VERSION "10.9.1"

NS_ :

BS_:

BU_: ACM ADAS_Body APM ASU_Gateway BCM BCM_BPM CCU_F CCU_R DUMMY_BCM_BPM DUMMY_ECU ETG LDM_L LDM_R OCS_P PSM_D SHVU_F SHVU_R TRM XGW_Body

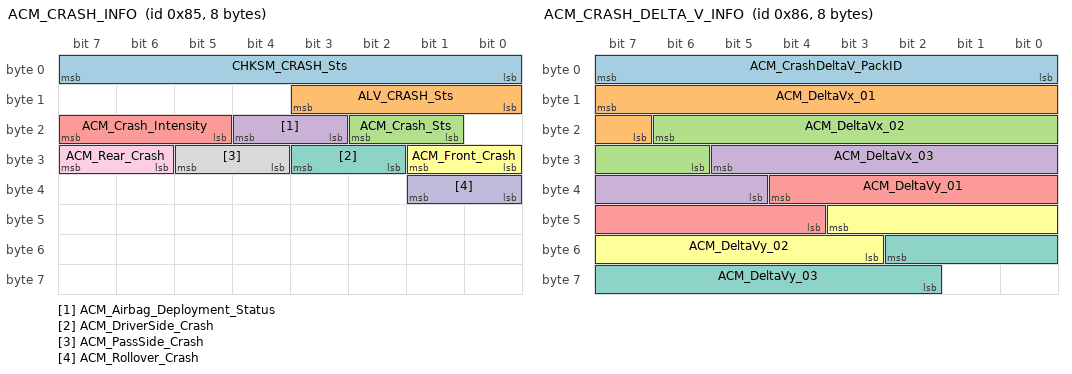
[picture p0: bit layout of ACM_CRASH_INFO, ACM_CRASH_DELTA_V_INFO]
BO_ 133 ACM_CRASH_INFO: 8 ACM
 SG_ CHKSM_CRASH_Sts : 7|8@0+ (1,0) [0|255] ""  BCM,ETG,XGW_Body
 SG_ ALV_CRASH_Sts : 11|4@0+ (1,0) [0|14] ""  BCM,ETG,XGW_Body
 SG_ ACM_Crash_Sts : 18|2@0+ (1,0) [0|3] ""  BCM,CCU_F,ETG,XGW_Body
 SG_ ACM_Airbag_Deployment_Status : 20|2@0+ (1,0) [0|3] "-"  ETG,XGW_Body
 SG_ ACM_Crash_Intensity : 23|3@0+ (1,0) [0|7] ""  CCU_F,ETG,XGW_Body
 SG_ ACM_Front_Crash : 25|2@0+ (1,0) [0|3] "-"  BCM,ETG,XGW_Body
 SG_ ACM_DriverSide_Crash : 27|2@0+ (1,0) [0|3] ""  BCM,ETG,XGW_Body
 SG_ ACM_PassSide_Crash : 29|2@0+ (1,0) [0|3] "-"  BCM,ETG,XGW_Body
 SG_ ACM_Rear_Crash : 31|2@0+ (1,0) [0|3] "-"  BCM,ETG,XGW_Body
 SG_ ACM_Rollover_Crash : 33|2@0+ (1,0) [0|3] "-"  BCM,ETG,XGW_Body

BO_ 134 ACM_CRASH_DELTA_V_INFO: 8 ACM
 SG_ ACM_CrashDeltaV_PackID : 7|8@0+ (1,0) [1|9] ""  XGW_Body
 SG_ ACM_DeltaVx_01 : 15|9@0+ (1,-250) [-250|250] "Km/h"  XGW_Body
 SG_ ACM_DeltaVx_02 : 22|9@0+ (1,-250) [-250|250] "Km/h"  XGW_Body
 SG_ ACM_DeltaVx_03 : 29|9@0+ (1,-250) [-250|250] "Km/h"  XGW_Body
 SG_ ACM_DeltaVy_01 : 36|9@0+ (1,-250) [-250|250] "Km/h"  XGW_Body
 SG_ ACM_DeltaVy_02 : 43|9@0+ (1,-250) [-250|250] "Km/h"  XGW_Body
 SG_ ACM_DeltaVy_03 : 50|9@0+ (1,-250) [-250|250] "Km/h"  XGW_Body

BO_ 149 IDB_FUNCTION: 8 XGW_Body
 SG_ CHKSM_IDB_FUNCTION : 7|8@0+ (1,0) [0|255] ""  ACM,BCM,DUMMY_ECU
 SG_ ALV_IDB_FUNCTION : 11|4@0+ (1,0) [0|14] ""  ACM,BCM,DUMMY_ECU
 SG_ STAT_ABS : 13|2@0+ (1,0) [0|3] ""  DUMMY_ECU
 SG_ ABS_Active : 15|2@0+ (1,0) [0|3] ""  DUMMY_ECU
 SG_ AYC_Active : 17|2@0+ (1,0) [0|3] "Bit"  DUMMY_ECU
 SG_ ASR_Active : 19|2@0+ (1,0) [0|3] "-"  DUMMY_ECU
 SG_ STAT_DSC : 21|2@0+ (1,0) [0|3] "-"  ACM
 SG_ DSC_Active : 23|2@0+ (1,0) [0|3] ""  DUMMY_ECU
 SG_ HBA_ActiveSignal : 25|2@0+ (1,0) [0|3] ""  DUMMY_ECU
 SG_ ARM_ActiveSignal : 27|2@0+ (1,0) [0|3] "-"  DUMMY_ECU
 SG_ STAT_AutoHazardBlinking : 29|2@0+ (1,0) [0|3] "Bit"  BCM
 SG_ MSR_Active : 31|2@0+ (1,0) [0|3] "-"  DUMMY_ECU
 SG_ HSA_ActiveSignal : 33|2@0+ (1,0) [0|3] ""  DUMMY_ECU
 SG_ EPBi_ECD_ActiveSignal : 35|2@0+ (1,0) [0|3] ""  DUMMY_ECU
 SG_ TSM_Active : 37|2@0+ (1,0) [0|3] "-"  DUMMY_ECU
 SG_ HAS_Available : 41|2@0+ (1,0) [0|3] ""  DUMMY_ECU
 SG_ STAT_EBD : 43|2@0+ (1,0) [0|3] ""  DUMMY_ECU
 SG_ EBD_Active : 45|2@0+ (1,0) [0|3] ""  DUMMY_ECU
 SG_ ST_BRG_MSA : 55|4@0+ (1,0) [0|15] ""  DUMMY_ECU

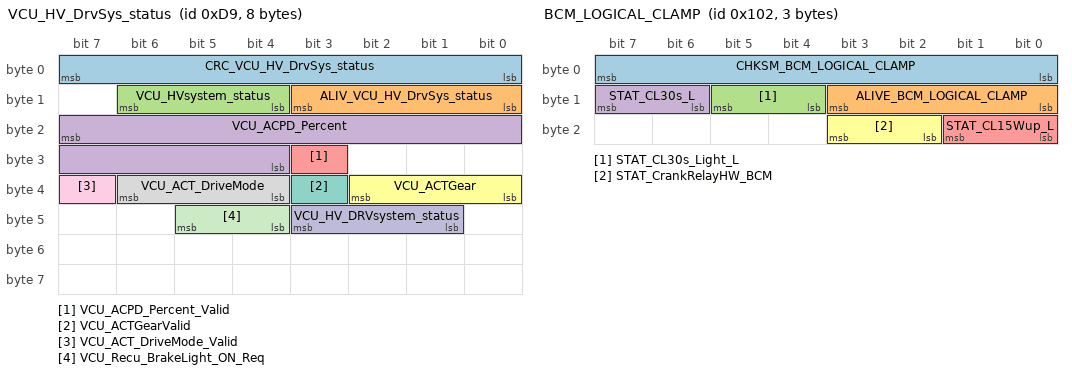
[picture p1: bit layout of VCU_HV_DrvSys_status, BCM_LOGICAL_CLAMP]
BO_ 217 VCU_HV_DrvSys_status: 8 XGW_Body
 SG_ CRC_VCU_HV_DrvSys_status : 7|8@0+ (1,0) [0|255] ""  ACM,BCM,LDM_L,LDM_R
 SG_ ALIV_VCU_HV_DrvSys_status : 11|4@0+ (1,0) [0|14] ""  ACM,BCM,LDM_L,LDM_R
 SG_ VCU_HVsystem_status : 14|3@0+ (1,0) [0|7] "-"  ACM,BCM
 SG_ VCU_ACPD_Percent : 23|12@0+ (0.0625,0) [0|100] "%"  ACM
 SG_ VCU_ACPD_Percent_Valid : 27|1@0+ (1,0) [0|1] ""  ACM
 SG_ VCU_ACTGear : 34|3@0+ (1,0) [0|7] ""  BCM,LDM_L,LDM_R
 SG_ VCU_ACTGearValid : 35|1@0+ (1,0) [0|1] ""  BCM,LDM_L,LDM_R
 SG_ VCU_ACT_DriveMode : 38|3@0+ (1,0) [0|7] ""  BCM
 SG_ VCU_ACT_DriveMode_Valid : 39|1@0+ (1,0) [0|1] "-"  BCM
 SG_ VCU_HV_DRVsystem_status : 43|3@0+ (1,0) [0|7] ""  BCM
 SG_ VCU_Recu_BrakeLight_ON_Req : 45|2@0+ (1,0) [0|3] "-"  BCM

BO_ 256 MHU_Vehicle_Info: 8 XGW_Body
 SG_ CHKSM_MHU_VEH_INFO : 7|8@0+ (1,0) [0|255] ""  BCM
 SG_ ALV_MHU_VEH_INFO : 11|4@0+ (1,0) [0|14] ""  BCM
 SG_ MHU_UserProfileId : 23|4@0+ (1,0) [0|15] "-"  BCM
 SG_ MHU_Connectivity_Status : 47|3@0+ (1,0) [0|7] ""  BCM

BO_ 258 BCM_LOGICAL_CLAMP: 3 BCM
 SG_ CHKSM_BCM_LOGICAL_CLAMP : 7|8@0+ (1,0) [0|255] ""  ASU_Gateway,XGW_Body
 SG_ ALIVE_BCM_LOGICAL_CLAMP : 11|4@0+ (1,0) [0|14] ""  ASU_Gateway,XGW_Body
 SG_ STAT_CL30s_Light_L : 13|2@0+ (1,0) [0|3] ""  XGW_Body
 SG_ STAT_CL30s_L : 15|2@0+ (1,0) [0|3] "Bit"  ASU_Gateway,XGW_Body
 SG_ STAT_CL15Wup_L : 17|2@0+ (1,0) [0|3] "Bit"  ASU_Gateway,XGW_Body
 SG_ STAT_CrankRelayHW_BCM : 19|2@0+ (1,0) [0|3] "Bit"  XGW_Body

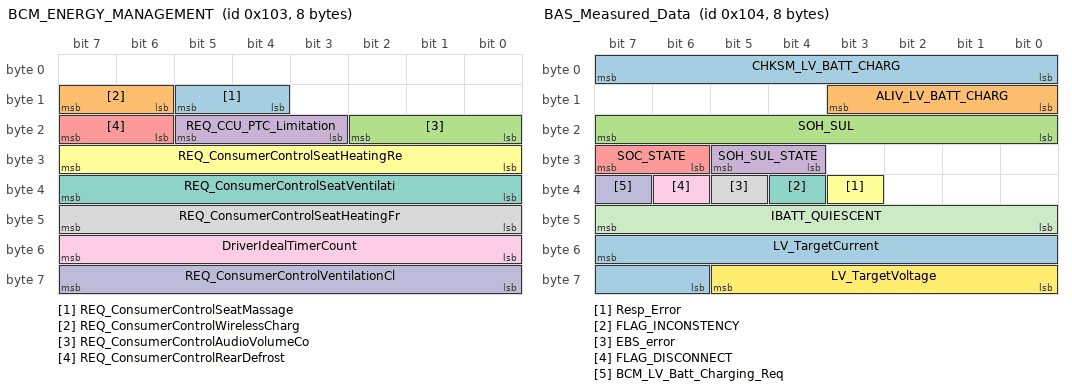
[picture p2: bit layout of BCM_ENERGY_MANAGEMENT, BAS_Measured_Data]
BO_ 259 BCM_ENERGY_MANAGEMENT: 8 BCM
 SG_ REQ_ConsumerControlSeatMassage : 13|2@0+ (1,0) [0|3] "" XGW_Body
 SG_ REQ_ConsumerControlWirelessCharg : 15|2@0+ (1,0) [0|3] "-"  XGW_Body
 SG_ REQ_ConsumerControlAudioVolumeCo : 18|3@0+ (1,0) [0|7] "-"  XGW_Body
 SG_ REQ_CCU_PTC_Limitation : 21|3@0+ (1,0) [0|7] ""  CCU_F,CCU_R
 SG_ REQ_ConsumerControlRearDefrost : 23|2@0+ (1,0) [0|3] "-"  CCU_F,CCU_R,XGW_Body
 SG_ REQ_ConsumerControlSeatHeatingRe : 31|8@0+ (1,0) [0|100] "%"  SHVU_F,SHVU_R,XGW_Body
 SG_ REQ_ConsumerControlSeatVentilati : 39|8@0+ (1,0) [0|100] "%"  SHVU_F,SHVU_R,XGW_Body
 SG_ REQ_ConsumerControlSeatHeatingFr : 47|8@0+ (1,0) [0|100] "%"  SHVU_F,SHVU_R,XGW_Body
 SG_ DriverIdealTimerCount : 55|8@0+ (5,0) [0|1275] "s"  XGW_Body
 SG_ REQ_ConsumerControlVentilationCl : 63|8@0+ (1,0) [0|100] "%"  CCU_F,CCU_R,SHVU_F,SHVU_R,XGW_Body

BO_ 260 BAS_Measured_Data: 8 BCM
 SG_ CHKSM_LV_BATT_CHARG : 7|8@0+ (1,0) [0|255] ""  XGW_Body
 SG_ ALIV_LV_BATT_CHARG : 11|4@0+ (1,0) [0|14] ""  XGW_Body
 SG_ SOH_SUL : 23|8@0+ (1,0) [0|100] "%"  XGW_Body
 SG_ SOH_SUL_STATE : 29|2@0+ (1,0) [0|3] ""  XGW_Body
 SG_ SOC_STATE : 31|2@0+ (1,0) [0|3] "%"  XGW_Body
 SG_ Resp_Error : 35|1@0+ (1,0) [0|1] ""  XGW_Body
 SG_ FLAG_INCONSTENCY : 36|1@0+ (1,0) [0|1] "%"  XGW_Body
 SG_ EBS_error : 37|1@0+ (1,0) [0|1] ""  XGW_Body
 SG_ FLAG_DISCONNECT : 38|1@0+ (1,0) [0|1] ""  XGW_Body
 SG_ BCM_LV_Batt_Charging_Req : 39|1@0+ (1,0) [0|1] ""  XGW_Body
 SG_ IBATT_QUIESCENT : 47|8@0+ (0.00390625,0) [0|0.984375] ""  DUMMY_ECU
 SG_ LV_TargetVoltage : 61|6@0+ (0.112903,9) [9|16] "V" XGW_Body
 SG_ LV_TargetCurrent : 55|10@0+ (0.25,-128) [-128|127] "A" XGW_Body

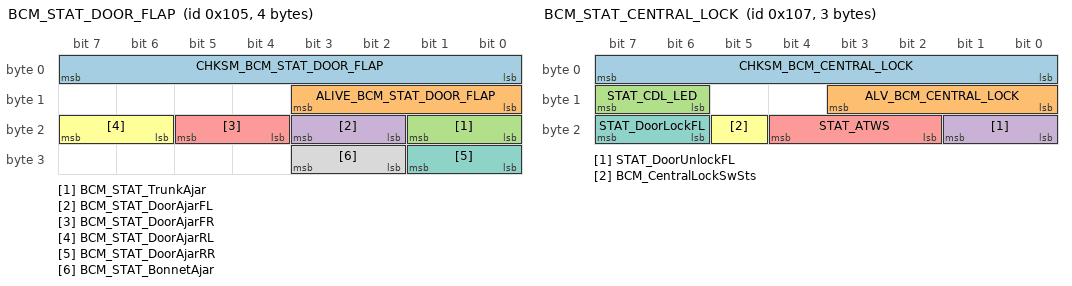
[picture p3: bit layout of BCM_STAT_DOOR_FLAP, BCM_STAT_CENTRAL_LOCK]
BO_ 261 BCM_STAT_DOOR_FLAP: 4 BCM
 SG_ CHKSM_BCM_STAT_DOOR_FLAP : 7|8@0+ (1,0) [0|255] ""  ADAS_Body,APM,ASU_Gateway,CCU_F,CCU_R,XGW_Body
 SG_ ALIVE_BCM_STAT_DOOR_FLAP : 11|4@0+ (1,0) [0|14] ""  ADAS_Body,APM,ASU_Gateway,CCU_F,CCU_R,XGW_Body
 SG_ BCM_STAT_TrunkAjar : 17|2@0+ (1,0) [0|3] "Bit"  ADAS_Body,APM,ASU_Gateway,CCU_R,XGW_Body
 SG_ BCM_STAT_DoorAjarFL : 19|2@0+ (1,0) [0|3] "Bit"  ADAS_Body,APM,ASU_Gateway,CCU_F,CCU_R,XGW_Body
 SG_ BCM_STAT_DoorAjarFR : 21|2@0+ (1,0) [0|3] "Bit"  ADAS_Body,APM,ASU_Gateway,CCU_F,CCU_R,XGW_Body
 SG_ BCM_STAT_DoorAjarRL : 23|2@0+ (1,0) [0|3] "Bit"  ADAS_Body,APM,ASU_Gateway,CCU_F,CCU_R,XGW_Body
 SG_ BCM_STAT_DoorAjarRR : 25|2@0+ (1,0) [0|3] "Bit"  ADAS_Body,APM,ASU_Gateway,CCU_F,CCU_R,XGW_Body
 SG_ BCM_STAT_BonnetAjar : 27|2@0+ (1,0) [0|3] "Bit"  ADAS_Body,APM,XGW_Body

BO_ 262 BCM_LIGHT: 8 BCM
 SG_ CHKSM_BCM_LIGHT : 7|8@0+ (1,0) [0|255] ""  ADAS_Body,APM,CCU_F,LDM_L,LDM_R,XGW_Body
 SG_ ALIVE_BCM_LIGHT : 11|4@0+ (1,0) [0|14] ""  ADAS_Body,APM,CCU_F,LDM_L,LDM_R,XGW_Body
 SG_ BCM_DayRunningLampSts : 13|2@0+ (1,0) [0|3] ""  ADAS_Body,LDM_L,LDM_R,XGW_Body
 SG_ BCM_ReverseLightSts : 15|2@0+ (1,0) [0|3] ""  ADAS_Body,TRM,XGW_Body
 SG_ BCM_StopLightSts : 17|2@0+ (1,0) [0|3] ""  ADAS_Body,TRM,XGW_Body
 SG_ BCM_LicensePlateLightSts : 19|2@0+ (1,0) [0|3] ""  ADAS_Body,XGW_Body
 SG_ BCM_Fr_Dimming_dome_lampSts : 21|2@0+ (1,0) [0|3] ""  ADAS_Body,XGW_Body
 SG_ BCM_Rr_Dimming_dome_lampSts : 23|2@0+ (1,0) [0|3] ""  ADAS_Body,XGW_Body
 SG_ BCM_STAT_InteriorLight : 25|2@0+ (1,0) [0|3] "Bit"  ADAS_Body,XGW_Body
 SG_ BCM_STAT_LightActivation : 28|3@0+ (1,0) [0|7] "-"  ADAS_Body,LDM_L,LDM_R,TRM,XGW_Body
 SG_ BCM_HighBeamSts : 31|2@0+ (1,0) [0|3] ""  ADAS_Body,LDM_L,LDM_R,TRM,XGW_Body
 SG_ BCM_STAT_SwitchLightBrightness : 39|7@0+ (1,0) [0|100] "%"  ADAS_Body,XGW_Body
 SG_ BCM_LowBeamSts : 41|2@0+ (1,0) [0|3] "-"  ADAS_Body,LDM_L,LDM_R,TRM,XGW_Body
 SG_ BCM_RearFogLmpSts : 43|2@0+ (1,0) [0|3] "-"  ADAS_Body,TRM,XGW_Body
 SG_ BCM_FrntFogLmpSts : 45|2@0+ (1,0) [0|3] ""  ADAS_Body,XGW_Body
 SG_ BCM_PosLmpSts : 47|2@0+ (1,0) [0|3] "-"  ADAS_Body,LDM_L,LDM_R,TRM,XGW_Body
 SG_ BCM_BackGrdCl58Sts : 51|2@0+ (1,0) [0|3] ""  DUMMY_ECU
 SG_ BCM_HornSts : 53|2@0+ (1,0) [0|3] ""  XGW_Body
 SG_ BCM_TurnIndicatorSts : 55|2@0+ (1,0) [0|3] ""  ADAS_Body,LDM_L,LDM_R,TRM,XGW_Body

BO_ 263 BCM_STAT_CENTRAL_LOCK: 3 BCM
 SG_ CHKSM_BCM_CENTRAL_LOCK : 7|8@0+ (1,0) [0|255] ""  ADAS_Body,ASU_Gateway,XGW_Body
 SG_ ALV_BCM_CENTRAL_LOCK : 11|4@0+ (1,0) [0|14] ""  ADAS_Body,ASU_Gateway,XGW_Body
 SG_ STAT_CDL_LED : 15|2@0+ (1,0) [0|3] "-"  XGW_Body
 SG_ STAT_DoorUnlockFL : 17|2@0+ (1,0) [0|3] "Bit"  XGW_Body
 SG_ STAT_ATWS : 20|3@0+ (1,0) [0|7] "Bit"  ADAS_Body,XGW_Body
 SG_ BCM_CentralLockSwSts : 21|1@0+ (1,0) [0|0] ""  DUMMY_ECU
 SG_ STAT_DoorLockFL : 23|2@0+ (1,0) [0|3] "Bit"  ADAS_Body,ASU_Gateway,XGW_Body

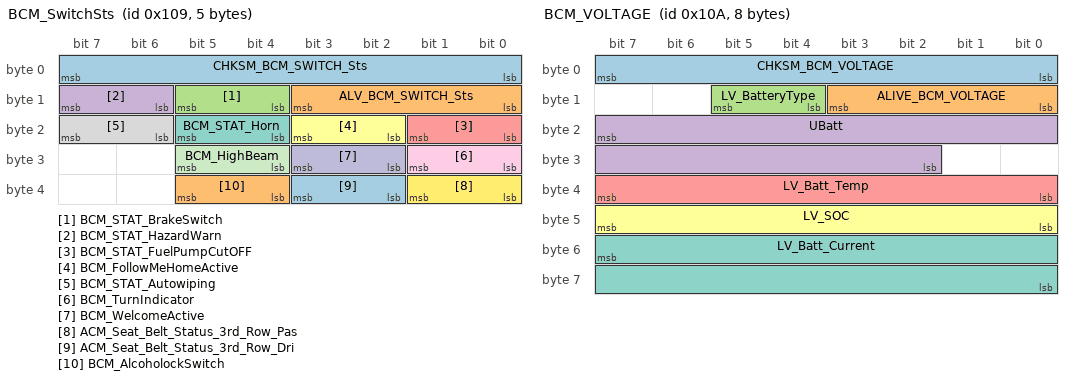
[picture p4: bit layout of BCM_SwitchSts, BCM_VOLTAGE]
BO_ 265 BCM_SwitchSts: 5 BCM
 SG_ CHKSM_BCM_SWITCH_Sts : 7|8@0+ (1,0) [0|255] ""  ACM,ADAS_Body,LDM_L,LDM_R,TRM,XGW_Body
 SG_ ALV_BCM_SWITCH_Sts : 11|4@0+ (1,0) [0|14] ""  ACM,ADAS_Body,LDM_L,LDM_R,TRM,XGW_Body
 SG_ BCM_STAT_BrakeSwitch : 13|2@0+ (1,0) [0|3] ""  ACM,ADAS_Body,TRM,XGW_Body
 SG_ BCM_STAT_HazardWarn : 15|2@0+ (1,0) [0|3] "-"  ADAS_Body,LDM_L,LDM_R,TRM,XGW_Body
 SG_ BCM_STAT_FuelPumpCutOFF : 17|2@0+ (1,0) [0|3] ""  XGW_Body
 SG_ BCM_FollowMeHomeActive : 19|2@0+ (1,0) [0|3] ""  TRM,XGW_Body
 SG_ BCM_STAT_Horn : 21|2@0+ (1,0) [0|3] "-"  XGW_Body
 SG_ BCM_STAT_Autowiping : 23|2@0+ (1,0) [0|3] ""  XGW_Body
 SG_ BCM_TurnIndicator : 25|2@0+ (1,0) [0|3] ""  ADAS_Body,LDM_L,LDM_R,TRM,XGW_Body
 SG_ BCM_WelcomeActive : 27|2@0+ (1,0) [0|3] "-"  TRM,XGW_Body
 SG_ BCM_HighBeam : 29|2@0+ (1,0) [0|3] ""  LDM_L,LDM_R,TRM,XGW_Body
 SG_ ACM_Seat_Belt_Status_3rd_Row_Pas : 33|2@0+ (1,0) [0|3] ""  XGW_Body
 SG_ ACM_Seat_Belt_Status_3rd_Row_Dri : 35|2@0+ (1,0) [0|3] "-"  XGW_Body
 SG_ BCM_AlcoholockSwitch : 37|2@0+ (1,0) [0|3] ""  DUMMY_ECU

BO_ 266 BCM_VOLTAGE: 8 BCM
 SG_ CHKSM_BCM_VOLTAGE : 7|8@0+ (1,0) [0|255] ""  ACM,ADAS_Body,APM,ASU_Gateway,BCM_BPM,CCU_F,CCU_R,ETG,LDM_L,LDM_R,OCS_P,PSM_D,SHVU_F,SHVU_R,TRM,XGW_Body
 SG_ ALIVE_BCM_VOLTAGE : 11|4@0+ (1,0) [0|14] ""  ACM,ADAS_Body,APM,ASU_Gateway,BCM_BPM,CCU_F,CCU_R,ETG,LDM_L,LDM_R,OCS_P,PSM_D,SHVU_F,SHVU_R,TRM,XGW_Body
 SG_ LV_BatteryType : 13|2@0+ (1,0) [0|3] "Number" XGW_Body
 SG_ UBatt : 23|14@0+ (0.0009777,3) [3|18] "V"  ACM,ADAS_Body,APM,ASU_Gateway,BCM_BPM,CCU_F,CCU_R,ETG,LDM_L,LDM_R,OCS_P,PSM_D,SHVU_F,SHVU_R,TRM,XGW_Body
 SG_ LV_Batt_Temp : 39|8@0+ (1,-40) [-40|105] "Degree C"  ACM,ADAS_Body,APM,ASU_Gateway,BCM_BPM,CCU_F,CCU_R,ETG,LDM_L,LDM_R,OCS_P,PSM_D,SHVU_F,SHVU_R,TRM,XGW_Body
 SG_ LV_SOC : 47|8@0+ (1,0) [0|100] "%"  ACM,ADAS_Body,APM,ASU_Gateway,BCM_BPM,CCU_F,CCU_R,ETG,LDM_L,LDM_R,OCS_P,PSM_D,SHVU_F,SHVU_R,TRM,XGW_Body
 SG_ LV_Batt_Current : 55|16@0+ (0.03125,-1536) [-1536|511.90625] "A"  ACM,ADAS_Body,APM,ASU_Gateway,BCM_BPM,CCU_F,CCU_R,ETG,LDM_L,LDM_R,OCS_P,PSM_D,SHVU_F,SHVU_R,TRM,XGW_Body

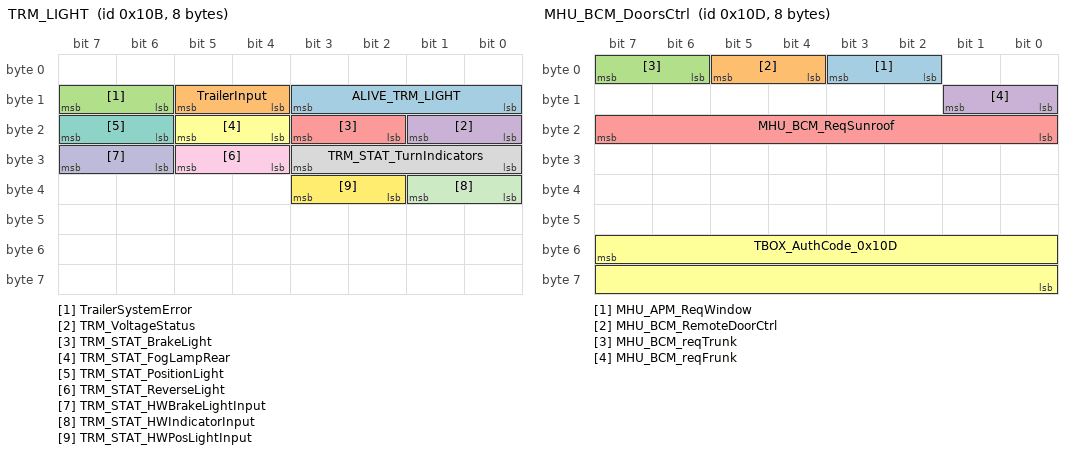
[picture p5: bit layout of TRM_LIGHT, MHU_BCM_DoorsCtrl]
BO_ 267 TRM_LIGHT: 8 TRM
 SG_ ALIVE_TRM_LIGHT : 11|4@0+ (1,0) [0|14] ""  BCM,XGW_Body
 SG_ TrailerInput : 13|2@0+ (1,0) [0|3] ""  BCM,XGW_Body
 SG_ TrailerSystemError : 15|2@0+ (1,0) [0|3] ""  BCM,XGW_Body
 SG_ TRM_VoltageStatus : 17|2@0+ (1,0) [0|3] ""  BCM,XGW_Body
 SG_ TRM_STAT_BrakeLight : 19|2@0+ (1,0) [0|3] ""  BCM,XGW_Body
 SG_ TRM_STAT_FogLampRear : 21|2@0+ (1,0) [0|3] ""  BCM,XGW_Body
 SG_ TRM_STAT_PositionLight : 23|2@0+ (1,0) [0|3] ""  BCM,XGW_Body
 SG_ TRM_STAT_TurnIndicators : 27|4@0+ (1,0) [0|15] ""  BCM,XGW_Body
 SG_ TRM_STAT_ReverseLight : 29|2@0+ (1,0) [0|3] ""  BCM,XGW_Body
 SG_ TRM_STAT_HWBrakeLightInput : 31|2@0+ (1,0) [0|3] ""  BCM,XGW_Body
 SG_ TRM_STAT_HWIndicatorInput : 33|2@0+ (1,0) [0|3] ""  BCM,XGW_Body
 SG_ TRM_STAT_HWPosLightInput : 35|2@0+ (1,0) [0|3] ""  BCM,XGW_Body

BO_ 268 BCM_RemoteCtrlSts: 8 BCM
 SG_ Checksum_0x10C : 7|8@0+ (1,0) [0|255] ""  XGW_Body
 SG_ Rolling_Counter_0x10C : 11|4@0+ (1,0) [0|14] ""  XGW_Body
 SG_ BCM_TboxAuthStatus : 23|2@0+ (1,0) [0|3] "-"  XGW_Body
 SG_ BCM_RandomNum32bit : 31|32@0+ (1,0) [0|4294967295] "-"  XGW_Body

BO_ 269 MHU_BCM_DoorsCtrl: 8 XGW_Body
 SG_ MHU_APM_ReqWindow : 3|2@0+ (1,0) [0|3] "-"  BCM
 SG_ MHU_BCM_RemoteDoorCtrl : 5|2@0+ (1,0) [0|3] "-"  BCM
 SG_ MHU_BCM_reqTrunk : 7|2@0+ (1,0) [0|3] "-"  BCM
 SG_ MHU_BCM_reqFrunk : 9|2@0+ (1,0) [0|3] "-"  BCM
 SG_ MHU_BCM_ReqSunroof : 23|8@0+ (1,0) [0|255] "%"  BCM
 SG_ TBOX_AuthCode_0x10D : 55|16@0+ (1,0) [0|65535] "-"  BCM

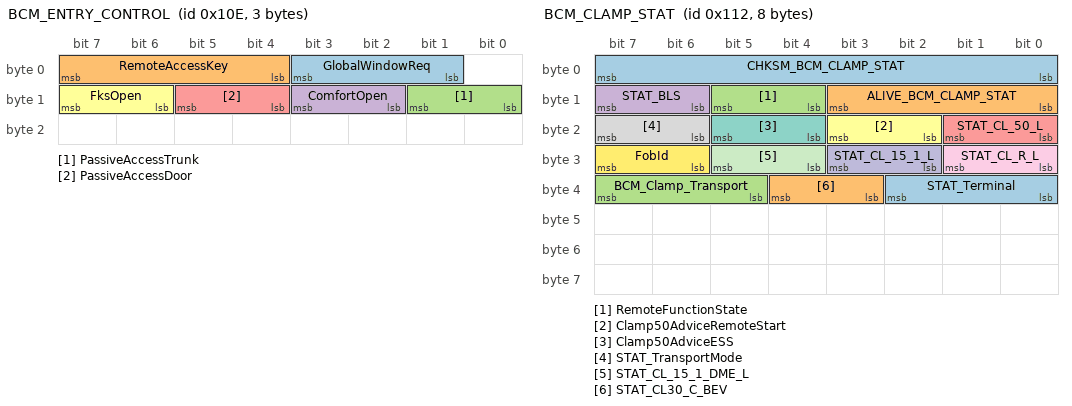
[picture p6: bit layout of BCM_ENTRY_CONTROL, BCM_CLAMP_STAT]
BO_ 270 BCM_ENTRY_CONTROL: 3 BCM
 SG_ GlobalWindowReq : 3|3@0+ (1,0) [0|7] ""  APM
 SG_ RemoteAccessKey : 7|4@0+ (1,0) [0|15] "-"  APM,ETG,XGW_Body
 SG_ PassiveAccessTrunk : 9|2@0+ (1,0) [0|3] "-"  ETG,XGW_Body
 SG_ ComfortOpen : 11|2@0+ (1,0) [0|3] "-"  ETG,XGW_Body
 SG_ PassiveAccessDoor : 13|2@0+ (1,0) [0|3] "-"  APM,ETG,XGW_Body
 SG_ FksOpen : 15|2@0+ (1,0) [0|3] ""  ETG,XGW_Body

BO_ 271 MHU_BCM_HornLightControl: 8 XGW_Body
 SG_ MHU_SetHornOnOff : 3|2@0+ (1,0) [0|3] "-"  BCM
 SG_ MHU_SetLowBeam : 5|2@0+ (1,0) [0|3] ""  BCM
 SG_ MHU_SetHighBeam : 7|2@0+ (1,0) [0|3] ""  BCM
 SG_ TBOX_AuthCode_0x10F : 55|16@0+ (1,0) [0|65535] "-"  BCM

BO_ 273 BCM_Stat_SwitchLightBrightness: 8 BCM
 SG_ BCM_Stat_SwitchLightBrightness : 7|8@0+ (0.4,0) [0|102] ""  XGW_Body
 SG_ BCM_Rear_Wiper_Park_Pos_Status : 32|1@0+ (1,0) [0|1] ""  DUMMY_ECU
 SG_ BCM_Front_Wiper_Park_Pos_Status : 33|1@0+ (1,0) [0|1] ""  DUMMY_ECU
 SG_ BCM_Rear_Wash_Status : 34|1@0+ (1,0) [0|1] ""  DUMMY_ECU
 SG_ BCM_Front_Wash_Status : 35|1@0+ (1,0) [0|1] ""  DUMMY_ECU

BO_ 274 BCM_CLAMP_STAT: 8 BCM
 SG_ CHKSM_BCM_CLAMP_STAT : 7|8@0+ (1,0) [0|255] ""  ACM,ADAS_Body,APM,ASU_Gateway,BCM_BPM,CCU_F,CCU_R,ETG,LDM_L,LDM_R,OCS_P,PSM_D,SHVU_F,SHVU_R,TRM,XGW_Body
 SG_ ALIVE_BCM_CLAMP_STAT : 11|4@0+ (1,0) [0|14] ""  ACM,ADAS_Body,APM,ASU_Gateway,BCM_BPM,CCU_F,CCU_R,ETG,LDM_L,LDM_R,OCS_P,PSM_D,SHVU_F,SHVU_R,TRM,XGW_Body
 SG_ RemoteFunctionState : 13|2@0+ (1,0) [0|3] ""  ACM,ADAS_Body,APM,ASU_Gateway,BCM_BPM,CCU_F,CCU_R,ETG,LDM_L,LDM_R,OCS_P,PSM_D,SHVU_F,SHVU_R,TRM,XGW_Body
 SG_ STAT_BLS : 15|2@0+ (1,0) [0|3] "-"  ACM,ADAS_Body,APM,ASU_Gateway,BCM_BPM,CCU_F,CCU_R,ETG,LDM_L,LDM_R,OCS_P,PSM_D,SHVU_F,SHVU_R,TRM,XGW_Body
 SG_ STAT_CL_50_L : 17|2@0+ (1,0) [0|3] ""  ACM,ADAS_Body,APM,ASU_Gateway,BCM_BPM,CCU_F,CCU_R,ETG,LDM_L,LDM_R,OCS_P,PSM_D,SHVU_F,SHVU_R,TRM,XGW_Body
 SG_ Clamp50AdviceRemoteStart : 19|2@0+ (1,0) [0|3] "-"  ACM,ADAS_Body,APM,ASU_Gateway,BCM_BPM,CCU_F,CCU_R,ETG,LDM_L,LDM_R,OCS_P,PSM_D,SHVU_F,SHVU_R,TRM,XGW_Body
 SG_ Clamp50AdviceESS : 21|2@0+ (1,0) [0|3] "-"  ACM,ADAS_Body,APM,ASU_Gateway,BCM_BPM,CCU_F,CCU_R,ETG,LDM_L,LDM_R,OCS_P,PSM_D,SHVU_F,SHVU_R,TRM,XGW_Body
 SG_ STAT_TransportMode : 23|2@0+ (1,0) [0|3] "" XGW_Body
 SG_ STAT_CL_R_L : 25|2@0+ (1,0) [0|3] ""  ACM,ADAS_Body,APM,ASU_Gateway,BCM_BPM,CCU_F,CCU_R,ETG,LDM_L,LDM_R,OCS_P,PSM_D,SHVU_F,SHVU_R,TRM,XGW_Body
 SG_ STAT_CL_15_1_L : 27|2@0+ (1,0) [0|3] "-"  ACM,ADAS_Body,APM,ASU_Gateway,BCM_BPM,CCU_F,CCU_R,ETG,LDM_L,LDM_R,OCS_P,PSM_D,SHVU_F,SHVU_R,TRM,XGW_Body
 SG_ STAT_CL_15_1_DME_L : 29|2@0+ (1,0) [0|3] ""  ACM,ADAS_Body,APM,ASU_Gateway,BCM_BPM,CCU_F,CCU_R,ETG,LDM_L,LDM_R,OCS_P,PSM_D,SHVU_F,SHVU_R,TRM,XGW_Body
 SG_ FobId : 31|2@0+ (1,0) [0|3] "Bit"  ACM,ADAS_Body,APM,ASU_Gateway,BCM_BPM,CCU_F,CCU_R,ETG,LDM_L,LDM_R,OCS_P,PSM_D,SHVU_F,SHVU_R,TRM,XGW_Body
 SG_ STAT_Terminal : 34|3@0+ (1,0) [0|7] "Bit"  ACM,ADAS_Body,APM,ASU_Gateway,BCM_BPM,CCU_F,CCU_R,ETG,LDM_L,LDM_R,OCS_P,PSM_D,SHVU_F,SHVU_R,TRM,XGW_Body
 SG_ STAT_CL30_C_BEV : 36|2@0+ (1,0) [0|3] "Bit"  ACM,ADAS_Body,APM,ASU_Gateway,BCM_BPM,CCU_F,CCU_R,ETG,LDM_L,LDM_R,OCS_P,PSM_D,SHVU_F,SHVU_R,TRM,XGW_Body
 SG_ BCM_Clamp_Transport : 39|3@0+ (1,0) [0|7] ""  ACM,ADAS_Body,APM,ASU_Gateway,BCM_BPM,CCU_F,CCU_R,ETG,LDM_L,LDM_R,OCS_P,PSM_D,SHVU_F,SHVU_R,TRM,XGW_Body

BO_ 276 BCM_LVBAT_Data: 8 BCM
 SG_ CHKSM_LVBAT_DATA : 7|8@0+ (1,0) [0|255] "" XGW_Body
 SG_ ALIV_LVBAT_DATA : 11|4@0+ (1,0) [0|14] "" XGW_Body
 SG_ LV_ErrorSts : 14|3@0+ (1,0) [0|7] "" XGW_Body
 SG_ LV_MinCellVolt : 23|8@0+ (0.015625,1) [1|5] "V" XGW_Body
 SG_ LV_MaxCellVolt : 31|8@0+ (0.015625,1) [1|5] "V" XGW_Body
 SG_ LV_MinCellTemp : 39|8@0+ (1,-40) [-40|215] "Degree C" XGW_Body
 SG_ LV_MaxCellTemp : 47|8@0+ (1,-40) [-40|215] "Degree C" XGW_Body
 SG_ LV_Discharger_Err : 48|1@0+ (1,0) [0|1] "" XGW_Body
 SG_ LV_Discharger_Sts : 49|1@0+ (1,0) [0|1] "" XGW_Body
 SG_ LV_Charger_Err : 50|1@0+ (1,0) [0|1] "" XGW_Body
 SG_ LV_Charger_Sts : 51|1@0+ (1,0) [0|1] "" XGW_Body
 SG_ LV_OverVoltage : 52|1@0+ (1,0) [0|1] "" XGW_Body
 SG_ LV_UnderVoltage : 53|1@0+ (1,0) [0|1] "" XGW_Body
 SG_ LV_OverCurrent : 54|1@0+ (1,0) [0|1] "" XGW_Body
 SG_ LV_UnderTemp : 55|1@0+ (1,0) [0|1] "" XGW_Body
 SG_ LV_OverTemp : 56|1@0+ (1,0) [0|1] "" XGW_Body
 SG_ LV_OverCharge : 57|1@0+ (1,0) [0|1] "" XGW_Body
 SG_ LV_OverDischarge : 58|1@0+ (1,0) [0|1] "" XGW_Body
 SG_ LV_CellBalance_Sts : 59|1@0+ (1,0) [0|1] "" XGW_Body
 SG_ LV_CellBalance_Error : 60|1@0+ (1,0) [0|1] "" XGW_Body
 SG_ LV_ThermalRunaway : 61|1@0+ (1,0) [0|1] "" XGW_Body
 SG_ LV_WarmupRequest : 63|2@0+ (1,0) [0|3] "" XGW_Body

BO_ 277 BCM_Childlock: 8 BCM
 SG_ BCM_ChildLock_Feedback : 7|2@0+ (1,0) [0|3] ""  XGW_Body

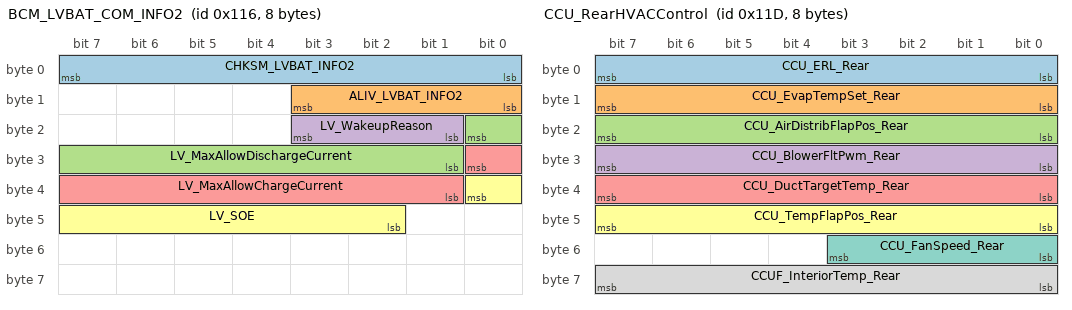
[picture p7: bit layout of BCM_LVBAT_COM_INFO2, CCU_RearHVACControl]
BO_ 278 BCM_LVBAT_COM_INFO2: 8 BCM
 SG_ CHKSM_LVBAT_INFO2 : 7|8@0+ (1,0) [0|255] "" XGW_Body
 SG_ ALIV_LVBAT_INFO2 : 11|4@0+ (1,0) [0|14] "" XGW_Body
 SG_ LV_MaxAllowDischargeCurrent : 16|8@0+ (1,0) [0|253] "A" XGW_Body
 SG_ LV_WakeupReason : 19|3@0+ (1,0) [0|7] "" XGW_Body
 SG_ LV_MaxAllowChargeCurrent : 24|8@0+ (1,0) [0|253] "A" XGW_Body
 SG_ LV_SOE : 32|7@0+ (1,0) [0|100] "%" XGW_Body

BO_ 280 BCM_MHU_Ctrl_Fbk: 8 BCM
 SG_ CHKSM_BCM_MHU_Ctrl_Fbk : 7|8@0+ (1,0) [0|255] "" XGW_Body
 SG_ ALV_BCM_MHU_Ctrl_Fbk : 11|4@0+ (1,0) [0|14] "" XGW_Body
 SG_ BCM_DrvInhibitStsFbk : 13|2@0+ (1,0) [0|3] "" XGW_Body

BO_ 282 MHU_ServiceMode_Setting: 8 XGW_Body
 SG_ MHU_SET_WiperServicePositionMod : 5|2@0+ (1,0) [0|3] ""  BCM
 SG_ MHU_Read_KeyFobOnCenterConsole : 7|2@0+ (1,0) [0|3] ""  BCM

BO_ 283 MHU_BCM_RemoteClampCtrl: 8 XGW_Body
 SG_ TBOX_STAT_TerminalReq : 7|3@0+ (1,0) [0|7] "-"  BCM
 SG_ TBOX_AuthCode_0x11B : 55|16@0+ (1,0) [0|65535] ""  BCM

BO_ 284 MHU_BCM_FOTAClampCtrl: 8 XGW_Body
 SG_ TBOX_FOTA_STAT_TerminalReq : 7|3@0+ (1,0) [0|7] "-"  BCM

BO_ 285 CCU_RearHVACControl: 8 CCU_F
 SG_ CCU_ERL_Rear : 7|8@0+ (1,0) [0|255] ""  CCU_R
 SG_ CCU_EvapTempSet_Rear : 15|8@0+ (0.1,-5) [-5|20.5] "Degree C"  CCU_R
 SG_ CCU_AirDistribFlapPos_Rear : 23|8@0+ (0.5,0) [0|100] "%"  CCU_R
 SG_ CCU_BlowerFltPwm_Rear : 31|8@0+ (0.5,0) [0|100] "%"  CCU_R
 SG_ CCU_DuctTargetTemp_Rear : 39|8@0+ (0.5,-40) [-40|85] "Degree C"  CCU_R
 SG_ CCU_TempFlapPos_Rear : 47|8@0+ (0.5,0) [0|100] "%"  CCU_R
 SG_ CCU_FanSpeed_Rear : 51|4@0+ (1,0) [0|15] "%"  CCU_R
 SG_ CCUF_InteriorTemp_Rear : 63|8@0+ (0.5,-40) [-40|85] "Degree C"  DUMMY_ECU

BO_ 286 CCUR_SensorInfo: 8 CCU_R
 SG_ CCUR_DuctActRearFace : 7|8@0+ (0.5,-40) [-40|85] "Degree C"  CCU_F
 SG_ CCUR_DuctActRearFoot : 15|8@0+ (0.5,-40) [-40|85] "Degree C"  CCU_F
 SG_ CCUR_EvaporatorTemp : 23|8@0+ (0.5,-40) [-40|85] "Degree C"  CCU_F
 SG_ CCUR_InteriorTemp : 31|8@0+ (0.5,-40) [-40|85] "Degree C"  CCU_F
 SG_ CCUR_AirDistribFeedback_Rear : 39|8@0+ (0.5,0) [0|5] "V"  CCU_F
 SG_ CCUR_TempFeedback_Rear : 47|8@0+ (0.5,0) [0|5] "V"  CCU_F
 SG_ CCUR_BlowerFeedback_Rear : 55|8@0+ (0.5,0) [0|5] "V"  CCU_F

BO_ 287 MHU_BCM_Ctrl: 8 XGW_Body
 SG_ MHU_DrvInhibitSts : 13|2@0+ (1,0) [0|3] "" BCM
 SG_ TBOX_AuthCode_0x11F : 55|16@0+ (1,0) [0|65535] "" BCM

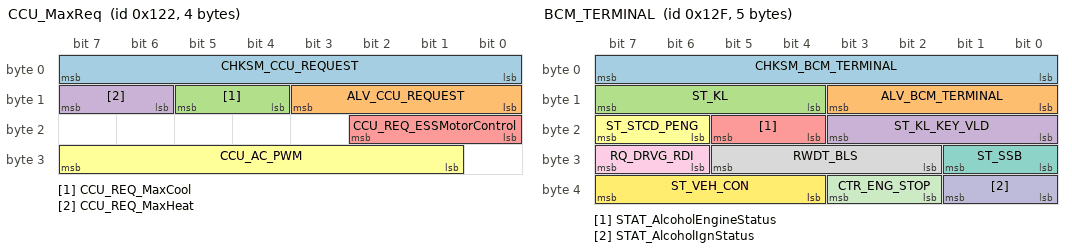
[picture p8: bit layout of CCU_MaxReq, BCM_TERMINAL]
BO_ 290 CCU_MaxReq: 4 CCU_F
 SG_ CHKSM_CCU_REQUEST : 7|8@0+ (1,0) [0|255] ""  XGW_Body
 SG_ ALV_CCU_REQUEST : 11|4@0+ (1,0) [0|14] ""  XGW_Body
 SG_ CCU_REQ_MaxCool : 13|2@0+ (1,0) [0|3] ""  XGW_Body
 SG_ CCU_REQ_MaxHeat : 15|2@0+ (1,0) [0|3] ""  XGW_Body
 SG_ CCU_REQ_ESSMotorControl : 18|3@0+ (1,0) [0|7] "Bit"  XGW_Body
 SG_ CCU_AC_PWM : 31|7@0+ (1,0) [0|100] "%"  XGW_Body

BO_ 303 BCM_TERMINAL: 5 BCM
 SG_ CHKSM_BCM_TERMINAL : 7|8@0+ (1,0) [0|255] ""  XGW_Body
 SG_ ALV_BCM_TERMINAL : 11|4@0+ (1,0) [0|14] ""  XGW_Body
 SG_ ST_KL : 15|4@0+ (1,0) [0|15] "-"  XGW_Body
 SG_ ST_KL_KEY_VLD : 19|4@0+ (1,0) [0|15] ""  XGW_Body
 SG_ STAT_AlcoholEngineStatus : 21|2@0+ (1,0) [0|3] ""  XGW_Body
 SG_ ST_STCD_PENG : 23|2@0+ (1,0) [0|3] ""  XGW_Body
 SG_ ST_SSB : 25|2@0+ (1,0) [0|3] "-"  XGW_Body
 SG_ RWDT_BLS : 29|4@0+ (1,0) [0|15] "-"  XGW_Body
 SG_ RQ_DRVG_RDI : 31|2@0+ (1,0) [0|3] ""  XGW_Body
 SG_ STAT_AlcoholIgnStatus : 33|2@0+ (1,0) [0|3] ""  XGW_Body
 SG_ CTR_ENG_STOP : 35|2@0+ (1,0) [0|3] "Bit"  XGW_Body
 SG_ ST_VEH_CON : 39|4@0+ (1,0) [0|15] "-"  XGW_Body

BO_ 359 VCU_TWV1_Frm: 8 XGW_Body
 SG_ TWV1_N_Position : 7|16@0+ (0.1,0) [0|100] "%"  CCU_F
 SG_ TWV1_St_Feedback : 23|16@0+ (1,0) [0|15] ""  CCU_F
 SG_ TWV1_Frm_Error : 39|1@0+ (1,0) [0|1] ""  CCU_F

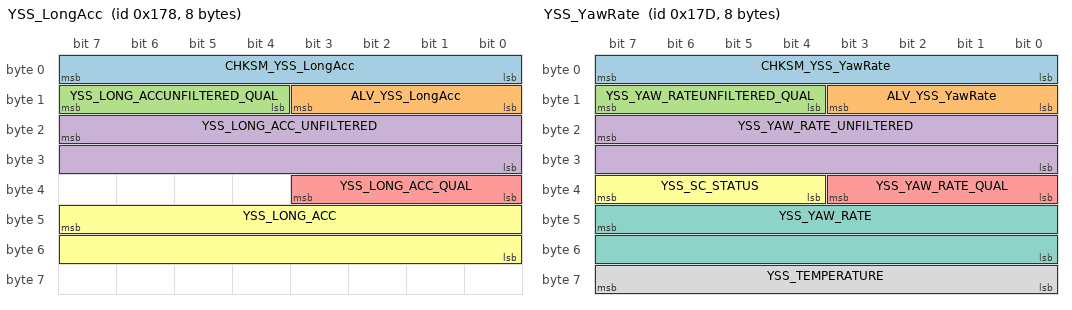
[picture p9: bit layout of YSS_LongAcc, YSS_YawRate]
BO_ 376 YSS_LongAcc: 8 XGW_Body
 SG_ CHKSM_YSS_LongAcc : 7|8@0+ (1,0) [0|255] ""  ASU_Gateway
 SG_ ALV_YSS_LongAcc : 11|4@0+ (1,0) [0|14] ""  ASU_Gateway
 SG_ YSS_LONG_ACCUNFILTERED_QUAL : 15|4@0+ (1,0) [0|15] ""  ASU_Gateway
 SG_ YSS_LONG_ACC_UNFILTERED : 23|16@0+ (0.002,-65.532) [-65.532|65.532] "m/s2"  ASU_Gateway
 SG_ YSS_LONG_ACC_QUAL : 35|4@0+ (1,0) [0|15] ""  ASU_Gateway
 SG_ YSS_LONG_ACC : 47|16@0+ (0.002,-65.532) [-65.532|65.532] "m/s2"  ASU_Gateway

BO_ 381 YSS_YawRate: 8 XGW_Body
 SG_ CHKSM_YSS_YawRate : 7|8@0+ (1,0) [0|255] ""  ASU_Gateway
 SG_ ALV_YSS_YawRate : 11|4@0+ (1,0) [0|14] ""  ASU_Gateway
 SG_ YSS_YAW_RATEUNFILTERED_QUAL : 15|4@0+ (1,0) [0|15] ""  ASU_Gateway
 SG_ YSS_YAW_RATE_UNFILTERED : 23|16@0+ (0.005,-163.83) [-163.83|163.83] "°/s"  ASU_Gateway
 SG_ YSS_YAW_RATE_QUAL : 35|4@0+ (1,0) [0|15] ""  ASU_Gateway
 SG_ YSS_SC_STATUS : 39|4@0+ (1,0) [0|15] ""  ASU_Gateway
 SG_ YSS_YAW_RATE : 47|16@0+ (0.005,-163.83) [-163.83|163.83] "°/s"  ASU_Gateway
 SG_ YSS_TEMPERATURE : 63|8@0+ (1,-40) [-40|115] "°C"  ASU_Gateway

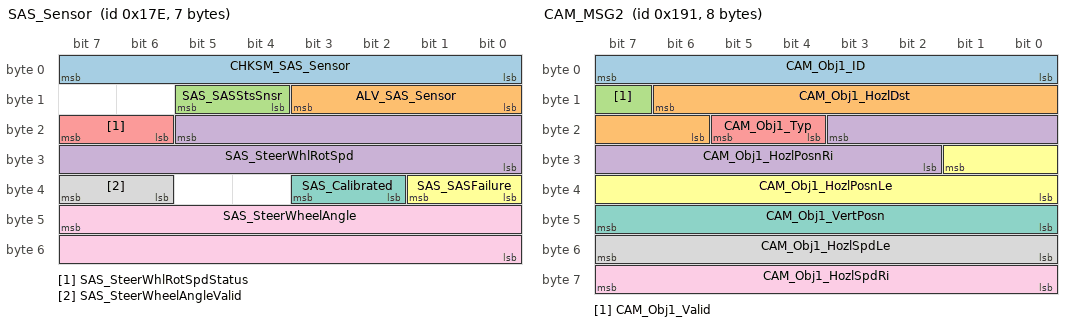
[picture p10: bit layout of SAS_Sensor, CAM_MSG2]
BO_ 382 SAS_Sensor: 7 XGW_Body
 SG_ CHKSM_SAS_Sensor : 7|8@0+ (1,0) [0|255] ""  ACM,BCM,LDM_L,LDM_R
 SG_ ALV_SAS_Sensor : 11|4@0+ (1,0) [0|14] ""  ACM,BCM,LDM_L,LDM_R
 SG_ SAS_SASStsSnsr : 13|2@0+ (1,0) [0|1] "-"  ACM,LDM_L,LDM_R
 SG_ SAS_SteerWhlRotSpd : 21|14@0+ (0.125,-1024) [-1024|1023.875] "degree/s"  LDM_L,LDM_R
 SG_ SAS_SteerWhlRotSpdStatus : 23|2@0+ (1,0) [0|1] ""  LDM_L,LDM_R
 SG_ SAS_SASFailure : 33|2@0+ (1,0) [0|1] ""  ACM,LDM_L,LDM_R
 SG_ SAS_Calibrated : 35|2@0+ (1,0) [0|1] ""  ACM,LDM_L,LDM_R
 SG_ SAS_SteerWheelAngleValid : 39|2@0+ (1,0) [0|1] ""  ACM,LDM_L,LDM_R
 SG_ SAS_SteerWheelAngle : 47|16@0+ (0.0238,-780) [-780|779.7] "deg"  ACM,BCM,LDM_L,LDM_R

BO_ 385 CAM_MSG1: 8 ADAS_Body
 SG_ CAM_CamSts : 1|2@0+ (1,0) [0|3] ""  LDM_L,LDM_R
 SG_ CAM_AmbLi : 8|1@0+ (1,0) [0|1] ""  LDM_L,LDM_R
 SG_ CAM_RoadIllmn : 12|1@0+ (1,0) [0|1] ""  LDM_L,LDM_R
 SG_ CAM_Obj_TrfcStyle : 21|2@0+ (1,0) [0|3] ""  LDM_L,LDM_R

BO_ 401 CAM_MSG2: 8 ADAS_Body
 SG_ CAM_Obj1_ID : 7|8@0+ (1,0) [0|255] ""  LDM_L,LDM_R
 SG_ CAM_Obj1_HozlDst : 14|9@0+ (1,0) [0|511] "m"  LDM_L,LDM_R
 SG_ CAM_Obj1_Valid : 15|1@0+ (1,0) [0|1] ""  LDM_L,LDM_R
 SG_ CAM_Obj1_HozlPosnRi : 19|10@0+ (0.08,-40) [-40|40] "degree"  LDM_L,LDM_R
 SG_ CAM_Obj1_Typ : 21|2@0+ (1,0) [0|3] ""  LDM_L,LDM_R
 SG_ CAM_Obj1_HozlPosnLe : 25|10@0+ (0.08,-40) [-40|40] "degree"  LDM_L,LDM_R
 SG_ CAM_Obj1_VertPosn : 47|8@0+ (0.1,-12) [-12|12] "degree"  LDM_L,LDM_R
 SG_ CAM_Obj1_HozlSpdLe : 55|8@0+ (0.5,-64) [-64|63.5] "degree/s"  LDM_L,LDM_R
 SG_ CAM_Obj1_HozlSpdRi : 63|8@0+ (0.5,-64) [-64|63.5] "degree/s"  LDM_L,LDM_R

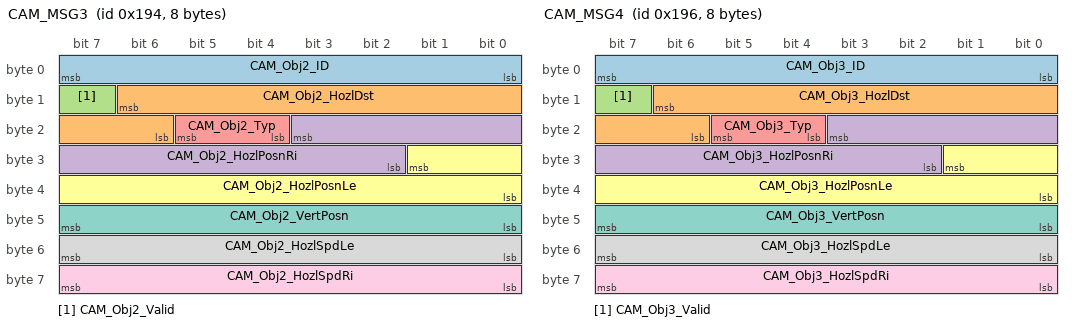
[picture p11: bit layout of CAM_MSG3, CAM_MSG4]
BO_ 404 CAM_MSG3: 8 ADAS_Body
 SG_ CAM_Obj2_ID : 7|8@0+ (1,0) [0|255] ""  LDM_L,LDM_R
 SG_ CAM_Obj2_HozlDst : 14|9@0+ (1,0) [0|511] "m"  LDM_L,LDM_R
 SG_ CAM_Obj2_Valid : 15|1@0+ (1,0) [0|1] ""  LDM_L,LDM_R
 SG_ CAM_Obj2_HozlPosnRi : 19|10@0+ (0.08,-40) [-40|40] "degree"  LDM_L,LDM_R
 SG_ CAM_Obj2_Typ : 21|2@0+ (1,0) [0|3] ""  LDM_L,LDM_R
 SG_ CAM_Obj2_HozlPosnLe : 25|10@0+ (0.08,-40) [-40|40] "degree"  LDM_L,LDM_R
 SG_ CAM_Obj2_VertPosn : 47|8@0+ (0.1,-12) [-12|12] "degree"  LDM_L,LDM_R
 SG_ CAM_Obj2_HozlSpdLe : 55|8@0+ (0.5,-64) [-64|63.5] "degree/s"  LDM_L,LDM_R
 SG_ CAM_Obj2_HozlSpdRi : 63|8@0+ (0.5,-64) [-64|63.5] "degree/s"  LDM_L,LDM_R

BO_ 406 CAM_MSG4: 8 ADAS_Body
 SG_ CAM_Obj3_ID : 7|8@0+ (1,0) [0|255] ""  LDM_L,LDM_R
 SG_ CAM_Obj3_HozlDst : 14|9@0+ (1,0) [0|511] "m"  LDM_L,LDM_R
 SG_ CAM_Obj3_Valid : 15|1@0+ (1,0) [0|1] ""  LDM_L,LDM_R
 SG_ CAM_Obj3_HozlPosnRi : 19|10@0+ (0.08,-40) [-40|40] "degree"  LDM_L,LDM_R
 SG_ CAM_Obj3_Typ : 21|2@0+ (1,0) [0|3] ""  LDM_L,LDM_R
 SG_ CAM_Obj3_HozlPosnLe : 25|10@0+ (0.08,-40) [-40|40] "degree"  LDM_L,LDM_R
 SG_ CAM_Obj3_VertPosn : 47|8@0+ (0.1,-12) [-12|12] "degree"  LDM_L,LDM_R
 SG_ CAM_Obj3_HozlSpdLe : 55|8@0+ (0.5,-64) [-64|63.5] "degree/s"  LDM_L,LDM_R
 SG_ CAM_Obj3_HozlSpdRi : 63|8@0+ (0.5,-64) [-64|63.5] "degree/s"  LDM_L,LDM_R

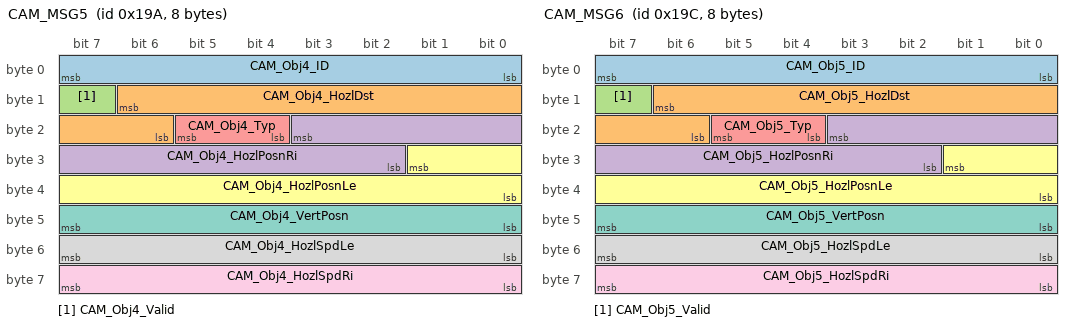
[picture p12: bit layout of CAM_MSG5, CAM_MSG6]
BO_ 410 CAM_MSG5: 8 ADAS_Body
 SG_ CAM_Obj4_ID : 7|8@0+ (1,0) [0|255] ""  LDM_L,LDM_R
 SG_ CAM_Obj4_HozlDst : 14|9@0+ (1,0) [0|511] "m"  LDM_L,LDM_R
 SG_ CAM_Obj4_Valid : 15|1@0+ (1,0) [0|1] ""  LDM_L,LDM_R
 SG_ CAM_Obj4_HozlPosnRi : 19|10@0+ (0.08,-40) [-40|40] "degree"  LDM_L,LDM_R
 SG_ CAM_Obj4_Typ : 21|2@0+ (1,0) [0|3] ""  LDM_L,LDM_R
 SG_ CAM_Obj4_HozlPosnLe : 25|10@0+ (0.08,-40) [-40|40] "degree"  LDM_L,LDM_R
 SG_ CAM_Obj4_VertPosn : 47|8@0+ (0.1,-12) [-12|12] "degree"  LDM_L,LDM_R
 SG_ CAM_Obj4_HozlSpdLe : 55|8@0+ (0.5,-64) [-64|63.5] "degree/s"  LDM_L,LDM_R
 SG_ CAM_Obj4_HozlSpdRi : 63|8@0+ (0.5,-64) [-64|63.5] "degree/s"  LDM_L,LDM_R

BO_ 412 CAM_MSG6: 8 ADAS_Body
 SG_ CAM_Obj5_ID : 7|8@0+ (1,0) [0|255] ""  LDM_L,LDM_R
 SG_ CAM_Obj5_HozlDst : 14|9@0+ (1,0) [0|511] "m"  LDM_L,LDM_R
 SG_ CAM_Obj5_Valid : 15|1@0+ (1,0) [0|1] ""  LDM_L,LDM_R
 SG_ CAM_Obj5_HozlPosnRi : 19|10@0+ (0.08,-40) [-40|40] "degree"  LDM_L,LDM_R
 SG_ CAM_Obj5_Typ : 21|2@0+ (1,0) [0|3] ""  LDM_L,LDM_R
 SG_ CAM_Obj5_HozlPosnLe : 25|10@0+ (0.08,-40) [-40|40] "degree"  LDM_L,LDM_R
 SG_ CAM_Obj5_VertPosn : 47|8@0+ (0.1,-12) [-12|12] "degree"  LDM_L,LDM_R
 SG_ CAM_Obj5_HozlSpdLe : 55|8@0+ (0.5,-64) [-64|63.5] "degree/s"  LDM_L,LDM_R
 SG_ CAM_Obj5_HozlSpdRi : 63|8@0+ (0.5,-64) [-64|63.5] "degree/s"  LDM_L,LDM_R

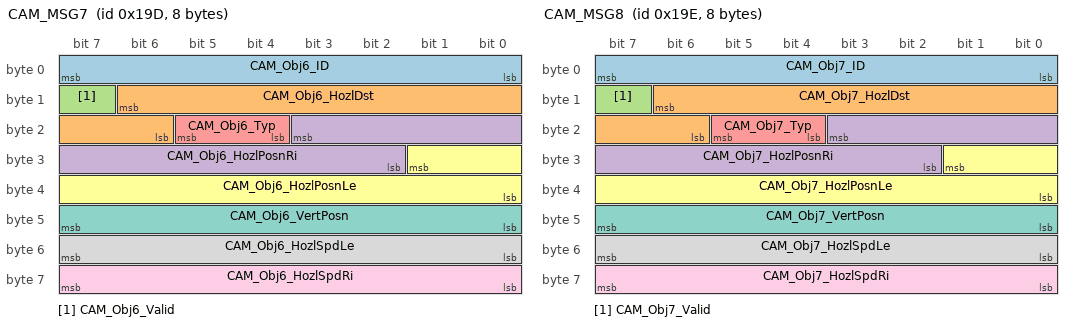
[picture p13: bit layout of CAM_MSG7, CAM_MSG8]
BO_ 413 CAM_MSG7: 8 ADAS_Body
 SG_ CAM_Obj6_ID : 7|8@0+ (1,0) [0|255] ""  LDM_L,LDM_R
 SG_ CAM_Obj6_HozlDst : 14|9@0+ (1,0) [0|511] "m"  LDM_L,LDM_R
 SG_ CAM_Obj6_Valid : 15|1@0+ (1,0) [0|1] ""  LDM_L,LDM_R
 SG_ CAM_Obj6_HozlPosnRi : 19|10@0+ (0.08,-40) [-40|40] "degree"  LDM_L,LDM_R
 SG_ CAM_Obj6_Typ : 21|2@0+ (1,0) [0|3] ""  LDM_L,LDM_R
 SG_ CAM_Obj6_HozlPosnLe : 25|10@0+ (0.08,-40) [-40|40] "degree"  LDM_L,LDM_R
 SG_ CAM_Obj6_VertPosn : 47|8@0+ (0.1,-12) [-12|12] "degree"  LDM_L,LDM_R
 SG_ CAM_Obj6_HozlSpdLe : 55|8@0+ (0.5,-64) [-64|63.5] "degree/s"  LDM_L,LDM_R
 SG_ CAM_Obj6_HozlSpdRi : 63|8@0+ (0.5,-64) [-64|63.5] "degree/s"  LDM_L,LDM_R

BO_ 414 CAM_MSG8: 8 ADAS_Body
 SG_ CAM_Obj7_ID : 7|8@0+ (1,0) [0|255] ""  LDM_L,LDM_R
 SG_ CAM_Obj7_HozlDst : 14|9@0+ (1,0) [0|511] "m"  LDM_L,LDM_R
 SG_ CAM_Obj7_Valid : 15|1@0+ (1,0) [0|1] ""  LDM_L,LDM_R
 SG_ CAM_Obj7_HozlPosnRi : 19|10@0+ (0.08,-40) [-40|40] "degree"  LDM_L,LDM_R
 SG_ CAM_Obj7_Typ : 21|2@0+ (1,0) [0|3] ""  LDM_L,LDM_R
 SG_ CAM_Obj7_HozlPosnLe : 25|10@0+ (0.08,-40) [-40|40] "degree"  LDM_L,LDM_R
 SG_ CAM_Obj7_VertPosn : 47|8@0+ (0.1,-12) [-12|12] "degree"  LDM_L,LDM_R
 SG_ CAM_Obj7_HozlSpdLe : 55|8@0+ (0.5,-64) [-64|63.5] "degree/s"  LDM_L,LDM_R
 SG_ CAM_Obj7_HozlSpdRi : 63|8@0+ (0.5,-64) [-64|63.5] "degree/s"  LDM_L,LDM_R

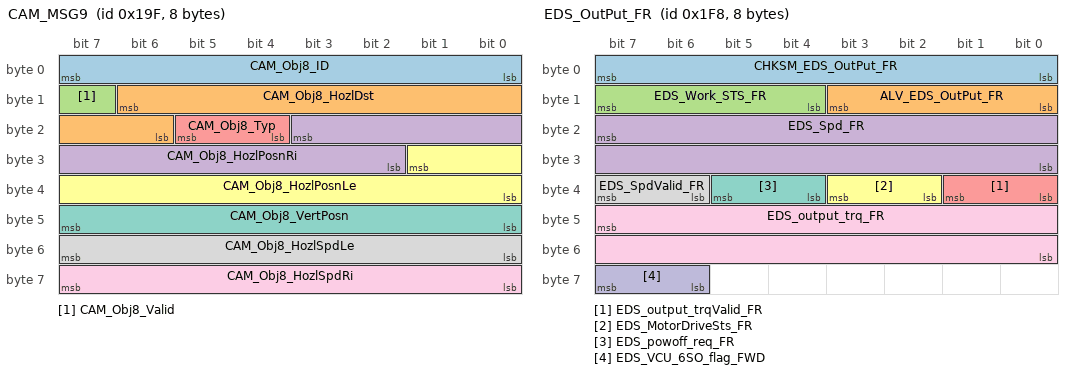
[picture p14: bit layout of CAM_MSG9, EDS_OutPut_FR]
BO_ 415 CAM_MSG9: 8 ADAS_Body
 SG_ CAM_Obj8_ID : 7|8@0+ (1,0) [0|255] ""  LDM_L,LDM_R
 SG_ CAM_Obj8_HozlDst : 14|9@0+ (1,0) [0|511] "m"  LDM_L,LDM_R
 SG_ CAM_Obj8_Valid : 15|1@0+ (1,0) [0|1] ""  LDM_L,LDM_R
 SG_ CAM_Obj8_HozlPosnRi : 19|10@0+ (0.08,-40) [-40|40] "degree"  LDM_L,LDM_R
 SG_ CAM_Obj8_Typ : 21|2@0+ (1,0) [0|3] ""  LDM_L,LDM_R
 SG_ CAM_Obj8_HozlPosnLe : 25|10@0+ (0.08,-40) [-40|40] "degree"  LDM_L,LDM_R
 SG_ CAM_Obj8_VertPosn : 47|8@0+ (0.1,-12) [-12|12] "degree"  LDM_L,LDM_R
 SG_ CAM_Obj8_HozlSpdLe : 55|8@0+ (0.5,-64) [-64|63.5] "degree/s"  LDM_L,LDM_R
 SG_ CAM_Obj8_HozlSpdRi : 63|8@0+ (0.5,-64) [-64|63.5] "degree/s"  LDM_L,LDM_R

BO_ 417 IDB_V_VEH: 5 XGW_Body
 SG_ CHSKM_V_VEH : 7|8@0+ (1,0) [0|255] ""  ACM
 SG_ ALIV_V_VEH : 11|4@0+ (1,0) [0|14] ""  ACM
 SG_ V_VEH_COG : 23|16@0+ (0.015625,0) [0|350] "km/h"  ACM
 SG_ DVCO_VEH : 35|3@0+ (1,0) [0|7] ""  ACM
 SG_ QU_V_VEH_COG : 39|4@0+ (1,0) [0|15] ""  ACM

BO_ 504 EDS_OutPut_FR: 8 XGW_Body
 SG_ CHKSM_EDS_OutPut_FR : 7|8@0+ (1,0) [0|255] ""  ACM,ADAS_Body,APM,ASU_Gateway,BCM_BPM,CCU_F,CCU_R,ETG,LDM_L,LDM_R,OCS_P,PSM_D,SHVU_F,SHVU_R,TRM
 SG_ ALV_EDS_OutPut_FR : 11|4@0+ (1,0) [0|14] ""  ACM,ADAS_Body,APM,ASU_Gateway,BCM_BPM,CCU_F,CCU_R,ETG,LDM_L,LDM_R,OCS_P,PSM_D,SHVU_F,SHVU_R,TRM
 SG_ EDS_Work_STS_FR : 15|4@0+ (1,0) [0|15] "-"  ACM,ADAS_Body,APM,ASU_Gateway,BCM_BPM,CCU_F,CCU_R,ETG,LDM_L,LDM_R,OCS_P,PSM_D,SHVU_F,SHVU_R,TRM
 SG_ EDS_Spd_FR : 23|16@0+ (1,-20000) [-20000|20000] "rpm"  ACM,ADAS_Body,APM,ASU_Gateway,BCM_BPM,CCU_F,CCU_R,ETG,LDM_L,LDM_R,OCS_P,PSM_D,SHVU_F,SHVU_R,TRM
 SG_ EDS_output_trqValid_FR : 33|2@0+ (1,0) [0|1] ""  ACM,ADAS_Body,APM,ASU_Gateway,BCM_BPM,CCU_F,CCU_R,ETG,LDM_L,LDM_R,OCS_P,PSM_D,SHVU_F,SHVU_R,TRM
 SG_ EDS_MotorDriveSts_FR : 35|2@0+ (1,0) [0|3] ""  ACM,ADAS_Body,APM,ASU_Gateway,BCM_BPM,CCU_F,CCU_R,ETG,LDM_L,LDM_R,OCS_P,PSM_D,SHVU_F,SHVU_R,TRM
 SG_ EDS_powoff_req_FR : 37|2@0+ (1,0) [0|1] ""  ACM,ADAS_Body,APM,ASU_Gateway,BCM_BPM,CCU_F,CCU_R,ETG,LDM_L,LDM_R,OCS_P,PSM_D,SHVU_F,SHVU_R,TRM
 SG_ EDS_SpdValid_FR : 39|2@0+ (1,0) [0|1] ""  ACM,ADAS_Body,APM,ASU_Gateway,BCM_BPM,CCU_F,CCU_R,ETG,LDM_L,LDM_R,OCS_P,PSM_D,SHVU_F,SHVU_R,TRM
 SG_ EDS_output_trq_FR : 47|16@0+ (1,-2000) [-2000|2000] "Nm"  ACM,ADAS_Body,APM,ASU_Gateway,BCM_BPM,CCU_F,CCU_R,ETG,LDM_L,LDM_R,OCS_P,PSM_D,SHVU_F,SHVU_R,TRM
 SG_ EDS_VCU_6SO_flag_FWD : 63|2@0+ (1,0) [0|1] ""  ACM,ADAS_Body,APM,ASU_Gateway,BCM_BPM,CCU_F,CCU_R,ETG,LDM_L,LDM_R,OCS_P,PSM_D,SHVU_F,SHVU_R,TRM

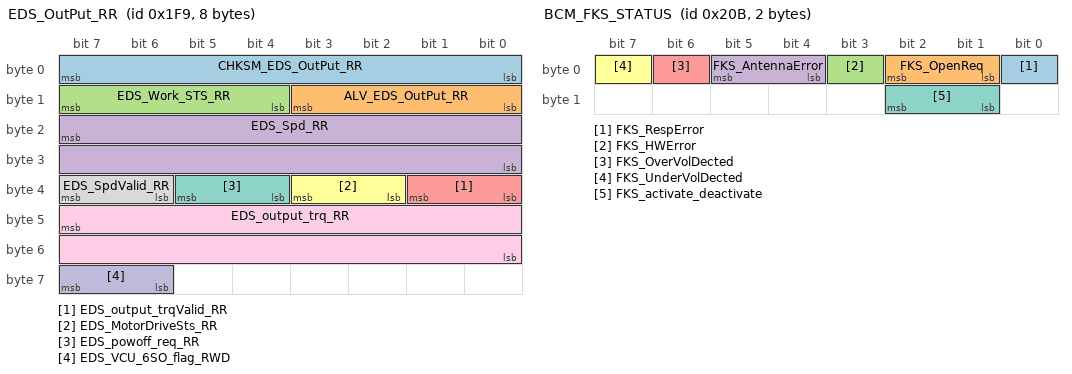
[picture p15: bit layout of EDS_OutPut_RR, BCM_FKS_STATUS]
BO_ 505 EDS_OutPut_RR: 8 XGW_Body
 SG_ CHKSM_EDS_OutPut_RR : 7|8@0+ (1,0) [0|255] ""  ACM,ADAS_Body,APM,ASU_Gateway,BCM_BPM,CCU_F,CCU_R,ETG,LDM_L,LDM_R,OCS_P,PSM_D,SHVU_F,SHVU_R,TRM
 SG_ ALV_EDS_OutPut_RR : 11|4@0+ (1,0) [0|14] ""  ACM,ADAS_Body,APM,ASU_Gateway,BCM_BPM,CCU_F,CCU_R,ETG,LDM_L,LDM_R,OCS_P,PSM_D,SHVU_F,SHVU_R,TRM
 SG_ EDS_Work_STS_RR : 15|4@0+ (1,0) [0|15] "-"  ACM,ADAS_Body,APM,ASU_Gateway,BCM_BPM,CCU_F,CCU_R,ETG,LDM_L,LDM_R,OCS_P,PSM_D,SHVU_F,SHVU_R,TRM
 SG_ EDS_Spd_RR : 23|16@0+ (1,-20000) [-20000|20000] "rpm"  ACM,ADAS_Body,APM,ASU_Gateway,BCM_BPM,CCU_F,CCU_R,ETG,LDM_L,LDM_R,OCS_P,PSM_D,SHVU_F,SHVU_R,TRM
 SG_ EDS_output_trqValid_RR : 33|2@0+ (1,0) [0|1] ""  ACM,ADAS_Body,APM,ASU_Gateway,BCM_BPM,CCU_F,CCU_R,ETG,LDM_L,LDM_R,OCS_P,PSM_D,SHVU_F,SHVU_R,TRM
 SG_ EDS_MotorDriveSts_RR : 35|2@0+ (1,0) [0|3] ""  ACM,ADAS_Body,APM,ASU_Gateway,BCM_BPM,CCU_F,CCU_R,ETG,LDM_L,LDM_R,OCS_P,PSM_D,SHVU_F,SHVU_R,TRM
 SG_ EDS_powoff_req_RR : 37|2@0+ (1,0) [0|1] ""  ACM,ADAS_Body,APM,ASU_Gateway,BCM_BPM,CCU_F,CCU_R,ETG,LDM_L,LDM_R,OCS_P,PSM_D,SHVU_F,SHVU_R,TRM
 SG_ EDS_SpdValid_RR : 39|2@0+ (1,0) [0|1] ""  ACM,ADAS_Body,APM,ASU_Gateway,BCM_BPM,CCU_F,CCU_R,ETG,LDM_L,LDM_R,OCS_P,PSM_D,SHVU_F,SHVU_R,TRM
 SG_ EDS_output_trq_RR : 47|16@0+ (1,-2000) [-2000|2000] "Nm"  ACM,ADAS_Body,APM,ASU_Gateway,BCM_BPM,CCU_F,CCU_R,ETG,LDM_L,LDM_R,OCS_P,PSM_D,SHVU_F,SHVU_R,TRM
 SG_ EDS_VCU_6SO_flag_RWD : 63|2@0+ (1,0) [0|1] "-"  ACM,ADAS_Body,APM,ASU_Gateway,BCM_BPM,CCU_F,CCU_R,ETG,LDM_L,LDM_R,OCS_P,PSM_D,SHVU_F,SHVU_R,TRM

BO_ 519 BCM_SunroofSts: 8 BCM
 SG_ SR_Undervoltage_Fault_Sts : 0|1@0+ (1,0) [0|1] ""  XGW_Body
 SG_ SR_Overvoltage_Fault_Sts : 1|1@0+ (1,0) [0|1] ""  XGW_Body
 SG_ SR_SLEEP_RQ : 2|1@0+ (1,0) [0|1] "-"  XGW_Body
 SG_ SR_Position : 5|3@0+ (1,0) [0|7] ""  XGW_Body
 SG_ SR_Motor_Running_Sts : 7|2@0+ (1,0) [0|3] ""  XGW_Body
 SG_ SR_MotorReverse_Fault_Sts : 8|1@0+ (1,0) [0|1] ""  XGW_Body
 SG_ SR_Hall_Fault_Sts : 9|1@0+ (1,0) [0|1] ""  XGW_Body
 SG_ SR_Normalisation_Sts : 10|1@0+ (1,0) [0|1] ""  XGW_Body
 SG_ SR_Relay_Fault : 11|1@0+ (1,0) [0|1] ""  XGW_Body
 SG_ SR_Commu_Fault_Sts : 12|1@0+ (1,0) [0|1] ""  XGW_Body
 SG_ SR_Initialisation_Status : 13|1@0+ (1,0) [0|1] ""  XGW_Body
 SG_ SR_Ctrl_Result : 15|2@0+ (1,0) [0|3] ""  XGW_Body
 SG_ SR_ThermalProtection_Fault_Sts : 16|1@0+ (1,0) [0|1] "-"  XGW_Body
 SG_ SR_Posit_Percentage : 23|7@0+ (1,0) [0|100] "%"  XGW_Body
 SG_ SR_Operation_Stat : 27|4@0+ (1,0) [0|8] "-"  XGW_Body
 SG_ SR_Error_RSP : 28|1@0+ (1,0) [0|1] ""  XGW_Body
 SG_ BCM_AutoSunroof_Sts : 30|2@0+ (1,0) [0|3] ""  XGW_Body

BO_ 520 BCM_SunshadeSts: 8 BCM
 SG_ SS_MotorReverse_Fault_Status : 0|1@0+ (1,0) [0|1] ""  XGW_Body
 SG_ SS_Motor_Running_Status : 2|2@0+ (1,0) [0|3] ""  XGW_Body
 SG_ SS_Position : 5|3@0+ (1,0) [0|7] ""  XGW_Body
 SG_ SS_SLEEP_RQ : 6|1@0+ (1,0) [0|1] "-"  XGW_Body
 SG_ SS_Undervoltage_Fault_Status : 7|1@0+ (1,0) [0|1] ""  XGW_Body
 SG_ SS_Ctrl_Result : 9|2@0+ (1,0) [0|3] ""  XGW_Body
 SG_ SS_Overvoltage_Fault_Status : 10|1@0+ (1,0) [0|1] ""  XGW_Body
 SG_ SS_Relay_Fault : 11|1@0+ (1,0) [0|1] ""  XGW_Body
 SG_ SS_Normalisation_Status : 12|1@0+ (1,0) [0|1] ""  XGW_Body
 SG_ SS_Hall_Fault_Status : 13|1@0+ (1,0) [0|1] ""  XGW_Body
 SG_ SS_Commu_Fault_Status : 14|1@0+ (1,0) [0|1] ""  XGW_Body
 SG_ SS_Initialisation_Status : 15|1@0+ (1,0) [0|1] ""  XGW_Body
 SG_ SS_Posit_Percentage : 22|7@0+ (1,0) [0|100] "%"  XGW_Body
 SG_ SS_ThermalProtection_Flt_Sts : 23|1@0+ (1,0) [0|1] ""  XGW_Body
 SG_ SS_Operation_State : 31|3@0+ (1,0) [0|7] ""  XGW_Body
 SG_ SECCAN_SunshadeSts : 55|8@0+ (1,0) [0|255] ""  XGW_Body
 SG_ SS_Error_RSP : 63|1@0+ (1,0) [0|1] ""  XGW_Body

BO_ 522 ETG_STATUS: 8 ETG
 SG_ ETG_Lift_Gate_Status : 2|3@0+ (1,0) [0|7] "-"  BCM,XGW_Body
 SG_ ETG_Power_Latch_Status : 5|3@0+ (1,0) [0|7] "-"  BCM,XGW_Body
 SG_ ETG_Latch_Segment : 7|2@0+ (1,0) [0|3] ""  BCM,XGW_Body
 SG_ ETG_Opening_Percentage : 15|8@0+ (1,0) [0|100] "%"  BCM,XGW_Body
 SG_ ETG_DSW_Status : 16|1@0+ (1,0) [0|1] ""  BCM,XGW_Body
 SG_ ETG_GSW_Status : 17|1@0+ (1,0) [0|1] ""  BCM,XGW_Body
 SG_ ETG_LTS_Status : 18|1@0+ (1,0) [0|1] "-"  BCM,XGW_Body
 SG_ ETG_RTS_Status : 19|1@0+ (1,0) [0|1] "-"  BCM,XGW_Body
 SG_ ETG_HAL_Status : 20|1@0+ (1,0) [0|1] "-"  BCM,XGW_Body
 SG_ ETG_FUL_Status : 21|1@0+ (1,0) [0|1] "-"  BCM,XGW_Body
 SG_ ETG_AJR_Status : 22|1@0+ (1,0) [0|1] ""  BCM,XGW_Body
 SG_ ETG_NTL_Status : 23|1@0+ (1,0) [0|1] "-"  BCM,XGW_Body
 SG_ ETG_ERR_Voltage : 25|2@0+ (1,0) [0|3] "-"  BCM,XGW_Body
 SG_ ETG_ERR_Left_Motor : 27|2@0+ (1,0) [0|3] ""  BCM,XGW_Body
 SG_ ETG_ERR_Right_Motor : 29|2@0+ (1,0) [0|3] "-"  BCM,XGW_Body
 SG_ ETG_ERR_Latch : 31|2@0+ (1,0) [0|3] "-"  BCM,XGW_Body
 SG_ ETG_ERR_Hall : 33|2@0+ (1,0) [0|3] ""  BCM,XGW_Body
 SG_ ETG_Lift_Motor_Stall : 34|1@0+ (1,0) [0|1] ""  BCM,XGW_Body
 SG_ ETG_Lift_Motor_AntiPinch : 35|1@0+ (1,0) [0|1] "-"  BCM,XGW_Body
 SG_ ETG_Lift_Motor_Thermal : 36|1@0+ (1,0) [0|1] ""  BCM,XGW_Body
 SG_ ETG_Power_Latch_Thermal : 37|1@0+ (1,0) [0|1] "-"  BCM,XGW_Body
 SG_ ETG_Abuse_Protection : 38|1@0+ (1,0) [0|1] ""  BCM,XGW_Body

BO_ 523 BCM_FKS_STATUS: 2 BCM
 SG_ FKS_RespError : 0|1@0+ (1,0) [0|1] "-"  XGW_Body
 SG_ FKS_OpenReq : 2|2@0+ (1,0) [0|3] ""  XGW_Body
 SG_ FKS_HWError : 3|1@0+ (1,0) [0|1] "-"  XGW_Body
 SG_ FKS_AntennaError : 5|2@0+ (1,0) [0|3] "-"  XGW_Body
 SG_ FKS_OverVolDected : 6|1@0+ (1,0) [0|1] "-"  XGW_Body
 SG_ FKS_UnderVolDected : 7|1@0+ (1,0) [0|1] "-"  XGW_Body
 SG_ FKS_activate_deactivate : 10|2@0+ (1,0) [0|3] "-"  XGW_Body

BO_ 524 IC_ODO: 8 XGW_Body
 SG_ CHKSM_IC_ODO : 7|8@0+ (1,0) [0|255] ""  ACM,ADAS_Body,ASU_Gateway,BCM,CCU_R,LDM_L,LDM_R,OCS_P,PSM_D,SHVU_F,SHVU_R
 SG_ ALIV_IC_ODO : 11|4@0+ (1,0) [0|14] ""  ACM,ADAS_Body,ASU_Gateway,BCM,CCU_R,LDM_L,LDM_R,OCS_P,PSM_D,SHVU_F,SHVU_R
 SG_ MHU_Odometer_IC : 23|20@0+ (1,0) [0|999999] "km"  ACM,ADAS_Body,ASU_Gateway,BCM,CCU_R,LDM_L,LDM_R,OCS_P,PSM_D,SHVU_F,SHVU_R

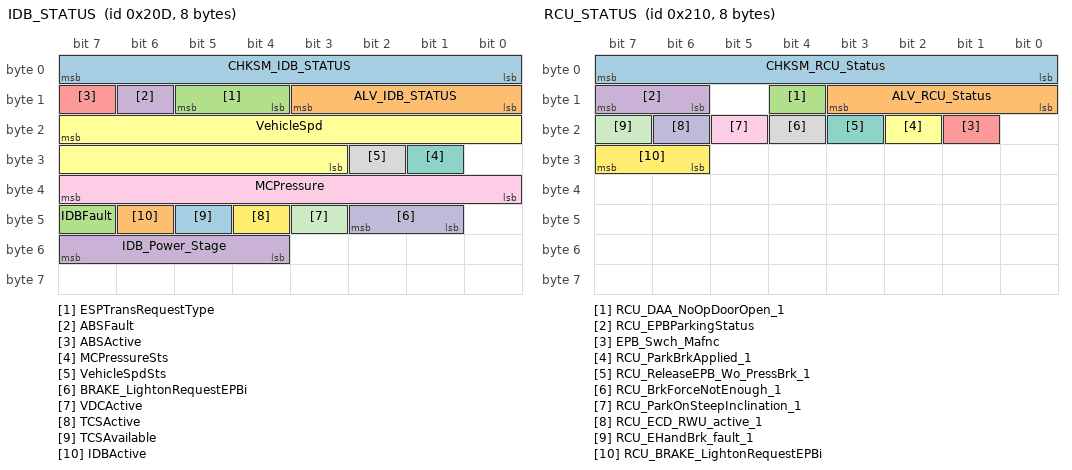
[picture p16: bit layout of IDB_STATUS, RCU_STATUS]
BO_ 525 IDB_STATUS: 8 XGW_Body
 SG_ CHKSM_IDB_STATUS : 7|8@0+ (1,0) [0|255] ""  ACM,APM,ASU_Gateway,BCM,CCU_F,CCU_R,ETG,LDM_L,LDM_R,OCS_P,PSM_D,SHVU_F,SHVU_R,TRM
 SG_ ALV_IDB_STATUS : 11|4@0+ (1,0) [0|14] ""  ACM,APM,ASU_Gateway,BCM,CCU_F,CCU_R,ETG,LDM_L,LDM_R,OCS_P,PSM_D,SHVU_F,SHVU_R,TRM
 SG_ ESPTransRequestType : 13|2@0+ (1,0) [0|3] ""  APM,CCU_F,CCU_R,ETG,TRM
 SG_ ABSFault : 14|1@0+ (1,0) [0|1] ""  ACM,APM,CCU_F,CCU_R,ETG,TRM
 SG_ ABSActive : 15|1@0+ (1,0) [0|1] ""  ACM,APM,CCU_F,CCU_R,ETG,TRM
 SG_ VehicleSpd : 23|13@0+ (0.05625,0) [0|300] "km/h"  ACM,ADAS_Body,APM,ASU_Gateway,BCM,BCM_BPM,CCU_F,CCU_R,ETG,LDM_L,LDM_R,OCS_P,PSM_D,SHVU_F,SHVU_R,TRM
 SG_ MCPressureSts : 25|1@0+ (1,0) [0|1] ""  APM,ASU_Gateway,CCU_F,CCU_R,ETG,TRM
 SG_ VehicleSpdSts : 26|1@0+ (1,0) [0|1] ""  ACM,APM,ASU_Gateway,BCM,CCU_F,CCU_R,ETG,LDM_L,LDM_R,OCS_P,PSM_D,SHVU_F,SHVU_R,TRM
 SG_ MCPressure : 39|8@0+ (2,-42.5) [-42.5|465.5] "bar"  APM,ASU_Gateway,CCU_F,CCU_R,ETG,TRM
 SG_ BRAKE_LightonRequestEPBi : 42|2@0+ (1,0) [0|3] ""  APM,BCM,CCU_F,CCU_R,ETG,TRM
 SG_ VDCActive : 43|1@0+ (1,0) [0|1] ""  APM,CCU_F,CCU_R,ETG,TRM
 SG_ TCSActive : 44|1@0+ (1,0) [0|1] ""  APM,CCU_F,CCU_R,ETG,TRM
 SG_ TCSAvailable : 45|1@0+ (1,0) [0|1] ""  APM,CCU_F,CCU_R,ETG,TRM
 SG_ IDBActive : 46|1@0+ (1,0) [0|1] ""  ACM,APM,CCU_F,CCU_R,ETG,TRM
 SG_ IDBFault : 47|1@0+ (1,0) [0|1] ""  ACM,APM,CCU_F,CCU_R,ETG,TRM
 SG_ IDB_Power_Stage : 55|4@0+ (1,0) [0|15] ""  APM,CCU_F,CCU_R,ETG,TRM

BO_ 527 ADAS_BCM_Status: 8 ADAS_Body
 SG_ ADAS_BCM_Status : 2|3@0+ (1,0) [0|7] ""  BCM
 SG_ ADAS_BCM_HeadlightReq : 3|1@0+ (1,0) [0|1] ""  BCM
 SG_ ADAS_BCM_IndicatorlightReq : 7|3@0+ (1,0) [0|7] ""  BCM
 SG_ ADAS_BCM_FoldMirrorReq : 15|2@0+ (1,0) [0|3] ""  BCM
 SG_ SECCAN_ADAS_BCM_Sts : 63|8@0+ (1,0) [0|255] ""  BCM

BO_ 528 RCU_STATUS: 8 XGW_Body
 SG_ CHKSM_RCU_Status : 7|8@0+ (1,0) [0|255] "" BCM
 SG_ ALV_RCU_Status : 11|4@0+ (1,0) [0|14] "" BCM
 SG_ RCU_DAA_NoOpDoorOpen_1 : 12|1@0+ (1,0) [0|1] "" BCM
 SG_ RCU_EPBParkingStatus : 15|2@0+ (1,0) [0|3] "" BCM
 SG_ EPB_Swch_Mafnc : 17|1@0+ (1,0) [0|1] "" BCM
 SG_ RCU_ParkBrkApplied_1 : 18|1@0+ (1,0) [0|1] "" BCM
 SG_ RCU_ReleaseEPB_Wo_PressBrk_1 : 19|1@0+ (1,0) [0|1] "" BCM
 SG_ RCU_BrkForceNotEnough_1 : 20|1@0+ (1,0) [0|1] "" BCM
 SG_ RCU_ParkOnSteepInclination_1 : 21|1@0+ (1,0) [0|1] "" BCM
 SG_ RCU_ECD_RWU_active_1 : 22|1@0+ (1,0) [0|1] "" BCM
 SG_ RCU_EHandBrk_fault_1 : 23|1@0+ (1,0) [0|1] "" BCM
 SG_ RCU_BRAKE_LightonRequestEPBi : 31|2@0+ (1,0) [0|3] "" BCM

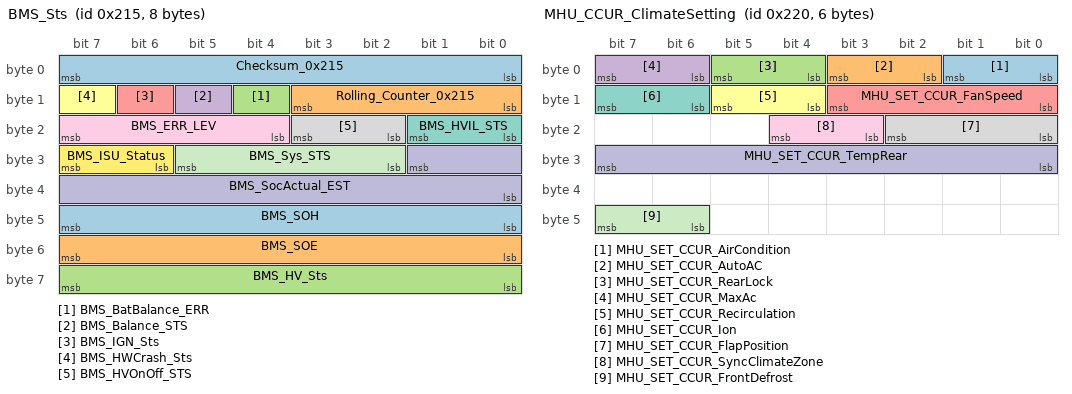
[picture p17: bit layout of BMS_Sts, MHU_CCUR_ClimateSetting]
BO_ 533 BMS_Sts: 8 XGW_Body
 SG_ Checksum_0x215 : 7|8@0+ (1,0) [0|255] ""  BCM,DUMMY_ECU
 SG_ Rolling_Counter_0x215 : 11|4@0+ (1,0) [0|14] ""  BCM,DUMMY_ECU
 SG_ BMS_BatBalance_ERR : 12|1@0+ (1,0) [0|1] ""  DUMMY_ECU
 SG_ BMS_Balance_STS : 13|1@0+ (1,0) [0|1] ""  DUMMY_ECU
 SG_ BMS_IGN_Sts : 14|1@0+ (1,0) [0|1] ""  DUMMY_ECU
 SG_ BMS_HWCrash_Sts : 15|1@0+ (1,0) [0|1] ""  DUMMY_ECU
 SG_ BMS_HVIL_STS : 17|2@0+ (1,0) [0|3] ""  DUMMY_ECU
 SG_ BMS_HVOnOff_STS : 19|2@0+ (1,0) [0|3] ""  BCM,DUMMY_ECU
 SG_ BMS_ERR_LEV : 23|4@0+ (1,0) [0|7] "-"  DUMMY_ECU
 SG_ BMS_SocActual_EST : 25|10@0+ (0.1,0) [0|100] "%"  BCM
 SG_ BMS_Sys_STS : 29|4@0+ (1,0) [0|15] ""  DUMMY_ECU
 SG_ BMS_ISU_Status : 31|2@0+ (1,0) [0|3] ""  DUMMY_ECU
 SG_ BMS_SOH : 47|8@0+ (0.5,0) [0|100] "%"  DUMMY_ECU
 SG_ BMS_SOE : 55|8@0+ (0.5,0) [0|100] "%"  DUMMY_ECU
 SG_ BMS_HV_Sts : 63|8@0+ (1,0) [0|255] ""  DUMMY_ECU

BO_ 537 VCU_PTControl: 8 XGW_Body
 SG_ CHSKM_VCU_PTControl : 7|8@0+ (1,0) [0|255] ""  BCM
 SG_ ALV_VCU_PTControl : 11|4@0+ (1,0) [0|14] ""  BCM
 SG_ VCU_ChargeAllow : 54|1@0+ (1,0) [0|1] ""  BCM

BO_ 544 MHU_CCUR_ClimateSetting: 6 XGW_Body
 SG_ MHU_SET_CCUR_AirCondition : 1|2@0+ (1,0) [0|3] "-"  CCU_F
 SG_ MHU_SET_CCUR_AutoAC : 3|2@0+ (1,0) [0|3] "-"  CCU_F
 SG_ MHU_SET_CCUR_RearLock : 5|2@0+ (1,0) [0|3] "-"  CCU_F
 SG_ MHU_SET_CCUR_MaxAc : 7|2@0+ (1,0) [0|3] ""  CCU_F
 SG_ MHU_SET_CCUR_FanSpeed : 11|4@0+ (1,0) [0|7] "-"  CCU_F
 SG_ MHU_SET_CCUR_Recirculation : 13|2@0+ (1,0) [0|3] "-"  CCU_F
 SG_ MHU_SET_CCUR_Ion : 15|2@0+ (1,0) [0|3] ""  CCU_F
 SG_ MHU_SET_CCUR_FlapPosition : 18|3@0+ (1,0) [0|7] "-"  CCU_F
 SG_ MHU_SET_CCUR_SyncClimateZone : 20|2@0+ (1,0) [0|3] "-"  CCU_F
 SG_ MHU_SET_CCUR_TempRear : 31|8@0+ (0.5,0) [16|32] "Degree C"  CCU_F
 SG_ MHU_SET_CCUR_FrontDefrost : 47|2@0+ (1,0) [0|3] ""  CCU_F

BO_ 545 CCUR_ClimateSetting: 8 CCU_R
 SG_ CCUR_Req_AirCondition : 1|2@0+ (1,0) [0|3] ""  CCU_F,XGW_Body
 SG_ CCUR_AirDistribFlapActPos : 15|8@0+ (0.5,0) [0|100] ""  CCU_F
 SG_ CCUR_TempFlapActPos : 23|8@0+ (0.5,0) [0|100] ""  CCU_F
 SG_ SECCAN_CCUR : 63|8@0+ (1,0) [0|255] ""  CCU_F,XGW_Body

BO_ 546 CCUF_ClimateSetting: 8 CCU_F
 SG_ FRONT_SET_Rear_AirCondition : 1|2@0+ (1,0) [0|3] ""  CCU_R,XGW_Body
 SG_ SECCAN_CCUF : 63|8@0+ (1,0) [0|255] ""  CCU_R,XGW_Body

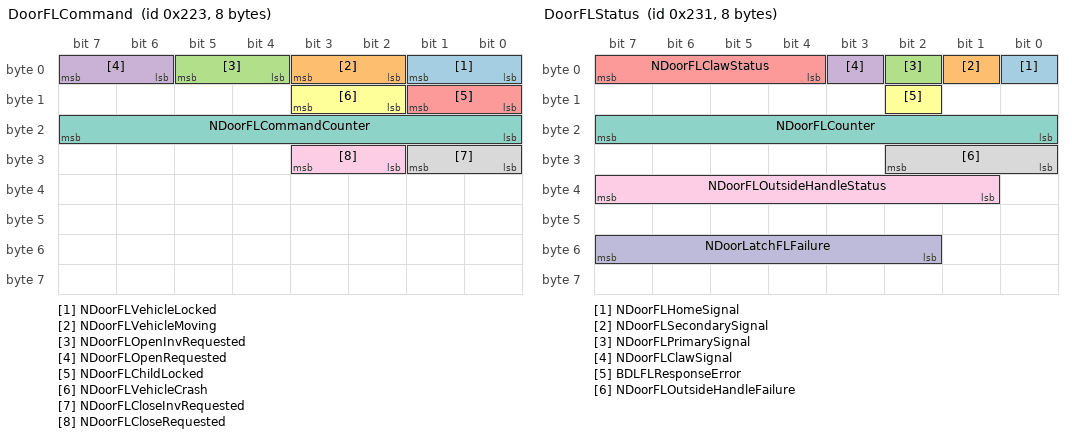
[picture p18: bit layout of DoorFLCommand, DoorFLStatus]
BO_ 547 DoorFLCommand: 8 BCM
 SG_ NDoorFLVehicleLocked : 1|2@0+ (1,0) [0|3] ""  DUMMY_ECU
 SG_ NDoorFLVehicleMoving : 3|2@0+ (1,0) [0|3] ""  DUMMY_ECU
 SG_ NDoorFLOpenInvRequested : 5|2@0+ (1,0) [0|3] ""  XGW_Body
 SG_ NDoorFLOpenRequested : 7|2@0+ (1,0) [0|3] ""  XGW_Body
 SG_ NDoorFLChildLocked : 9|2@0+ (1,0) [0|3] ""  DUMMY_ECU
 SG_ NDoorFLVehicleCrash : 11|2@0+ (1,0) [0|3] ""  DUMMY_ECU
 SG_ NDoorFLCommandCounter : 23|8@0+ (1,0) [0|255] ""  XGW_Body
 SG_ NDoorFLCloseInvRequested : 25|2@0+ (1,0) [0|3] ""  XGW_Body
 SG_ NDoorFLCloseRequested : 27|2@0+ (1,0) [0|3] ""  XGW_Body

BO_ 548 VCU_BMS_Thermal_FB: 8 XGW_Body
 SG_ CHSKM_VCU_BMS_Thermal_FB : 7|8@0+ (1,0) [0|255] ""  BCM
 SG_ ALIV_VCU_BMS_Thermal_FB : 11|4@0+ (1,0) [0|14] ""  BCM
 SG_ VCU_BMS_PTCOnOff_Sts : 12|1@0+ (1,0) [0|1] ""  BCM
 SG_ VCU_BMS_ValveOnOff_Sts : 13|1@0+ (1,0) [0|1] ""  BCM
 SG_ VCU_BMS_PumpFB : 18|3@0+ (1,0) [0|3] ""  BCM

BO_ 561 DoorFLStatus: 8 XGW_Body
 SG_ NDoorFLHomeSignal : 0|1@0+ (1,0) [0|1] ""  BCM
 SG_ NDoorFLSecondarySignal : 1|1@0+ (1,0) [0|1] ""  BCM
 SG_ NDoorFLPrimarySignal : 2|1@0+ (1,0) [0|1] ""  BCM
 SG_ NDoorFLClawSignal : 3|1@0+ (1,0) [0|1] ""  BCM
 SG_ NDoorFLClawStatus : 7|4@0+ (1,0) [0|15] ""  BCM
 SG_ BDLFLResponseError : 10|1@0+ (1,0) [0|1] ""  BCM
 SG_ NDoorFLCounter : 23|8@0+ (1,0) [0|255] ""  BCM
 SG_ NDoorFLOutsideHandleFailure : 26|3@0+ (1,0) [0|7] ""  BCM
 SG_ NDoorFLOutsideHandleStatus : 39|7@0+ (1,0) [0|127] ""  BCM
 SG_ NDoorLatchFLFailure : 55|6@0+ (1,0) [0|63] ""  BCM

BO_ 565 TRM_STATUS: 3 TRM
 SG_ CHKSM_TRM_STATUS : 7|8@0+ (1,0) [0|255] ""  ADAS_Body,XGW_Body
 SG_ ALIVE_TRM_STATUS : 11|4@0+ (1,0) [0|14] ""  ADAS_Body,XGW_Body
 SG_ TowingDetected : 21|2@0+ (1,0) [0|3] ""  ADAS_Body,XGW_Body
 SG_ TrailerDetected : 23|2@0+ (1,0) [0|3] ""  ADAS_Body,ASU_Gateway,XGW_Body

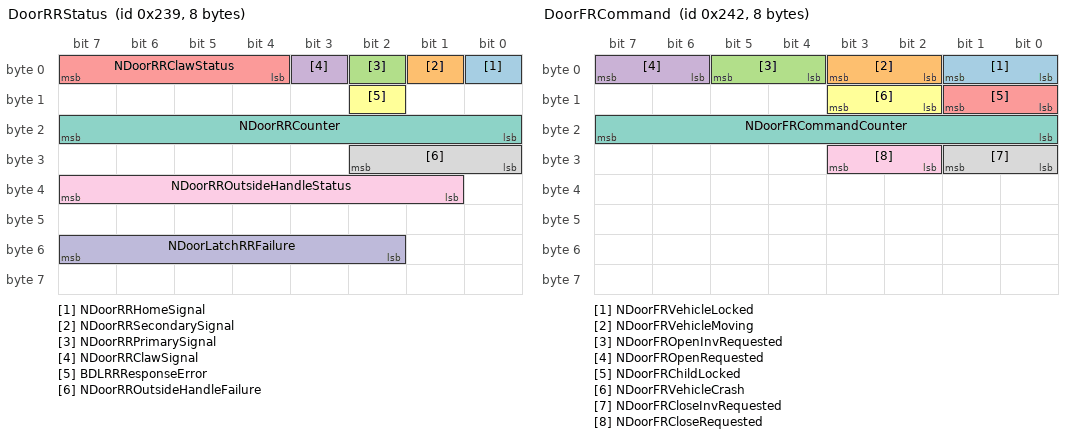
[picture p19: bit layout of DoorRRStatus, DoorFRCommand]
BO_ 569 DoorRRStatus: 8 XGW_Body
 SG_ NDoorRRHomeSignal : 0|1@0+ (1,0) [0|1] ""  BCM
 SG_ NDoorRRSecondarySignal : 1|1@0+ (1,0) [0|1] ""  BCM
 SG_ NDoorRRPrimarySignal : 2|1@0+ (1,0) [0|1] ""  BCM
 SG_ NDoorRRClawSignal : 3|1@0+ (1,0) [0|1] ""  BCM
 SG_ NDoorRRClawStatus : 7|4@0+ (1,0) [0|15] ""  BCM
 SG_ BDLRRResponseError : 10|1@0+ (1,0) [0|1] ""  BCM
 SG_ NDoorRRCounter : 23|8@0+ (1,0) [0|255] ""  BCM
 SG_ NDoorRROutsideHandleFailure : 26|3@0+ (1,0) [0|7] ""  BCM
 SG_ NDoorRROutsideHandleStatus : 39|7@0+ (1,0) [0|127] ""  BCM
 SG_ NDoorLatchRRFailure : 55|6@0+ (1,0) [0|63] ""  BCM

BO_ 578 DoorFRCommand: 8 BCM
 SG_ NDoorFRVehicleLocked : 1|2@0+ (1,0) [0|3] ""  DUMMY_ECU
 SG_ NDoorFRVehicleMoving : 3|2@0+ (1,0) [0|3] ""  DUMMY_ECU
 SG_ NDoorFROpenInvRequested : 5|2@0+ (1,0) [0|3] ""  XGW_Body
 SG_ NDoorFROpenRequested : 7|2@0+ (1,0) [0|3] ""  XGW_Body
 SG_ NDoorFRChildLocked : 9|2@0+ (1,0) [0|3] ""  DUMMY_ECU
 SG_ NDoorFRVehicleCrash : 11|2@0+ (1,0) [0|3] ""  DUMMY_ECU
 SG_ NDoorFRCommandCounter : 23|8@0+ (1,0) [0|255] ""  XGW_Body
 SG_ NDoorFRCloseInvRequested : 25|2@0+ (1,0) [0|3] ""  XGW_Body
 SG_ NDoorFRCloseRequested : 27|2@0+ (1,0) [0|3] ""  XGW_Body

BA_DEF_ BO_  "GenMsgSendType" ENUM  "Cyclic","NotUsed","NotUsed","NotUsed","NotUsed","NotUsed","NotUsed","IfActive","NoMsgSendType","NotUsed";
BA_DEF_ BO_  "GenMsgILSupport" ENUM  "No","Yes";
BA_DEF_ BO_  "DiagResponse" ENUM  "No","Yes";
BA_DEF_ BO_  "DiagRequest" ENUM  "No","Yes";
BA_DEF_ BO_  "NmAsrMessage" ENUM  "No","Yes";
BA_DEF_ BO_  "DiagState" ENUM  "No","Yes";
BA_DEF_ BO_  "DiagUudtResponse" ENUM  "False","True";
BA_DEF_ BO_  "GenMsgStartDelayTime" INT 0 65535;
BA_DEF_ BO_  "GenMsgDelayTime" INT 0 0;
BA_DEF_ BO_  "GenMsgNrOfRepetition" INT 0 0;
BA_DEF_ BO_  "GenMsgCycleTimeFast" INT 0 0;
BA_DEF_ BO_  "GenMsgCycleTime" INT 0 0;
BA_DEF_ BU_  "NmStationAddress" HEX 0 0;
BA_DEF_ BU_  "Address" HEX 0 255;
BA_DEF_ BU_  "TpSTMin" INT 0 255;
BA_DEF_ BU_  "ILUsed" ENUM  "No","Yes";
BA_DEF_ BU_  "NmAsrNode" ENUM  "No","Yes";
BA_DEF_ BU_  "NmAsrNodeIdentifier" HEX 0 255;
BA_DEF_ BU_  "NmAsrCanMsgCycleOffset" INT 0 65535;
BA_DEF_ BU_  "NmAsrCanMsgReducedTime" INT 320 640;
BA_DEF_ SG_  "GenSigSendType" ENUM  "Cyclic","OnWrite","OnWriteWithRepetition","OnChange","OnChangeWithRepetition","IfActive","IfActiveWithRepetition","NoSigSendType","NotUsed","NotUsed","NotUsed","NotUsed","NotUsed";
BA_DEF_ SG_  "InvalidValue" STRING ;
BA_DEF_ SG_  "GenSigStartValue" INT 0 0;
BA_DEF_ SG_  "GenSigTimeoutTime_ALL" INT 0 65535;
BA_DEF_  "DBName" STRING ;
BA_DEF_  "NmAsrBaseAddress" HEX 0 2047;
BA_DEF_  "NmAsrMessageCount" INT 1 256;
BA_DEF_  "NmAsrTimeoutTime" INT 0 65535;
BA_DEF_  "NmAsrWaitBusSleepTime" INT 0 65535;
BA_DEF_  "NmAsrRepeatMessageTime" INT 0 65535;
BA_DEF_  "NmAsrCanMsgCycleTime" INT 0 65535;
BA_DEF_  "Baudrate" INT 0 1000000;
BA_DEF_  "BusType" STRING ;
BA_DEF_  "NmType" STRING ;
BA_DEF_  "Manufacturer" STRING ;
BA_DEF_ BU_  "ECU" STRING ;
BA_DEF_DEF_  "GenMsgSendType" "NoMsgSendType";
BA_DEF_DEF_  "GenMsgILSupport" "Yes";
BA_DEF_DEF_  "DiagResponse" "No";
BA_DEF_DEF_  "DiagRequest" "No";
BA_DEF_DEF_  "NmAsrMessage" "No";
BA_DEF_DEF_  "DiagState" "No";
BA_DEF_DEF_  "DiagUudtResponse" "False";
BA_DEF_DEF_  "GenMsgStartDelayTime" 0;
BA_DEF_DEF_  "GenMsgDelayTime" 0;
BA_DEF_DEF_  "GenMsgNrOfRepetition" 0;
BA_DEF_DEF_  "GenMsgCycleTimeFast" 0;
BA_DEF_DEF_  "GenMsgCycleTime" 0;
BA_DEF_DEF_  "NmStationAddress" 0;
BA_DEF_DEF_  "Address" 0;
BA_DEF_DEF_  "TpSTMin" 20;
BA_DEF_DEF_  "ILUsed" "Yes";
BA_DEF_DEF_  "NmAsrNode" "Yes";
BA_DEF_DEF_  "NmAsrNodeIdentifier" 0;
BA_DEF_DEF_  "NmAsrCanMsgCycleOffset" 0;
BA_DEF_DEF_  "NmAsrCanMsgReducedTime" 320;
BA_DEF_DEF_  "GenSigSendType" "Cyclic";
BA_DEF_DEF_  "InvalidValue" "";
BA_DEF_DEF_  "GenSigStartValue" 0;
BA_DEF_DEF_  "GenSigTimeoutTime_ALL" 0;
BA_DEF_DEF_  "DBName" "";
BA_DEF_DEF_  "NmAsrBaseAddress" 1280;
BA_DEF_DEF_  "NmAsrMessageCount" 128;
BA_DEF_DEF_  "NmAsrTimeoutTime" 2000;
BA_DEF_DEF_  "NmAsrWaitBusSleepTime" 1500;
BA_DEF_DEF_  "NmAsrRepeatMessageTime" 3200;
BA_DEF_DEF_  "NmAsrCanMsgCycleTime" 640;
BA_DEF_DEF_  "Baudrate" 500000;
BA_DEF_DEF_  "BusType" "";
BA_DEF_DEF_  "NmType" "";
BA_DEF_DEF_  "Manufacturer" "VinFast";
BA_DEF_DEF_  "ECU" "";
BA_ "BusType" "CAN";
BA_ "NmType" "NmAsr";
BA_ "DBName" "Body";
BA_ "Address" BU_ ACM 8;
BA_ "ECU" BU_ ACM "ACM";
BA_ "NmAsrCanMsgCycleOffset" BU_ ACM 40;
BA_ "NmAsrCanMsgReducedTime" BU_ ACM 340;
BA_ "NmAsrNodeIdentifier" BU_ ACM 8;
BA_ "NmStationAddress" BU_ ACM 8;
BA_ "Address" BU_ ADAS_Body 64;
BA_ "ECU" BU_ ADAS_Body "ADAS_BodyCAN";
BA_ "NmAsrCanMsgCycleOffset" BU_ ADAS_Body 320;
BA_ "NmAsrCanMsgReducedTime" BU_ ADAS_Body 480;
BA_ "NmAsrNode" BU_ ADAS_Body 0;
BA_ "NmAsrNodeIdentifier" BU_ ADAS_Body 64;
BA_ "NmStationAddress" BU_ ADAS_Body 64;
BA_ "Address" BU_ APM 65;
BA_ "ECU" BU_ APM "APM";
BA_ "NmAsrCanMsgCycleOffset" BU_ APM 325;
BA_ "NmAsrNodeIdentifier" BU_ APM 65;
BA_ "NmStationAddress" BU_ APM 65;
BA_ "Address" BU_ ASU_Gateway 28;
BA_ "ECU" BU_ ASU_Gateway "ASU";
BA_ "NmAsrNodeIdentifier" BU_ ASU_Gateway 17;
BA_ "NmStationAddress" BU_ ASU_Gateway 17;
BA_ "Address" BU_ BCM 1;
BA_ "ECU" BU_ BCM "Body_CAN_BCM";
BA_ "NmAsrCanMsgCycleOffset" BU_ BCM 5;
BA_ "NmAsrNodeIdentifier" BU_ BCM 1;
BA_ "NmStationAddress" BU_ BCM 1;
BA_ "Address" BU_ BCM_BPM 123;
BA_ "ECU" BU_ BCM_BPM "BCM_BPM";
BA_ "NmAsrCanMsgCycleOffset" BU_ BCM_BPM 485;
BA_ "NmStationAddress" BU_ BCM_BPM 123;
BA_ "Address" BU_ CCU_F 9;
BA_ "ECU" BU_ CCU_F "CCU_F";
BA_ "NmAsrCanMsgCycleOffset" BU_ CCU_F 45;
BA_ "NmAsrNodeIdentifier" BU_ CCU_F 9;
BA_ "NmStationAddress" BU_ CCU_F 9;
BA_ "Address" BU_ CCU_R 20;
BA_ "ECU" BU_ CCU_R "CCU_R";
BA_ "NmAsrCanMsgCycleOffset" BU_ CCU_R 70;
BA_ "NmAsrCanMsgReducedTime" BU_ CCU_R 355;
BA_ "NmAsrNodeIdentifier" BU_ CCU_R 20;
BA_ "NmStationAddress" BU_ CCU_R 20;
BA_ "ECU" BU_ DUMMY_BCM_BPM "DUMMY_BCM_BPM";
BA_ "ECU" BU_ DUMMY_ECU "DUMMY_ECU";
BA_ "Address" BU_ ETG 14;
BA_ "ECU" BU_ ETG "ETG";
BA_ "NmAsrCanMsgCycleOffset" BU_ ETG 70;
BA_ "NmAsrCanMsgReducedTime" BU_ ETG 355;
BA_ "NmAsrNodeIdentifier" BU_ ETG 14;
BA_ "NmStationAddress" BU_ ETG 14;
BA_ "Address" BU_ LDM_L 73;
BA_ "ECU" BU_ LDM_L "LDM_L";
BA_ "NmAsrCanMsgCycleOffset" BU_ LDM_L 365;
BA_ "NmAsrCanMsgReducedTime" BU_ LDM_L 503;
BA_ "NmAsrNodeIdentifier" BU_ LDM_L 73;
BA_ "NmStationAddress" BU_ LDM_L 73;
BA_ "Address" BU_ LDM_R 74;
BA_ "ECU" BU_ LDM_R "LDM_R";
BA_ "NmAsrCanMsgCycleOffset" BU_ LDM_R 370;
BA_ "NmAsrCanMsgReducedTime" BU_ LDM_R 505;
BA_ "NmAsrNodeIdentifier" BU_ LDM_R 74;
BA_ "NmStationAddress" BU_ LDM_R 74;
BA_ "Address" BU_ OCS_P 68;
BA_ "ECU" BU_ OCS_P "OCS_P";
BA_ "NmAsrCanMsgCycleOffset" BU_ OCS_P 340;
BA_ "NmAsrCanMsgReducedTime" BU_ OCS_P 490;
BA_ "NmAsrNodeIdentifier" BU_ OCS_P 68;
BA_ "NmStationAddress" BU_ OCS_P 68;
BA_ "Address" BU_ PSM_D 30;
BA_ "ECU" BU_ PSM_D "PSM_D";
BA_ "NmAsrCanMsgCycleOffset" BU_ PSM_D 150;
BA_ "NmAsrCanMsgReducedTime" BU_ PSM_D 395;
BA_ "NmAsrNodeIdentifier" BU_ PSM_D 30;
BA_ "NmStationAddress" BU_ PSM_D 30;
BA_ "Address" BU_ SHVU_F 66;
BA_ "ECU" BU_ SHVU_F "SHVU_F";
BA_ "NmAsrCanMsgCycleOffset" BU_ SHVU_F 330;
BA_ "NmAsrCanMsgReducedTime" BU_ SHVU_F 485;
BA_ "NmAsrNodeIdentifier" BU_ SHVU_F 66;
BA_ "NmStationAddress" BU_ SHVU_F 66;
BA_ "Address" BU_ SHVU_R 67;
BA_ "ECU" BU_ SHVU_R "SHVU_R";
BA_ "NmAsrCanMsgCycleOffset" BU_ SHVU_R 335;
BA_ "NmAsrNodeIdentifier" BU_ SHVU_R 67;
BA_ "NmStationAddress" BU_ SHVU_R 67;
BA_ "Address" BU_ TRM 59;
BA_ "ECU" BU_ TRM "TRM";
BA_ "NmAsrCanMsgCycleOffset" BU_ TRM 295;
BA_ "NmAsrNodeIdentifier" BU_ TRM 59;
BA_ "NmStationAddress" BU_ TRM 59;
BA_ "Address" BU_ XGW_Body 2;
BA_ "ECU" BU_ XGW_Body "XGW_BodyCAN";
BA_ "NmAsrCanMsgCycleOffset" BU_ XGW_Body 10;
BA_ "NmAsrCanMsgReducedTime" BU_ XGW_Body 325;
BA_ "NmAsrNodeIdentifier" BU_ XGW_Body 2;
BA_ "NmStationAddress" BU_ XGW_Body 2;
BA_ "GenMsgCycleTime" BO_ 133 20;
BA_ "GenMsgSendType" BO_ 133 0;
BA_ "GenMsgCycleTime" BO_ 149 100;
BA_ "GenMsgSendType" BO_ 149 0;
BA_ "GenMsgCycleTime" BO_ 217 20;
BA_ "GenMsgSendType" BO_ 217 0;
BA_ "GenMsgCycleTime" BO_ 256 1000;
BA_ "GenMsgSendType" BO_ 256 0;
BA_ "GenMsgCycleTime" BO_ 258 100;
BA_ "GenMsgSendType" BO_ 258 0;
BA_ "GenMsgCycleTime" BO_ 259 1000;
BA_ "GenMsgSendType" BO_ 259 0;
BA_ "GenMsgCycleTime" BO_ 260 100;
BA_ "GenMsgSendType" BO_ 260 0;
BA_ "GenMsgCycleTime" BO_ 261 100;
BA_ "GenMsgSendType" BO_ 261 0;
BA_ "GenMsgCycleTime" BO_ 262 100;
BA_ "GenMsgSendType" BO_ 262 0;
BA_ "GenMsgCycleTime" BO_ 263 100;
BA_ "GenMsgSendType" BO_ 263 0;
BA_ "GenMsgCycleTime" BO_ 265 100;
BA_ "GenMsgCycleTimeFast" BO_ 265 30;
BA_ "GenMsgNrOfRepetition" BO_ 265 3;
BA_ "GenMsgSendType" BO_ 265 0;
BA_ "GenMsgCycleTime" BO_ 266 500;
BA_ "GenMsgSendType" BO_ 266 0;
BA_ "GenMsgCycleTime" BO_ 267 100;
BA_ "GenMsgSendType" BO_ 267 0;
BA_ "GenMsgCycleTime" BO_ 268 100;
BA_ "GenMsgSendType" BO_ 268 0;
BA_ "GenMsgCycleTimeFast" BO_ 269 100;
BA_ "GenMsgNrOfRepetition" BO_ 269 3;
BA_ "GenMsgCycleTime" BO_ 270 100;
BA_ "GenMsgCycleTimeFast" BO_ 270 30;
BA_ "GenMsgNrOfRepetition" BO_ 270 3;
BA_ "GenMsgSendType" BO_ 270 0;
BA_ "GenMsgCycleTimeFast" BO_ 271 30;
BA_ "GenMsgNrOfRepetition" BO_ 271 3;
BA_ "GenMsgCycleTime" BO_ 273 100;
BA_ "GenMsgSendType" BO_ 273 0;
BA_ "GenMsgCycleTime" BO_ 274 100;
BA_ "GenMsgCycleTimeFast" BO_ 274 20;
BA_ "GenMsgNrOfRepetition" BO_ 274 3;
BA_ "GenMsgSendType" BO_ 274 0;
BA_ "GenMsgCycleTime" BO_ 276 100;
BA_ "GenMsgSendType" BO_ 276 0;
BA_ "GenMsgCycleTime" BO_ 278 500;
BA_ "GenMsgSendType" BO_ 278 0;
BA_ "GenMsgCycleTime" BO_ 280 500;
BA_ "GenMsgSendType" BO_ 280 0;
BA_ "GenMsgCycleTimeFast" BO_ 282 100;
BA_ "GenMsgNrOfRepetition" BO_ 282 2;
BA_ "GenMsgCycleTimeFast" BO_ 283 100;
BA_ "GenMsgNrOfRepetition" BO_ 283 3;
BA_ "GenMsgCycleTimeFast" BO_ 284 100;
BA_ "GenMsgNrOfRepetition" BO_ 284 3;
BA_ "GenMsgCycleTime" BO_ 285 200;
BA_ "GenMsgSendType" BO_ 285 0;
BA_ "GenMsgStartDelayTime" BO_ 285 20;
BA_ "GenMsgCycleTime" BO_ 286 200;
BA_ "GenMsgSendType" BO_ 286 0;
BA_ "GenMsgCycleTimeFast" BO_ 287 30;
BA_ "GenMsgNrOfRepetition" BO_ 287 3;
BA_ "GenMsgCycleTime" BO_ 290 200;
BA_ "GenMsgSendType" BO_ 290 0;
BA_ "GenMsgStartDelayTime" BO_ 290 15;
BA_ "GenMsgCycleTime" BO_ 303 100;
BA_ "GenMsgSendType" BO_ 303 0;
BA_ "GenMsgCycleTime" BO_ 376 10;
BA_ "GenMsgSendType" BO_ 376 0;
BA_ "GenMsgCycleTime" BO_ 381 10;
BA_ "GenMsgSendType" BO_ 381 0;
BA_ "GenMsgCycleTime" BO_ 382 10;
BA_ "GenMsgSendType" BO_ 382 0;
BA_ "GenMsgCycleTime" BO_ 385 40;
BA_ "GenMsgSendType" BO_ 385 0;
BA_ "GenMsgCycleTime" BO_ 401 40;
BA_ "GenMsgSendType" BO_ 401 0;
BA_ "GenMsgCycleTime" BO_ 404 40;
BA_ "GenMsgSendType" BO_ 404 0;
BA_ "GenMsgCycleTime" BO_ 406 40;
BA_ "GenMsgSendType" BO_ 406 0;
BA_ "GenMsgCycleTime" BO_ 410 40;
BA_ "GenMsgSendType" BO_ 410 0;
BA_ "GenMsgCycleTime" BO_ 412 40;
BA_ "GenMsgSendType" BO_ 412 0;
BA_ "GenMsgCycleTime" BO_ 413 40;
BA_ "GenMsgSendType" BO_ 413 0;
BA_ "GenMsgCycleTime" BO_ 414 40;
BA_ "GenMsgSendType" BO_ 414 0;
BA_ "GenMsgCycleTime" BO_ 415 40;
BA_ "GenMsgSendType" BO_ 415 0;
BA_ "GenMsgCycleTime" BO_ 417 20;
BA_ "GenMsgSendType" BO_ 417 0;
BA_ "GenMsgCycleTime" BO_ 504 20;
BA_ "GenMsgSendType" BO_ 504 0;
BA_ "GenMsgCycleTime" BO_ 505 20;
BA_ "GenMsgSendType" BO_ 505 0;
BA_ "GenMsgCycleTime" BO_ 519 100;
BA_ "GenMsgSendType" BO_ 519 0;
BA_ "GenMsgCycleTime" BO_ 520 100;
BA_ "GenMsgSendType" BO_ 520 0;
BA_ "GenMsgCycleTime" BO_ 522 100;
BA_ "GenMsgSendType" BO_ 522 0;
BA_ "GenMsgCycleTime" BO_ 523 100;
BA_ "GenMsgCycleTimeFast" BO_ 523 30;
BA_ "GenMsgNrOfRepetition" BO_ 523 3;
BA_ "GenMsgSendType" BO_ 523 0;
BA_ "GenMsgCycleTime" BO_ 524 100;
BA_ "GenMsgSendType" BO_ 524 0;
BA_ "GenMsgCycleTime" BO_ 525 20;
BA_ "GenMsgSendType" BO_ 525 0;
BA_ "GenMsgCycleTime" BO_ 527 50;
BA_ "GenMsgSendType" BO_ 527 0;
BA_ "GenMsgCycleTime" BO_ 528 40;
BA_ "GenMsgSendType" BO_ 528 0;
BA_ "GenMsgCycleTime" BO_ 533 50;
BA_ "GenMsgILSupport" BO_ 533 0;
BA_ "GenMsgSendType" BO_ 533 0;
BA_ "GenMsgCycleTime" BO_ 537 20;
BA_ "GenMsgILSupport" BO_ 537 0;
BA_ "GenMsgSendType" BO_ 537 0;
BA_ "GenMsgCycleTimeFast" BO_ 544 50;
BA_ "GenMsgNrOfRepetition" BO_ 544 3;
BA_ "GenMsgCycleTime" BO_ 545 200;
BA_ "GenMsgSendType" BO_ 545 0;
BA_ "GenMsgCycleTime" BO_ 546 100;
BA_ "GenMsgSendType" BO_ 546 0;
BA_ "GenMsgStartDelayTime" BO_ 546 10;
BA_ "GenMsgCycleTime" BO_ 547 20;
BA_ "GenMsgSendType" BO_ 547 0;
BA_ "GenMsgCycleTime" BO_ 548 100;
BA_ "GenMsgILSupport" BO_ 548 0;
BA_ "GenMsgSendType" BO_ 548 0;
BA_ "GenMsgCycleTime" BO_ 561 20;
BA_ "GenMsgSendType" BO_ 561 0;
BA_ "GenMsgCycleTime" BO_ 565 100;
BA_ "GenMsgSendType" BO_ 565 0;
BA_ "GenMsgCycleTime" BO_ 569 20;
BA_ "GenMsgSendType" BO_ 569 0;
BA_ "GenMsgCycleTime" BO_ 578 20;
BA_ "GenMsgSendType" BO_ 578 0;

BA_ "GenSigTimeoutTime_ALL" SG_ 133 CHKSM_CRASH_Sts 200;
BA_ "InvalidValue" SG_ 133 CHKSM_CRASH_Sts "null";
BA_ "GenSigTimeoutTime_ALL" SG_ 133 ALV_CRASH_Sts 200;
BA_ "InvalidValue" SG_ 133 ALV_CRASH_Sts "Fh";
BA_ "GenSigTimeoutTime_ALL" SG_ 133 ACM_Crash_Sts 200;
BA_ "InvalidValue" SG_ 133 ACM_Crash_Sts "3h";
BA_ "GenSigTimeoutTime_ALL" SG_ 133 ACM_Airbag_Deployment_Status 200;
BA_ "InvalidValue" SG_ 133 ACM_Airbag_Deployment_Status "3h";
BA_ "GenSigTimeoutTime_ALL" SG_ 133 ACM_Crash_Intensity 200;
BA_ "InvalidValue" SG_ 133 ACM_Crash_Intensity "7h";
BA_ "GenSigTimeoutTime_ALL" SG_ 133 ACM_Front_Crash 200;
BA_ "InvalidValue" SG_ 133 ACM_Front_Crash "3h";
BA_ "GenSigTimeoutTime_ALL" SG_ 133 ACM_DriverSide_Crash 200;
BA_ "InvalidValue" SG_ 133 ACM_DriverSide_Crash "3h";
BA_ "GenSigTimeoutTime_ALL" SG_ 133 ACM_PassSide_Crash 200;
BA_ "InvalidValue" SG_ 133 ACM_PassSide_Crash "3h";
BA_ "GenSigTimeoutTime_ALL" SG_ 133 ACM_Rear_Crash 200;
BA_ "InvalidValue" SG_ 133 ACM_Rear_Crash "3h";
BA_ "GenSigTimeoutTime_ALL" SG_ 133 ACM_Rollover_Crash 200;
BA_ "InvalidValue" SG_ 133 ACM_Rollover_Crash "3h";
BA_ "InvalidValue" SG_ 134 ACM_CrashDeltaV_PackID "FFh";
BA_ "GenSigStartValue" SG_ 134 ACM_CrashDeltaV_PackID 1;
BA_ "GenSigSendType" SG_ 134 ACM_CrashDeltaV_PackID 1;
BA_ "InvalidValue" SG_ 134 ACM_DeltaVx_01 "1FFh";
BA_ "GenSigStartValue" SG_ 134 ACM_DeltaVx_01 250;
BA_ "GenSigSendType" SG_ 134 ACM_DeltaVx_01 1;
BA_ "InvalidValue" SG_ 134 ACM_DeltaVx_02 "1FFh";
BA_ "GenSigStartValue" SG_ 134 ACM_DeltaVx_02 250;
BA_ "GenSigSendType" SG_ 134 ACM_DeltaVx_02 1;
BA_ "InvalidValue" SG_ 134 ACM_DeltaVx_03 "1FFh";
BA_ "GenSigStartValue" SG_ 134 ACM_DeltaVx_03 250;
BA_ "GenSigSendType" SG_ 134 ACM_DeltaVx_03 1;
BA_ "InvalidValue" SG_ 134 ACM_DeltaVy_01 "1FFh";
BA_ "GenSigStartValue" SG_ 134 ACM_DeltaVy_01 250;
BA_ "GenSigSendType" SG_ 134 ACM_DeltaVy_01 1;
BA_ "InvalidValue" SG_ 134 ACM_DeltaVy_02 "1FFh";
BA_ "GenSigStartValue" SG_ 134 ACM_DeltaVy_02 250;
BA_ "GenSigSendType" SG_ 134 ACM_DeltaVy_02 1;
BA_ "InvalidValue" SG_ 134 ACM_DeltaVy_03 "1FFh";
BA_ "GenSigStartValue" SG_ 134 ACM_DeltaVy_03 250;
BA_ "GenSigSendType" SG_ 134 ACM_DeltaVy_03 1;
BA_ "GenSigTimeoutTime_ALL" SG_ 149 CHKSM_IDB_FUNCTION 500;
BA_ "InvalidValue" SG_ 149 CHKSM_IDB_FUNCTION "null";
BA_ "GenSigTimeoutTime_ALL" SG_ 149 ALV_IDB_FUNCTION 500;
BA_ "InvalidValue" SG_ 149 ALV_IDB_FUNCTION "Fh";
BA_ "GenSigTimeoutTime_ALL" SG_ 149 STAT_ABS 500;
BA_ "InvalidValue" SG_ 149 STAT_ABS "3h";
BA_ "GenSigTimeoutTime_ALL" SG_ 149 ABS_Active 500;
BA_ "InvalidValue" SG_ 149 ABS_Active "3h";
BA_ "GenSigTimeoutTime_ALL" SG_ 149 AYC_Active 500;
BA_ "InvalidValue" SG_ 149 AYC_Active "3h";
BA_ "GenSigTimeoutTime_ALL" SG_ 149 ASR_Active 500;
BA_ "InvalidValue" SG_ 149 ASR_Active "3h";
BA_ "GenSigTimeoutTime_ALL" SG_ 149 STAT_DSC 500;
BA_ "InvalidValue" SG_ 149 STAT_DSC "3h";
BA_ "GenSigTimeoutTime_ALL" SG_ 149 DSC_Active 500;
BA_ "InvalidValue" SG_ 149 DSC_Active "3h";
BA_ "GenSigTimeoutTime_ALL" SG_ 149 HBA_ActiveSignal 500;
BA_ "InvalidValue" SG_ 149 HBA_ActiveSignal "3h";
BA_ "GenSigTimeoutTime_ALL" SG_ 149 ARM_ActiveSignal 500;
BA_ "InvalidValue" SG_ 149 ARM_ActiveSignal "3h";
BA_ "GenSigTimeoutTime_ALL" SG_ 149 STAT_AutoHazardBlinking 500;
BA_ "InvalidValue" SG_ 149 STAT_AutoHazardBlinking "3h";
BA_ "GenSigTimeoutTime_ALL" SG_ 149 MSR_Active 500;
BA_ "InvalidValue" SG_ 149 MSR_Active "3h";
BA_ "GenSigTimeoutTime_ALL" SG_ 149 HSA_ActiveSignal 500;
BA_ "InvalidValue" SG_ 149 HSA_ActiveSignal "3h";
BA_ "GenSigTimeoutTime_ALL" SG_ 149 EPBi_ECD_ActiveSignal 500;
BA_ "InvalidValue" SG_ 149 EPBi_ECD_ActiveSignal "3h";
BA_ "GenSigTimeoutTime_ALL" SG_ 149 TSM_Active 500;
BA_ "InvalidValue" SG_ 149 TSM_Active "3h";
BA_ "GenSigTimeoutTime_ALL" SG_ 149 HAS_Available 500;
BA_ "InvalidValue" SG_ 149 HAS_Available "3h";
BA_ "GenSigTimeoutTime_ALL" SG_ 149 STAT_EBD 500;
BA_ "InvalidValue" SG_ 149 STAT_EBD "3h";
BA_ "GenSigTimeoutTime_ALL" SG_ 149 EBD_Active 500;
BA_ "InvalidValue" SG_ 149 EBD_Active "3h";
BA_ "GenSigTimeoutTime_ALL" SG_ 149 ST_BRG_MSA 500;
BA_ "InvalidValue" SG_ 149 ST_BRG_MSA "Fh";
BA_ "GenSigTimeoutTime_ALL" SG_ 217 CRC_VCU_HV_DrvSys_status 400;
BA_ "InvalidValue" SG_ 217 CRC_VCU_HV_DrvSys_status "null";
BA_ "GenSigTimeoutTime_ALL" SG_ 217 ALIV_VCU_HV_DrvSys_status 200;
BA_ "InvalidValue" SG_ 217 ALIV_VCU_HV_DrvSys_status "Fh";
BA_ "GenSigTimeoutTime_ALL" SG_ 217 VCU_HVsystem_status 200;
BA_ "InvalidValue" SG_ 217 VCU_HVsystem_status "null";
BA_ "GenSigTimeoutTime_ALL" SG_ 217 VCU_ACPD_Percent 400;
BA_ "InvalidValue" SG_ 217 VCU_ACPD_Percent "FFFh";
BA_ "GenSigTimeoutTime_ALL" SG_ 217 VCU_ACPD_Percent_Valid 400;
BA_ "InvalidValue" SG_ 217 VCU_ACPD_Percent_Valid "null";
BA_ "GenSigTimeoutTime_ALL" SG_ 217 VCU_ACTGear 400;
BA_ "InvalidValue" SG_ 217 VCU_ACTGear "null";
BA_ "GenSigTimeoutTime_ALL" SG_ 217 VCU_ACTGearValid 200;
BA_ "InvalidValue" SG_ 217 VCU_ACTGearValid "null";
BA_ "GenSigTimeoutTime_ALL" SG_ 217 VCU_ACT_DriveMode 200;
BA_ "InvalidValue" SG_ 217 VCU_ACT_DriveMode "null";
BA_ "GenSigStartValue" SG_ 217 VCU_ACT_DriveMode_Valid 1;
BA_ "GenSigTimeoutTime_ALL" SG_ 217 VCU_ACT_DriveMode_Valid 400;
BA_ "InvalidValue" SG_ 217 VCU_ACT_DriveMode_Valid "null";
BA_ "GenSigTimeoutTime_ALL" SG_ 217 VCU_HV_DRVsystem_status 400;
BA_ "InvalidValue" SG_ 217 VCU_HV_DRVsystem_status "null";
BA_ "GenSigTimeoutTime_ALL" SG_ 217 VCU_Recu_BrakeLight_ON_Req 200;
BA_ "InvalidValue" SG_ 217 VCU_Recu_BrakeLight_ON_Req "3h";
BA_ "GenSigTimeoutTime_ALL" SG_ 256 CHKSM_MHU_VEH_INFO 5000;
BA_ "InvalidValue" SG_ 256 CHKSM_MHU_VEH_INFO "null";
BA_ "GenSigTimeoutTime_ALL" SG_ 256 ALV_MHU_VEH_INFO 5000;
BA_ "InvalidValue" SG_ 256 ALV_MHU_VEH_INFO "Fh";
BA_ "GenSigTimeoutTime_ALL" SG_ 256 MHU_UserProfileId 5000;
BA_ "InvalidValue" SG_ 256 MHU_UserProfileId "Fh";
BA_ "GenSigTimeoutTime_ALL" SG_ 256 MHU_Connectivity_Status 5000;
BA_ "InvalidValue" SG_ 256 MHU_Connectivity_Status "0";
BA_ "GenSigTimeoutTime_ALL" SG_ 258 CHKSM_BCM_LOGICAL_CLAMP 500;
BA_ "InvalidValue" SG_ 258 CHKSM_BCM_LOGICAL_CLAMP "null";
BA_ "GenSigTimeoutTime_ALL" SG_ 258 ALIVE_BCM_LOGICAL_CLAMP 500;
BA_ "InvalidValue" SG_ 258 ALIVE_BCM_LOGICAL_CLAMP "Fh";
BA_ "GenSigTimeoutTime_ALL" SG_ 258 STAT_CL30s_Light_L 500;
BA_ "InvalidValue" SG_ 258 STAT_CL30s_Light_L "3h";
BA_ "GenSigStartValue" SG_ 258 STAT_CL30s_L 3;
BA_ "GenSigTimeoutTime_ALL" SG_ 258 STAT_CL30s_L 500;
BA_ "InvalidValue" SG_ 258 STAT_CL30s_L "3h";
BA_ "GenSigStartValue" SG_ 258 STAT_CL15Wup_L 3;
BA_ "GenSigTimeoutTime_ALL" SG_ 258 STAT_CL15Wup_L 500;
BA_ "InvalidValue" SG_ 258 STAT_CL15Wup_L "3h";
BA_ "GenSigTimeoutTime_ALL" SG_ 258 STAT_CrankRelayHW_BCM 500;
BA_ "InvalidValue" SG_ 258 STAT_CrankRelayHW_BCM "3h";
BA_ "GenSigSendType" SG_ 259 REQ_ConsumerControlSeatMassage 3;
BA_ "GenSigTimeoutTime_ALL" SG_ 259 REQ_ConsumerControlSeatMassage 5000;
BA_ "InvalidValue" SG_ 259 REQ_ConsumerControlSeatMassage "3h";
BA_ "GenSigSendType" SG_ 259 REQ_ConsumerControlWirelessCharg 3;
BA_ "GenSigTimeoutTime_ALL" SG_ 259 REQ_ConsumerControlWirelessCharg 5000;
BA_ "InvalidValue" SG_ 259 REQ_ConsumerControlWirelessCharg "3h";
BA_ "GenSigSendType" SG_ 259 REQ_ConsumerControlAudioVolumeCo 3;
BA_ "GenSigTimeoutTime_ALL" SG_ 259 REQ_ConsumerControlAudioVolumeCo 5000;
BA_ "InvalidValue" SG_ 259 REQ_ConsumerControlAudioVolumeCo "7h";
BA_ "GenSigSendType" SG_ 259 REQ_CCU_PTC_Limitation 3;
BA_ "GenSigTimeoutTime_ALL" SG_ 259 REQ_CCU_PTC_Limitation 5000;
BA_ "InvalidValue" SG_ 259 REQ_CCU_PTC_Limitation "7h";
BA_ "GenSigSendType" SG_ 259 REQ_ConsumerControlRearDefrost 3;
BA_ "GenSigTimeoutTime_ALL" SG_ 259 REQ_ConsumerControlRearDefrost 5000;
BA_ "InvalidValue" SG_ 259 REQ_ConsumerControlRearDefrost "3h";
BA_ "GenSigSendType" SG_ 259 REQ_ConsumerControlSeatHeatingRe 3;
BA_ "GenSigTimeoutTime_ALL" SG_ 259 REQ_ConsumerControlSeatHeatingRe 5000;
BA_ "InvalidValue" SG_ 259 REQ_ConsumerControlSeatHeatingRe "FFh";
BA_ "GenSigSendType" SG_ 259 REQ_ConsumerControlSeatVentilati 3;
BA_ "GenSigTimeoutTime_ALL" SG_ 259 REQ_ConsumerControlSeatVentilati 5000;
BA_ "InvalidValue" SG_ 259 REQ_ConsumerControlSeatVentilati "FFh";
BA_ "GenSigSendType" SG_ 259 REQ_ConsumerControlSeatHeatingFr 3;
BA_ "GenSigTimeoutTime_ALL" SG_ 259 REQ_ConsumerControlSeatHeatingFr 5000;
BA_ "InvalidValue" SG_ 259 REQ_ConsumerControlSeatHeatingFr "FFh";
BA_ "GenSigSendType" SG_ 259 DriverIdealTimerCount 3;
BA_ "GenSigTimeoutTime_ALL" SG_ 259 DriverIdealTimerCount 5000;
BA_ "InvalidValue" SG_ 259 DriverIdealTimerCount "FFh";
BA_ "GenSigSendType" SG_ 259 REQ_ConsumerControlVentilationCl 3;
BA_ "GenSigStartValue" SG_ 259 REQ_ConsumerControlVentilationCl 100;
BA_ "GenSigTimeoutTime_ALL" SG_ 259 REQ_ConsumerControlVentilationCl 5000;
BA_ "InvalidValue" SG_ 259 REQ_ConsumerControlVentilationCl "FFh";
BA_ "GenSigTimeoutTime_ALL" SG_ 260 CHKSM_LV_BATT_CHARG 500;
BA_ "InvalidValue" SG_ 260 CHKSM_LV_BATT_CHARG "null";
BA_ "GenSigTimeoutTime_ALL" SG_ 260 ALIV_LV_BATT_CHARG 500;
BA_ "InvalidValue" SG_ 260 ALIV_LV_BATT_CHARG "Fh";
BA_ "GenSigStartValue" SG_ 260 SOH_SUL 255;
BA_ "GenSigTimeoutTime_ALL" SG_ 260 SOH_SUL 500;
BA_ "InvalidValue" SG_ 260 SOH_SUL "FFh";
BA_ "GenSigStartValue" SG_ 260 SOH_SUL_STATE 3;
BA_ "GenSigTimeoutTime_ALL" SG_ 260 SOH_SUL_STATE 500;
BA_ "InvalidValue" SG_ 260 SOH_SUL_STATE "3h";
BA_ "GenSigStartValue" SG_ 260 SOC_STATE 3;
BA_ "GenSigTimeoutTime_ALL" SG_ 260 SOC_STATE 500;
BA_ "InvalidValue" SG_ 260 SOC_STATE "3h";
BA_ "GenSigTimeoutTime_ALL" SG_ 260 Resp_Error 500;
BA_ "InvalidValue" SG_ 260 Resp_Error "null";
BA_ "GenSigTimeoutTime_ALL" SG_ 260 FLAG_INCONSTENCY 500;
BA_ "InvalidValue" SG_ 260 FLAG_INCONSTENCY "null";
BA_ "GenSigTimeoutTime_ALL" SG_ 260 EBS_error 500;
BA_ "InvalidValue" SG_ 260 EBS_error "null";
BA_ "GenSigTimeoutTime_ALL" SG_ 260 FLAG_DISCONNECT 500;
BA_ "InvalidValue" SG_ 260 FLAG_DISCONNECT "null";
BA_ "GenSigTimeoutTime_ALL" SG_ 260 BCM_LV_Batt_Charging_Req 500;
BA_ "InvalidValue" SG_ 260 BCM_LV_Batt_Charging_Req "null";
BA_ "GenSigTimeoutTime_ALL" SG_ 260 IBATT_QUIESCENT 500;
BA_ "GenSigStartValue" SG_ 260 LV_TargetVoltage 26;
BA_ "GenSigTimeoutTime_ALL" SG_ 260 LV_TargetVoltage 500;
BA_ "InvalidValue" SG_ 260 LV_TargetVoltage "-";
BA_ "GenSigStartValue" SG_ 260 LV_TargetCurrent 512;
BA_ "GenSigTimeoutTime_ALL" SG_ 260 LV_TargetCurrent 500;
BA_ "InvalidValue" SG_ 260 LV_TargetCurrent "-";
BA_ "GenSigTimeoutTime_ALL" SG_ 261 CHKSM_BCM_STAT_DOOR_FLAP 500;
BA_ "InvalidValue" SG_ 261 CHKSM_BCM_STAT_DOOR_FLAP "null";
BA_ "GenSigTimeoutTime_ALL" SG_ 261 ALIVE_BCM_STAT_DOOR_FLAP 500;
BA_ "InvalidValue" SG_ 261 ALIVE_BCM_STAT_DOOR_FLAP "Fh";
BA_ "GenSigTimeoutTime_ALL" SG_ 261 BCM_STAT_TrunkAjar 500;
BA_ "InvalidValue" SG_ 261 BCM_STAT_TrunkAjar "3h";
BA_ "GenSigTimeoutTime_ALL" SG_ 261 BCM_STAT_DoorAjarFL 500;
BA_ "InvalidValue" SG_ 261 BCM_STAT_DoorAjarFL "3h";
BA_ "GenSigTimeoutTime_ALL" SG_ 261 BCM_STAT_DoorAjarFR 500;
BA_ "InvalidValue" SG_ 261 BCM_STAT_DoorAjarFR "3h";
BA_ "GenSigTimeoutTime_ALL" SG_ 261 BCM_STAT_DoorAjarRL 500;
BA_ "InvalidValue" SG_ 261 BCM_STAT_DoorAjarRL "3h";
BA_ "GenSigTimeoutTime_ALL" SG_ 261 BCM_STAT_DoorAjarRR 500;
BA_ "InvalidValue" SG_ 261 BCM_STAT_DoorAjarRR "3h";
BA_ "GenSigTimeoutTime_ALL" SG_ 261 BCM_STAT_BonnetAjar 500;
BA_ "InvalidValue" SG_ 261 BCM_STAT_BonnetAjar "3h";
BA_ "GenSigTimeoutTime_ALL" SG_ 262 CHKSM_BCM_LIGHT 500;
BA_ "InvalidValue" SG_ 262 CHKSM_BCM_LIGHT "null";
BA_ "GenSigTimeoutTime_ALL" SG_ 262 ALIVE_BCM_LIGHT 500;
BA_ "InvalidValue" SG_ 262 ALIVE_BCM_LIGHT "Fh";
BA_ "GenSigTimeoutTime_ALL" SG_ 262 BCM_DayRunningLampSts 500;
BA_ "InvalidValue" SG_ 262 BCM_DayRunningLampSts "3h";
BA_ "GenSigTimeoutTime_ALL" SG_ 262 BCM_ReverseLightSts 500;
BA_ "InvalidValue" SG_ 262 BCM_ReverseLightSts "3h";
BA_ "GenSigTimeoutTime_ALL" SG_ 262 BCM_StopLightSts 500;
BA_ "InvalidValue" SG_ 262 BCM_StopLightSts "3h";
BA_ "GenSigTimeoutTime_ALL" SG_ 262 BCM_LicensePlateLightSts 500;
BA_ "InvalidValue" SG_ 262 BCM_LicensePlateLightSts "3h";
BA_ "GenSigTimeoutTime_ALL" SG_ 262 BCM_Fr_Dimming_dome_lampSts 500;
BA_ "InvalidValue" SG_ 262 BCM_Fr_Dimming_dome_lampSts "3h";
BA_ "GenSigTimeoutTime_ALL" SG_ 262 BCM_Rr_Dimming_dome_lampSts 500;
BA_ "InvalidValue" SG_ 262 BCM_Rr_Dimming_dome_lampSts "3h";
BA_ "GenSigStartValue" SG_ 262 BCM_STAT_InteriorLight 3;
BA_ "GenSigTimeoutTime_ALL" SG_ 262 BCM_STAT_InteriorLight 500;
BA_ "InvalidValue" SG_ 262 BCM_STAT_InteriorLight "3h";
BA_ "GenSigStartValue" SG_ 262 BCM_STAT_LightActivation 7;
BA_ "GenSigTimeoutTime_ALL" SG_ 262 BCM_STAT_LightActivation 500;
BA_ "InvalidValue" SG_ 262 BCM_STAT_LightActivation "7h";
BA_ "GenSigTimeoutTime_ALL" SG_ 262 BCM_HighBeamSts 500;
BA_ "InvalidValue" SG_ 262 BCM_HighBeamSts "3h";
BA_ "GenSigStartValue" SG_ 262 BCM_STAT_SwitchLightBrightness 80;
BA_ "GenSigTimeoutTime_ALL" SG_ 262 BCM_STAT_SwitchLightBrightness 500;
BA_ "InvalidValue" SG_ 262 BCM_STAT_SwitchLightBrightness "7Fh";
BA_ "GenSigTimeoutTime_ALL" SG_ 262 BCM_LowBeamSts 500;
BA_ "InvalidValue" SG_ 262 BCM_LowBeamSts "3h";
BA_ "GenSigTimeoutTime_ALL" SG_ 262 BCM_RearFogLmpSts 500;
BA_ "InvalidValue" SG_ 262 BCM_RearFogLmpSts "3h";
BA_ "GenSigTimeoutTime_ALL" SG_ 262 BCM_FrntFogLmpSts 500;
BA_ "InvalidValue" SG_ 262 BCM_FrntFogLmpSts "3h";
BA_ "GenSigTimeoutTime_ALL" SG_ 262 BCM_PosLmpSts 500;
BA_ "InvalidValue" SG_ 262 BCM_PosLmpSts "3h";
BA_ "GenSigTimeoutTime_ALL" SG_ 262 BCM_BackGrdCl58Sts 500;
BA_ "InvalidValue" SG_ 262 BCM_BackGrdCl58Sts "3h";
BA_ "GenSigTimeoutTime_ALL" SG_ 262 BCM_HornSts 500;
BA_ "InvalidValue" SG_ 262 BCM_HornSts "3h";
BA_ "GenSigSendType" SG_ 262 BCM_TurnIndicatorSts 3;
BA_ "GenSigTimeoutTime_ALL" SG_ 262 BCM_TurnIndicatorSts 500;
BA_ "InvalidValue" SG_ 262 BCM_TurnIndicatorSts "3h";
BA_ "GenSigTimeoutTime_ALL" SG_ 263 CHKSM_BCM_CENTRAL_LOCK 500;
BA_ "InvalidValue" SG_ 263 CHKSM_BCM_CENTRAL_LOCK "null";
BA_ "GenSigTimeoutTime_ALL" SG_ 263 ALV_BCM_CENTRAL_LOCK 500;
BA_ "InvalidValue" SG_ 263 ALV_BCM_CENTRAL_LOCK "Fh";
BA_ "GenSigTimeoutTime_ALL" SG_ 263 STAT_CDL_LED 500;
BA_ "InvalidValue" SG_ 263 STAT_CDL_LED "3h";
BA_ "GenSigTimeoutTime_ALL" SG_ 263 STAT_DoorUnlockFL 500;
BA_ "InvalidValue" SG_ 263 STAT_DoorUnlockFL "3h";
BA_ "GenSigTimeoutTime_ALL" SG_ 263 STAT_ATWS 500;
BA_ "InvalidValue" SG_ 263 STAT_ATWS "7h";
BA_ "GenSigTimeoutTime_ALL" SG_ 263 BCM_CentralLockSwSts 500;
BA_ "InvalidValue" SG_ 263 BCM_CentralLockSwSts "1h";
BA_ "GenSigTimeoutTime_ALL" SG_ 263 STAT_DoorLockFL 500;
BA_ "InvalidValue" SG_ 263 STAT_DoorLockFL "3h";
BA_ "GenSigTimeoutTime_ALL" SG_ 265 CHKSM_BCM_SWITCH_Sts 500;
BA_ "InvalidValue" SG_ 265 CHKSM_BCM_SWITCH_Sts "null";
BA_ "GenSigTimeoutTime_ALL" SG_ 265 ALV_BCM_SWITCH_Sts 500;
BA_ "InvalidValue" SG_ 265 ALV_BCM_SWITCH_Sts "Fh";
BA_ "GenSigSendType" SG_ 265 BCM_STAT_BrakeSwitch 4;
BA_ "GenSigTimeoutTime_ALL" SG_ 265 BCM_STAT_BrakeSwitch 500;
BA_ "InvalidValue" SG_ 265 BCM_STAT_BrakeSwitch "3h";
BA_ "GenSigSendType" SG_ 265 BCM_STAT_HazardWarn 4;
BA_ "GenSigTimeoutTime_ALL" SG_ 265 BCM_STAT_HazardWarn 500;
BA_ "InvalidValue" SG_ 265 BCM_STAT_HazardWarn "3h";
BA_ "GenSigSendType" SG_ 265 BCM_STAT_FuelPumpCutOFF 4;
BA_ "GenSigTimeoutTime_ALL" SG_ 265 BCM_STAT_FuelPumpCutOFF 500;
BA_ "InvalidValue" SG_ 265 BCM_STAT_FuelPumpCutOFF "3h";
BA_ "GenSigTimeoutTime_ALL" SG_ 265 BCM_FollowMeHomeActive 500;
BA_ "InvalidValue" SG_ 265 BCM_FollowMeHomeActive "3h";
BA_ "GenSigSendType" SG_ 265 BCM_STAT_Horn 4;
BA_ "GenSigTimeoutTime_ALL" SG_ 265 BCM_STAT_Horn 500;
BA_ "InvalidValue" SG_ 265 BCM_STAT_Horn "3h";
BA_ "GenSigSendType" SG_ 265 BCM_STAT_Autowiping 4;
BA_ "GenSigTimeoutTime_ALL" SG_ 265 BCM_STAT_Autowiping 500;
BA_ "InvalidValue" SG_ 265 BCM_STAT_Autowiping "3h";
BA_ "GenSigTimeoutTime_ALL" SG_ 265 BCM_TurnIndicator 500;
BA_ "InvalidValue" SG_ 265 BCM_TurnIndicator "3h";
BA_ "GenSigTimeoutTime_ALL" SG_ 265 BCM_WelcomeActive 500;
BA_ "InvalidValue" SG_ 265 BCM_WelcomeActive "3h";
BA_ "GenSigTimeoutTime_ALL" SG_ 265 BCM_HighBeam 500;
BA_ "InvalidValue" SG_ 265 BCM_HighBeam "3h";
BA_ "GenSigTimeoutTime_ALL" SG_ 265 ACM_Seat_Belt_Status_3rd_Row_Pas 500;
BA_ "InvalidValue" SG_ 265 ACM_Seat_Belt_Status_3rd_Row_Pas "null";
BA_ "GenSigTimeoutTime_ALL" SG_ 265 ACM_Seat_Belt_Status_3rd_Row_Dri 500;
BA_ "InvalidValue" SG_ 265 ACM_Seat_Belt_Status_3rd_Row_Dri "null";
BA_ "GenSigTimeoutTime_ALL" SG_ 265 BCM_AlcoholockSwitch 500;
BA_ "GenSigTimeoutTime_ALL" SG_ 266 CHKSM_BCM_VOLTAGE 2500;
BA_ "InvalidValue" SG_ 266 CHKSM_BCM_VOLTAGE "null";
BA_ "GenSigTimeoutTime_ALL" SG_ 266 ALIVE_BCM_VOLTAGE 2500;
BA_ "InvalidValue" SG_ 266 ALIVE_BCM_VOLTAGE "Fh";
BA_ "GenSigStartValue" SG_ 266 UBatt 9205;
BA_ "GenSigTimeoutTime_ALL" SG_ 266 UBatt 2500;
BA_ "InvalidValue" SG_ 266 UBatt "3FFFh";
BA_ "GenSigStartValue" SG_ 266 LV_Batt_Temp 40;
BA_ "GenSigTimeoutTime_ALL" SG_ 266 LV_Batt_Temp 2500;
BA_ "InvalidValue" SG_ 266 LV_Batt_Temp "FFh";
BA_ "GenSigTimeoutTime_ALL" SG_ 266 LV_SOC 2500;
BA_ "InvalidValue" SG_ 266 LV_SOC "FFh";
BA_ "GenSigStartValue" SG_ 266 LV_Batt_Current 49152;
BA_ "GenSigTimeoutTime_ALL" SG_ 266 LV_Batt_Current 2500;
BA_ "InvalidValue" SG_ 266 LV_Batt_Current "FFFFh";
BA_ "GenSigTimeoutTime_ALL" SG_ 266 LV_BatteryType 2500;
BA_ "InvalidValue" SG_ 266 LV_BatteryType "-";
BA_ "GenSigTimeoutTime_ALL" SG_ 267 ALIVE_TRM_LIGHT 500;
BA_ "InvalidValue" SG_ 267 ALIVE_TRM_LIGHT "Fh";
BA_ "GenSigStartValue" SG_ 267 TrailerInput 3;
BA_ "GenSigTimeoutTime_ALL" SG_ 267 TrailerInput 500;
BA_ "InvalidValue" SG_ 267 TrailerInput "3h";
BA_ "GenSigStartValue" SG_ 267 TrailerSystemError 3;
BA_ "GenSigTimeoutTime_ALL" SG_ 267 TrailerSystemError 500;
BA_ "InvalidValue" SG_ 267 TrailerSystemError "3h";
BA_ "GenSigTimeoutTime_ALL" SG_ 267 TRM_VoltageStatus 500;
BA_ "InvalidValue" SG_ 267 TRM_VoltageStatus "3h";
BA_ "GenSigTimeoutTime_ALL" SG_ 267 TRM_STAT_BrakeLight 500;
BA_ "InvalidValue" SG_ 267 TRM_STAT_BrakeLight "3h";
BA_ "GenSigTimeoutTime_ALL" SG_ 267 TRM_STAT_FogLampRear 500;
BA_ "InvalidValue" SG_ 267 TRM_STAT_FogLampRear "3h";
BA_ "GenSigTimeoutTime_ALL" SG_ 267 TRM_STAT_PositionLight 500;
BA_ "InvalidValue" SG_ 267 TRM_STAT_PositionLight "3h";
BA_ "GenSigTimeoutTime_ALL" SG_ 267 TRM_STAT_TurnIndicators 500;
BA_ "InvalidValue" SG_ 267 TRM_STAT_TurnIndicators "Fh";
BA_ "GenSigTimeoutTime_ALL" SG_ 267 TRM_STAT_ReverseLight 500;
BA_ "InvalidValue" SG_ 267 TRM_STAT_ReverseLight "3h";
BA_ "GenSigTimeoutTime_ALL" SG_ 267 TRM_STAT_HWBrakeLightInput 500;
BA_ "InvalidValue" SG_ 267 TRM_STAT_HWBrakeLightInput "3h";
BA_ "GenSigTimeoutTime_ALL" SG_ 267 TRM_STAT_HWIndicatorInput 500;
BA_ "InvalidValue" SG_ 267 TRM_STAT_HWIndicatorInput "3h";
BA_ "GenSigTimeoutTime_ALL" SG_ 267 TRM_STAT_HWPosLightInput 500;
BA_ "InvalidValue" SG_ 267 TRM_STAT_HWPosLightInput "3h";
BA_ "GenSigTimeoutTime_ALL" SG_ 268 Checksum_0x10C 500;
BA_ "InvalidValue" SG_ 268 Checksum_0x10C "null";
BA_ "GenSigTimeoutTime_ALL" SG_ 268 Rolling_Counter_0x10C 500;
BA_ "InvalidValue" SG_ 268 Rolling_Counter_0x10C "Fh";
BA_ "GenSigTimeoutTime_ALL" SG_ 268 BCM_TboxAuthStatus 500;
BA_ "InvalidValue" SG_ 268 BCM_TboxAuthStatus "3h";
BA_ "GenSigTimeoutTime_ALL" SG_ 268 BCM_RandomNum32bit 500;
BA_ "InvalidValue" SG_ 268 BCM_RandomNum32bit "null";
BA_ "GenSigSendType" SG_ 269 MHU_APM_ReqWindow 2;
BA_ "InvalidValue" SG_ 269 MHU_APM_ReqWindow "3h";
BA_ "GenSigSendType" SG_ 269 MHU_BCM_RemoteDoorCtrl 2;
BA_ "GenSigStartValue" SG_ 269 MHU_BCM_RemoteDoorCtrl 2;
BA_ "InvalidValue" SG_ 269 MHU_BCM_RemoteDoorCtrl "3h";
BA_ "GenSigSendType" SG_ 269 MHU_BCM_reqTrunk 2;
BA_ "GenSigStartValue" SG_ 269 MHU_BCM_reqTrunk 2;
BA_ "InvalidValue" SG_ 269 MHU_BCM_reqTrunk "3h";
BA_ "GenSigSendType" SG_ 269 MHU_BCM_reqFrunk 2;
BA_ "InvalidValue" SG_ 269 MHU_BCM_reqFrunk "3h";
BA_ "GenSigSendType" SG_ 269 MHU_BCM_ReqSunroof 2;
BA_ "GenSigStartValue" SG_ 269 MHU_BCM_ReqSunroof 255;
BA_ "InvalidValue" SG_ 269 MHU_BCM_ReqSunroof "FFh";
BA_ "GenSigSendType" SG_ 269 TBOX_AuthCode_0x10D 2;
BA_ "GenSigTimeoutTime_ALL" SG_ 270 GlobalWindowReq 500;
BA_ "GenSigSendType" SG_ 270 RemoteAccessKey 4;
BA_ "GenSigTimeoutTime_ALL" SG_ 270 RemoteAccessKey 500;
BA_ "InvalidValue" SG_ 270 RemoteAccessKey "Fh";
BA_ "GenSigSendType" SG_ 270 PassiveAccessTrunk 4;
BA_ "GenSigTimeoutTime_ALL" SG_ 270 PassiveAccessTrunk 500;
BA_ "InvalidValue" SG_ 270 PassiveAccessTrunk "3h";
BA_ "GenSigSendType" SG_ 270 ComfortOpen 4;
BA_ "GenSigStartValue" SG_ 270 ComfortOpen 3;
BA_ "GenSigTimeoutTime_ALL" SG_ 270 ComfortOpen 500;
BA_ "InvalidValue" SG_ 270 ComfortOpen "3h";
BA_ "GenSigSendType" SG_ 270 PassiveAccessDoor 4;
BA_ "GenSigTimeoutTime_ALL" SG_ 270 PassiveAccessDoor 500;
BA_ "InvalidValue" SG_ 270 PassiveAccessDoor "3h";
BA_ "GenSigSendType" SG_ 270 FksOpen 4;
BA_ "GenSigTimeoutTime_ALL" SG_ 270 FksOpen 500;
BA_ "InvalidValue" SG_ 270 FksOpen "3h";
BA_ "GenSigSendType" SG_ 271 MHU_SetHornOnOff 2;
BA_ "GenSigStartValue" SG_ 271 MHU_SetHornOnOff 2;
BA_ "InvalidValue" SG_ 271 MHU_SetHornOnOff "3h";
BA_ "GenSigSendType" SG_ 271 MHU_SetLowBeam 2;
BA_ "GenSigStartValue" SG_ 271 MHU_SetLowBeam 2;
BA_ "InvalidValue" SG_ 271 MHU_SetLowBeam "3h";
BA_ "GenSigSendType" SG_ 271 MHU_SetHighBeam 2;
BA_ "GenSigStartValue" SG_ 271 MHU_SetHighBeam 2;
BA_ "InvalidValue" SG_ 271 MHU_SetHighBeam "3h";
BA_ "GenSigSendType" SG_ 271 TBOX_AuthCode_0x10F 2;
BA_ "GenSigTimeoutTime_ALL" SG_ 273 BCM_Stat_SwitchLightBrightness 500;
BA_ "InvalidValue" SG_ 273 BCM_Stat_SwitchLightBrightness "null";
BA_ "GenSigTimeoutTime_ALL" SG_ 273 BCM_Rear_Wiper_Park_Pos_Status 500;
BA_ "GenSigTimeoutTime_ALL" SG_ 273 BCM_Front_Wiper_Park_Pos_Status 500;
BA_ "GenSigTimeoutTime_ALL" SG_ 273 BCM_Rear_Wash_Status 500;
BA_ "GenSigTimeoutTime_ALL" SG_ 273 BCM_Front_Wash_Status 500;
BA_ "GenSigTimeoutTime_ALL" SG_ 274 CHKSM_BCM_CLAMP_STAT 500;
BA_ "InvalidValue" SG_ 274 CHKSM_BCM_CLAMP_STAT "null";
BA_ "GenSigTimeoutTime_ALL" SG_ 274 ALIVE_BCM_CLAMP_STAT 500;
BA_ "InvalidValue" SG_ 274 ALIVE_BCM_CLAMP_STAT "Fh";
BA_ "GenSigSendType" SG_ 274 RemoteFunctionState 4;
BA_ "GenSigTimeoutTime_ALL" SG_ 274 RemoteFunctionState 500;
BA_ "InvalidValue" SG_ 274 RemoteFunctionState "3h";
BA_ "GenSigTimeoutTime_ALL" SG_ 274 STAT_BLS 500;
BA_ "InvalidValue" SG_ 274 STAT_BLS "3h";
BA_ "GenSigTimeoutTime_ALL" SG_ 274 STAT_CL_50_L 500;
BA_ "InvalidValue" SG_ 274 STAT_CL_50_L "3h";
BA_ "GenSigSendType" SG_ 274 Clamp50AdviceRemoteStart 4;
BA_ "GenSigTimeoutTime_ALL" SG_ 274 Clamp50AdviceRemoteStart 500;
BA_ "InvalidValue" SG_ 274 Clamp50AdviceRemoteStart "3h";
BA_ "GenSigSendType" SG_ 274 Clamp50AdviceESS 4;
BA_ "GenSigTimeoutTime_ALL" SG_ 274 Clamp50AdviceESS 500;
BA_ "InvalidValue" SG_ 274 Clamp50AdviceESS "3h";
BA_ "GenSigTimeoutTime_ALL" SG_ 274 STAT_TransportMode 500;
BA_ "GenSigTimeoutTime_ALL" SG_ 274 STAT_CL_R_L 500;
BA_ "InvalidValue" SG_ 274 STAT_CL_R_L "3h";
BA_ "GenSigTimeoutTime_ALL" SG_ 274 STAT_CL_15_1_L 500;
BA_ "InvalidValue" SG_ 274 STAT_CL_15_1_L "3h";
BA_ "GenSigTimeoutTime_ALL" SG_ 274 STAT_CL_15_1_DME_L 500;
BA_ "InvalidValue" SG_ 274 STAT_CL_15_1_DME_L "3h";
BA_ "GenSigTimeoutTime_ALL" SG_ 274 FobId 500;
BA_ "InvalidValue" SG_ 274 FobId "3h";
BA_ "GenSigTimeoutTime_ALL" SG_ 274 STAT_Terminal 500;
BA_ "InvalidValue" SG_ 274 STAT_Terminal "7h";
BA_ "GenSigTimeoutTime_ALL" SG_ 274 STAT_CL30_C_BEV 500;
BA_ "InvalidValue" SG_ 274 STAT_CL30_C_BEV "3h";
BA_ "GenSigTimeoutTime_ALL" SG_ 274 BCM_Clamp_Transport 500;
BA_ "InvalidValue" SG_ 274 BCM_Clamp_Transport "7h";
BA_ "GenSigTimeoutTime_ALL" SG_ 276 CHKSM_LVBAT_DATA 500;
BA_ "InvalidValue" SG_ 276 CHKSM_LVBAT_DATA "-";
BA_ "GenSigTimeoutTime_ALL" SG_ 276 ALIV_LVBAT_DATA 500;
BA_ "InvalidValue" SG_ 276 ALIV_LVBAT_DATA "Fh";
BA_ "GenSigTimeoutTime_ALL" SG_ 276 LV_ErrorSts 500;
BA_ "InvalidValue" SG_ 276 LV_ErrorSts "7h";
BA_ "GenSigTimeoutTime_ALL" SG_ 276 LV_MinCellVolt 500;
BA_ "InvalidValue" SG_ 276 LV_MinCellVolt "-";
BA_ "GenSigTimeoutTime_ALL" SG_ 276 LV_MaxCellVolt 500;
BA_ "InvalidValue" SG_ 276 LV_MaxCellVolt "-";
BA_ "GenSigStartValue" SG_ 276 LV_MinCellTemp 40;
BA_ "GenSigTimeoutTime_ALL" SG_ 276 LV_MinCellTemp 500;
BA_ "InvalidValue" SG_ 276 LV_MinCellTemp "-";
BA_ "GenSigStartValue" SG_ 276 LV_MaxCellTemp 40;
BA_ "GenSigTimeoutTime_ALL" SG_ 276 LV_MaxCellTemp 500;
BA_ "InvalidValue" SG_ 276 LV_MaxCellTemp "-";
BA_ "GenSigTimeoutTime_ALL" SG_ 276 LV_Discharger_Err 500;
BA_ "InvalidValue" SG_ 276 LV_Discharger_Err "-";
BA_ "GenSigTimeoutTime_ALL" SG_ 276 LV_Discharger_Sts 500;
BA_ "InvalidValue" SG_ 276 LV_Discharger_Sts "-";
BA_ "GenSigTimeoutTime_ALL" SG_ 276 LV_Charger_Err 500;
BA_ "InvalidValue" SG_ 276 LV_Charger_Err "-";
BA_ "GenSigTimeoutTime_ALL" SG_ 276 LV_Charger_Sts 500;
BA_ "InvalidValue" SG_ 276 LV_Charger_Sts "-";
BA_ "GenSigTimeoutTime_ALL" SG_ 276 LV_OverVoltage 500;
BA_ "InvalidValue" SG_ 276 LV_OverVoltage "-";
BA_ "GenSigTimeoutTime_ALL" SG_ 276 LV_UnderVoltage 500;
BA_ "InvalidValue" SG_ 276 LV_UnderVoltage "-";
BA_ "GenSigTimeoutTime_ALL" SG_ 276 LV_OverCurrent 500;
BA_ "InvalidValue" SG_ 276 LV_OverCurrent "-";
BA_ "GenSigTimeoutTime_ALL" SG_ 276 LV_UnderTemp 500;
BA_ "InvalidValue" SG_ 276 LV_UnderTemp "-";
BA_ "GenSigTimeoutTime_ALL" SG_ 276 LV_OverTemp 500;
BA_ "InvalidValue" SG_ 276 LV_OverTemp "-";
BA_ "GenSigTimeoutTime_ALL" SG_ 276 LV_OverCharge 500;
BA_ "InvalidValue" SG_ 276 LV_OverCharge "-";
BA_ "GenSigTimeoutTime_ALL" SG_ 276 LV_OverDischarge 500;
BA_ "InvalidValue" SG_ 276 LV_OverDischarge "-";
BA_ "GenSigTimeoutTime_ALL" SG_ 276 LV_CellBalance_Sts 500;
BA_ "InvalidValue" SG_ 276 LV_CellBalance_Sts "-";
BA_ "GenSigTimeoutTime_ALL" SG_ 276 LV_CellBalance_Error 500;
BA_ "InvalidValue" SG_ 276 LV_CellBalance_Error "-";
BA_ "GenSigTimeoutTime_ALL" SG_ 276 LV_ThermalRunaway 500;
BA_ "InvalidValue" SG_ 276 LV_ThermalRunaway "-";
BA_ "GenSigTimeoutTime_ALL" SG_ 276 LV_WarmupRequest 500;
BA_ "InvalidValue" SG_ 276 LV_WarmupRequest "3h";
BA_ "GenSigSendType" SG_ 277 BCM_ChildLock_Feedback 1;
BA_ "InvalidValue" SG_ 277 BCM_ChildLock_Feedback "null";
BA_ "GenSigTimeoutTime_ALL" SG_ 278 CHKSM_LVBAT_INFO2 2500;
BA_ "InvalidValue" SG_ 278 CHKSM_LVBAT_INFO2 "-";
BA_ "GenSigTimeoutTime_ALL" SG_ 278 ALIV_LVBAT_INFO2 2500;
BA_ "InvalidValue" SG_ 278 ALIV_LVBAT_INFO2 "Fh";
BA_ "GenSigTimeoutTime_ALL" SG_ 278 LV_MaxAllowDischargeCurrent 2500;
BA_ "InvalidValue" SG_ 278 LV_MaxAllowDischargeCurrent "-";
BA_ "GenSigTimeoutTime_ALL" SG_ 278 LV_WakeupReason 2500;
BA_ "InvalidValue" SG_ 278 LV_WakeupReason "7h";
BA_ "GenSigTimeoutTime_ALL" SG_ 278 LV_MaxAllowChargeCurrent 2500;
BA_ "InvalidValue" SG_ 278 LV_MaxAllowChargeCurrent "-";
BA_ "GenSigTimeoutTime_ALL" SG_ 278 LV_SOE 2500;
BA_ "InvalidValue" SG_ 278 LV_SOE "-";
BA_ "GenSigTimeoutTime_ALL" SG_ 280 CHKSM_BCM_MHU_Ctrl_Fbk 2500;
BA_ "InvalidValue" SG_ 280 CHKSM_BCM_MHU_Ctrl_Fbk "null";
BA_ "GenSigTimeoutTime_ALL" SG_ 280 ALV_BCM_MHU_Ctrl_Fbk 2500;
BA_ "InvalidValue" SG_ 280 ALV_BCM_MHU_Ctrl_Fbk "Fh";
BA_ "GenSigTimeoutTime_ALL" SG_ 280 BCM_DrvInhibitStsFbk 2500;
BA_ "InvalidValue" SG_ 280 BCM_DrvInhibitStsFbk "0h";
BA_ "GenSigSendType" SG_ 282 MHU_SET_WiperServicePositionMod 2;
BA_ "GenSigStartValue" SG_ 282 MHU_SET_WiperServicePositionMod 3;
BA_ "InvalidValue" SG_ 282 MHU_SET_WiperServicePositionMod "null";
BA_ "GenSigSendType" SG_ 282 MHU_Read_KeyFobOnCenterConsole 2;
BA_ "GenSigStartValue" SG_ 282 MHU_Read_KeyFobOnCenterConsole 2;
BA_ "InvalidValue" SG_ 282 MHU_Read_KeyFobOnCenterConsole "null";
BA_ "GenSigSendType" SG_ 283 TBOX_STAT_TerminalReq 2;
BA_ "GenSigStartValue" SG_ 283 TBOX_STAT_TerminalReq 6;
BA_ "InvalidValue" SG_ 283 TBOX_STAT_TerminalReq "7h";
BA_ "GenSigSendType" SG_ 283 TBOX_AuthCode_0x11B 2;
BA_ "InvalidValue" SG_ 283 TBOX_AuthCode_0x11B "null";
BA_ "GenSigSendType" SG_ 284 TBOX_FOTA_STAT_TerminalReq 2;
BA_ "InvalidValue" SG_ 284 TBOX_FOTA_STAT_TerminalReq "7h";
BA_ "GenSigTimeoutTime_ALL" SG_ 285 CCU_ERL_Rear 1000;
BA_ "InvalidValue" SG_ 285 CCU_ERL_Rear "null";
BA_ "GenSigStartValue" SG_ 285 CCU_EvapTempSet_Rear 50;
BA_ "GenSigTimeoutTime_ALL" SG_ 285 CCU_EvapTempSet_Rear 1000;
BA_ "InvalidValue" SG_ 285 CCU_EvapTempSet_Rear "null";
BA_ "GenSigTimeoutTime_ALL" SG_ 285 CCU_AirDistribFlapPos_Rear 1000;
BA_ "InvalidValue" SG_ 285 CCU_AirDistribFlapPos_Rear "null";
BA_ "GenSigTimeoutTime_ALL" SG_ 285 CCU_BlowerFltPwm_Rear 1000;
BA_ "InvalidValue" SG_ 285 CCU_BlowerFltPwm_Rear "null";
BA_ "GenSigStartValue" SG_ 285 CCU_DuctTargetTemp_Rear 80;
BA_ "GenSigTimeoutTime_ALL" SG_ 285 CCU_DuctTargetTemp_Rear 1000;
BA_ "InvalidValue" SG_ 285 CCU_DuctTargetTemp_Rear "null";
BA_ "GenSigTimeoutTime_ALL" SG_ 285 CCU_TempFlapPos_Rear 1000;
BA_ "InvalidValue" SG_ 285 CCU_TempFlapPos_Rear "null";
BA_ "GenSigTimeoutTime_ALL" SG_ 285 CCU_FanSpeed_Rear 1000;
BA_ "InvalidValue" SG_ 285 CCU_FanSpeed_Rear "Fh";
BA_ "GenSigStartValue" SG_ 285 CCUF_InteriorTemp_Rear 80;
BA_ "GenSigTimeoutTime_ALL" SG_ 285 CCUF_InteriorTemp_Rear 5000;
BA_ "InvalidValue" SG_ 285 CCUF_InteriorTemp_Rear "FFh";
BA_ "GenSigStartValue" SG_ 286 CCUR_DuctActRearFace 80;
BA_ "GenSigTimeoutTime_ALL" SG_ 286 CCUR_DuctActRearFace 1000;
BA_ "InvalidValue" SG_ 286 CCUR_DuctActRearFace "null";
BA_ "GenSigStartValue" SG_ 286 CCUR_DuctActRearFoot 80;
BA_ "GenSigTimeoutTime_ALL" SG_ 286 CCUR_DuctActRearFoot 1000;
BA_ "InvalidValue" SG_ 286 CCUR_DuctActRearFoot "null";
BA_ "GenSigStartValue" SG_ 286 CCUR_EvaporatorTemp 80;
BA_ "GenSigTimeoutTime_ALL" SG_ 286 CCUR_EvaporatorTemp 1000;
BA_ "InvalidValue" SG_ 286 CCUR_EvaporatorTemp "null";
BA_ "GenSigStartValue" SG_ 286 CCUR_InteriorTemp 80;
BA_ "GenSigTimeoutTime_ALL" SG_ 286 CCUR_InteriorTemp 1000;
BA_ "InvalidValue" SG_ 286 CCUR_InteriorTemp "null";
BA_ "GenSigTimeoutTime_ALL" SG_ 286 CCUR_AirDistribFeedback_Rear 1000;
BA_ "InvalidValue" SG_ 286 CCUR_AirDistribFeedback_Rear "null";
BA_ "GenSigTimeoutTime_ALL" SG_ 286 CCUR_TempFeedback_Rear 1000;
BA_ "InvalidValue" SG_ 286 CCUR_TempFeedback_Rear "null";
BA_ "GenSigTimeoutTime_ALL" SG_ 286 CCUR_BlowerFeedback_Rear 1000;
BA_ "InvalidValue" SG_ 286 CCUR_BlowerFeedback_Rear "null";
BA_ "GenSigSendType" SG_ 287 MHU_DrvInhibitSts 2;
BA_ "InvalidValue" SG_ 287 MHU_DrvInhibitSts "0h";
BA_ "GenSigSendType" SG_ 287 TBOX_AuthCode_0x11F 2;
BA_ "InvalidValue" SG_ 287 TBOX_AuthCode_0x11F "null";
BA_ "GenSigTimeoutTime_ALL" SG_ 290 CHKSM_CCU_REQUEST 1000;
BA_ "InvalidValue" SG_ 290 CHKSM_CCU_REQUEST "null";
BA_ "GenSigTimeoutTime_ALL" SG_ 290 ALV_CCU_REQUEST 1000;
BA_ "InvalidValue" SG_ 290 ALV_CCU_REQUEST "Fh";
BA_ "GenSigTimeoutTime_ALL" SG_ 290 CCU_REQ_MaxCool 1000;
BA_ "InvalidValue" SG_ 290 CCU_REQ_MaxCool "3h";
BA_ "GenSigStartValue" SG_ 290 CCU_REQ_MaxHeat 3;
BA_ "GenSigTimeoutTime_ALL" SG_ 290 CCU_REQ_MaxHeat 1000;
BA_ "InvalidValue" SG_ 290 CCU_REQ_MaxHeat "3h";
BA_ "GenSigStartValue" SG_ 290 CCU_REQ_ESSMotorControl 7;
BA_ "GenSigTimeoutTime_ALL" SG_ 290 CCU_REQ_ESSMotorControl 1000;
BA_ "InvalidValue" SG_ 290 CCU_REQ_ESSMotorControl "7h";
BA_ "GenSigTimeoutTime_ALL" SG_ 290 CCU_AC_PWM 1000;
BA_ "InvalidValue" SG_ 290 CCU_AC_PWM "7Fh";
BA_ "GenSigSendType" SG_ 303 CHKSM_BCM_TERMINAL 3;
BA_ "GenSigTimeoutTime_ALL" SG_ 303 CHKSM_BCM_TERMINAL 500;
BA_ "InvalidValue" SG_ 303 CHKSM_BCM_TERMINAL "null";
BA_ "GenSigSendType" SG_ 303 ALV_BCM_TERMINAL 3;
BA_ "GenSigTimeoutTime_ALL" SG_ 303 ALV_BCM_TERMINAL 500;
BA_ "InvalidValue" SG_ 303 ALV_BCM_TERMINAL "Fh";
BA_ "GenSigSendType" SG_ 303 ST_KL 3;
BA_ "GenSigTimeoutTime_ALL" SG_ 303 ST_KL 500;
BA_ "InvalidValue" SG_ 303 ST_KL "Fh";
BA_ "GenSigSendType" SG_ 303 ST_KL_KEY_VLD 3;
BA_ "GenSigTimeoutTime_ALL" SG_ 303 ST_KL_KEY_VLD 500;
BA_ "InvalidValue" SG_ 303 ST_KL_KEY_VLD "Fh";
BA_ "GenSigTimeoutTime_ALL" SG_ 303 STAT_AlcoholEngineStatus 500;
BA_ "InvalidValue" SG_ 303 STAT_AlcoholEngineStatus "3h";
BA_ "GenSigSendType" SG_ 303 ST_STCD_PENG 3;
BA_ "GenSigTimeoutTime_ALL" SG_ 303 ST_STCD_PENG 500;
BA_ "InvalidValue" SG_ 303 ST_STCD_PENG "3h";
BA_ "GenSigSendType" SG_ 303 ST_SSB 3;
BA_ "GenSigTimeoutTime_ALL" SG_ 303 ST_SSB 500;
BA_ "InvalidValue" SG_ 303 ST_SSB "3h";
BA_ "GenSigSendType" SG_ 303 RWDT_BLS 3;
BA_ "GenSigTimeoutTime_ALL" SG_ 303 RWDT_BLS 500;
BA_ "InvalidValue" SG_ 303 RWDT_BLS "Fh";
BA_ "GenSigSendType" SG_ 303 RQ_DRVG_RDI 3;
BA_ "GenSigTimeoutTime_ALL" SG_ 303 RQ_DRVG_RDI 500;
BA_ "InvalidValue" SG_ 303 RQ_DRVG_RDI "3h";
BA_ "GenSigTimeoutTime_ALL" SG_ 303 STAT_AlcoholIgnStatus 500;
BA_ "InvalidValue" SG_ 303 STAT_AlcoholIgnStatus "3h";
BA_ "GenSigSendType" SG_ 303 CTR_ENG_STOP 3;
BA_ "GenSigTimeoutTime_ALL" SG_ 303 CTR_ENG_STOP 500;
BA_ "InvalidValue" SG_ 303 CTR_ENG_STOP "3h";
BA_ "GenSigSendType" SG_ 303 ST_VEH_CON 3;
BA_ "GenSigTimeoutTime_ALL" SG_ 303 ST_VEH_CON 500;
BA_ "InvalidValue" SG_ 303 ST_VEH_CON "Fh";
BA_ "GenSigSendType" SG_ 359 TWV1_N_Position 7;
BA_ "InvalidValue" SG_ 359 TWV1_N_Position "null";
BA_ "GenSigSendType" SG_ 359 TWV1_St_Feedback 7;
BA_ "InvalidValue" SG_ 359 TWV1_St_Feedback "null";
BA_ "GenSigSendType" SG_ 359 TWV1_Frm_Error 7;
BA_ "InvalidValue" SG_ 359 TWV1_Frm_Error "null";
BA_ "GenSigTimeoutTime_ALL" SG_ 376 CHKSM_YSS_LongAcc 100;
BA_ "InvalidValue" SG_ 376 CHKSM_YSS_LongAcc "null";
BA_ "GenSigTimeoutTime_ALL" SG_ 376 ALV_YSS_LongAcc 100;
BA_ "InvalidValue" SG_ 376 ALV_YSS_LongAcc "Fh";
BA_ "GenSigTimeoutTime_ALL" SG_ 376 YSS_LONG_ACCUNFILTERED_QUAL 100;
BA_ "GenSigTimeoutTime_ALL" SG_ 376 YSS_LONG_ACC_UNFILTERED 100;
BA_ "InvalidValue" SG_ 376 YSS_LONG_ACC_UNFILTERED "FFFh";
BA_ "GenSigTimeoutTime_ALL" SG_ 376 YSS_LONG_ACC_QUAL 100;
BA_ "GenSigTimeoutTime_ALL" SG_ 376 YSS_LONG_ACC 100;
BA_ "InvalidValue" SG_ 376 YSS_LONG_ACC "FFFFh";
BA_ "GenSigTimeoutTime_ALL" SG_ 381 CHKSM_YSS_YawRate 100;
BA_ "InvalidValue" SG_ 381 CHKSM_YSS_YawRate "null";
BA_ "GenSigTimeoutTime_ALL" SG_ 381 ALV_YSS_YawRate 100;
BA_ "InvalidValue" SG_ 381 ALV_YSS_YawRate "Fh";
BA_ "GenSigTimeoutTime_ALL" SG_ 381 YSS_YAW_RATEUNFILTERED_QUAL 100;
BA_ "GenSigTimeoutTime_ALL" SG_ 381 YSS_YAW_RATE_UNFILTERED 100;
BA_ "InvalidValue" SG_ 381 YSS_YAW_RATE_UNFILTERED "FFFh";
BA_ "GenSigTimeoutTime_ALL" SG_ 381 YSS_YAW_RATE_QUAL 100;
BA_ "GenSigTimeoutTime_ALL" SG_ 381 YSS_SC_STATUS 100;
BA_ "InvalidValue" SG_ 381 YSS_SC_STATUS "null";
BA_ "GenSigTimeoutTime_ALL" SG_ 381 YSS_YAW_RATE 100;
BA_ "InvalidValue" SG_ 381 YSS_YAW_RATE "FFFFh";
BA_ "GenSigStartValue" SG_ 381 YSS_TEMPERATURE 40;
BA_ "GenSigTimeoutTime_ALL" SG_ 381 YSS_TEMPERATURE 100;
BA_ "InvalidValue" SG_ 381 YSS_TEMPERATURE "FFh";
BA_ "GenSigTimeoutTime_ALL" SG_ 382 CHKSM_SAS_Sensor 200;
BA_ "InvalidValue" SG_ 382 CHKSM_SAS_Sensor "null";
BA_ "GenSigTimeoutTime_ALL" SG_ 382 ALV_SAS_Sensor 200;
BA_ "InvalidValue" SG_ 382 ALV_SAS_Sensor "Fh";
BA_ "GenSigTimeoutTime_ALL" SG_ 382 SAS_SASStsSnsr 200;
BA_ "InvalidValue" SG_ 382 SAS_SASStsSnsr "null";
BA_ "GenSigStartValue" SG_ 382 SAS_SteerWhlRotSpd 8192;
BA_ "GenSigTimeoutTime_ALL" SG_ 382 SAS_SteerWhlRotSpd 100;
BA_ "InvalidValue" SG_ 382 SAS_SteerWhlRotSpd "3FFFh";
BA_ "GenSigTimeoutTime_ALL" SG_ 382 SAS_SteerWhlRotSpdStatus 200;
BA_ "InvalidValue" SG_ 382 SAS_SteerWhlRotSpdStatus "null";
BA_ "GenSigTimeoutTime_ALL" SG_ 382 SAS_SASFailure 200;
BA_ "InvalidValue" SG_ 382 SAS_SASFailure "null";
BA_ "GenSigTimeoutTime_ALL" SG_ 382 SAS_Calibrated 100;
BA_ "InvalidValue" SG_ 382 SAS_Calibrated "null";
BA_ "GenSigTimeoutTime_ALL" SG_ 382 SAS_SteerWheelAngleValid 200;
BA_ "InvalidValue" SG_ 382 SAS_SteerWheelAngleValid "3h";
BA_ "GenSigTimeoutTime_ALL" SG_ 382 SAS_SteerWheelAngle 200;
BA_ "InvalidValue" SG_ 382 SAS_SteerWheelAngle "FFFFh";
BA_ "GenSigTimeoutTime_ALL" SG_ 385 CAM_CamSts 400;
BA_ "GenSigTimeoutTime_ALL" SG_ 385 CAM_AmbLi 400;
BA_ "GenSigTimeoutTime_ALL" SG_ 385 CAM_RoadIllmn 400;
BA_ "GenSigTimeoutTime_ALL" SG_ 385 CAM_Obj_TrfcStyle 400;
BA_ "GenSigTimeoutTime_ALL" SG_ 401 CAM_Obj1_ID 400;
BA_ "InvalidValue" SG_ 401 CAM_Obj1_ID "0";
BA_ "GenSigStartValue" SG_ 401 CAM_Obj1_HozlDst 511;
BA_ "GenSigTimeoutTime_ALL" SG_ 401 CAM_Obj1_HozlDst 400;
BA_ "InvalidValue" SG_ 401 CAM_Obj1_HozlDst "1FFh";
BA_ "GenSigTimeoutTime_ALL" SG_ 401 CAM_Obj1_Valid 400;
BA_ "InvalidValue" SG_ 401 CAM_Obj1_Valid "0";
BA_ "GenSigStartValue" SG_ 401 CAM_Obj1_HozlPosnRi 500;
BA_ "GenSigTimeoutTime_ALL" SG_ 401 CAM_Obj1_HozlPosnRi 400;
BA_ "InvalidValue" SG_ 401 CAM_Obj1_HozlPosnRi "3FFh";
BA_ "GenSigTimeoutTime_ALL" SG_ 401 CAM_Obj1_Typ 400;
BA_ "InvalidValue" SG_ 401 CAM_Obj1_Typ "0";
BA_ "GenSigStartValue" SG_ 401 CAM_Obj1_HozlPosnLe 500;
BA_ "GenSigTimeoutTime_ALL" SG_ 401 CAM_Obj1_HozlPosnLe 400;
BA_ "InvalidValue" SG_ 401 CAM_Obj1_HozlPosnLe "3FFh";
BA_ "GenSigStartValue" SG_ 401 CAM_Obj1_VertPosn 120;
BA_ "GenSigTimeoutTime_ALL" SG_ 401 CAM_Obj1_VertPosn 400;
BA_ "GenSigStartValue" SG_ 401 CAM_Obj1_HozlSpdLe 128;
BA_ "GenSigTimeoutTime_ALL" SG_ 401 CAM_Obj1_HozlSpdLe 400;
BA_ "InvalidValue" SG_ 401 CAM_Obj1_HozlSpdLe "null";
BA_ "GenSigStartValue" SG_ 401 CAM_Obj1_HozlSpdRi 128;
BA_ "GenSigTimeoutTime_ALL" SG_ 401 CAM_Obj1_HozlSpdRi 400;
BA_ "InvalidValue" SG_ 401 CAM_Obj1_HozlSpdRi "null";
BA_ "GenSigTimeoutTime_ALL" SG_ 404 CAM_Obj2_ID 400;
BA_ "InvalidValue" SG_ 404 CAM_Obj2_ID "0";
BA_ "GenSigStartValue" SG_ 404 CAM_Obj2_HozlDst 511;
BA_ "GenSigTimeoutTime_ALL" SG_ 404 CAM_Obj2_HozlDst 400;
BA_ "InvalidValue" SG_ 404 CAM_Obj2_HozlDst "1FFh";
BA_ "GenSigTimeoutTime_ALL" SG_ 404 CAM_Obj2_Valid 400;
BA_ "InvalidValue" SG_ 404 CAM_Obj2_Valid "0";
BA_ "GenSigStartValue" SG_ 404 CAM_Obj2_HozlPosnRi 500;
BA_ "GenSigTimeoutTime_ALL" SG_ 404 CAM_Obj2_HozlPosnRi 400;
BA_ "InvalidValue" SG_ 404 CAM_Obj2_HozlPosnRi "3FFh";
BA_ "GenSigTimeoutTime_ALL" SG_ 404 CAM_Obj2_Typ 400;
BA_ "InvalidValue" SG_ 404 CAM_Obj2_Typ "0";
BA_ "GenSigStartValue" SG_ 404 CAM_Obj2_HozlPosnLe 500;
BA_ "GenSigTimeoutTime_ALL" SG_ 404 CAM_Obj2_HozlPosnLe 400;
BA_ "InvalidValue" SG_ 404 CAM_Obj2_HozlPosnLe "3FFh";
BA_ "GenSigStartValue" SG_ 404 CAM_Obj2_VertPosn 120;
BA_ "GenSigTimeoutTime_ALL" SG_ 404 CAM_Obj2_VertPosn 400;
BA_ "GenSigStartValue" SG_ 404 CAM_Obj2_HozlSpdLe 128;
BA_ "GenSigTimeoutTime_ALL" SG_ 404 CAM_Obj2_HozlSpdLe 400;
BA_ "InvalidValue" SG_ 404 CAM_Obj2_HozlSpdLe "null";
BA_ "GenSigStartValue" SG_ 404 CAM_Obj2_HozlSpdRi 128;
BA_ "GenSigTimeoutTime_ALL" SG_ 404 CAM_Obj2_HozlSpdRi 400;
BA_ "InvalidValue" SG_ 404 CAM_Obj2_HozlSpdRi "null";
BA_ "GenSigTimeoutTime_ALL" SG_ 406 CAM_Obj3_ID 400;
BA_ "InvalidValue" SG_ 406 CAM_Obj3_ID "0";
BA_ "GenSigStartValue" SG_ 406 CAM_Obj3_HozlDst 511;
BA_ "GenSigTimeoutTime_ALL" SG_ 406 CAM_Obj3_HozlDst 400;
BA_ "InvalidValue" SG_ 406 CAM_Obj3_HozlDst "1FFh";
BA_ "GenSigTimeoutTime_ALL" SG_ 406 CAM_Obj3_Valid 400;
BA_ "InvalidValue" SG_ 406 CAM_Obj3_Valid "0";
BA_ "GenSigStartValue" SG_ 406 CAM_Obj3_HozlPosnRi 500;
BA_ "GenSigTimeoutTime_ALL" SG_ 406 CAM_Obj3_HozlPosnRi 400;
BA_ "InvalidValue" SG_ 406 CAM_Obj3_HozlPosnRi "3FFh";
BA_ "GenSigTimeoutTime_ALL" SG_ 406 CAM_Obj3_Typ 400;
BA_ "InvalidValue" SG_ 406 CAM_Obj3_Typ "0";
BA_ "GenSigStartValue" SG_ 406 CAM_Obj3_HozlPosnLe 500;
BA_ "GenSigTimeoutTime_ALL" SG_ 406 CAM_Obj3_HozlPosnLe 400;
BA_ "InvalidValue" SG_ 406 CAM_Obj3_HozlPosnLe "3FFh";
BA_ "GenSigStartValue" SG_ 406 CAM_Obj3_VertPosn 120;
BA_ "GenSigTimeoutTime_ALL" SG_ 406 CAM_Obj3_VertPosn 400;
BA_ "GenSigStartValue" SG_ 406 CAM_Obj3_HozlSpdLe 128;
BA_ "GenSigTimeoutTime_ALL" SG_ 406 CAM_Obj3_HozlSpdLe 400;
BA_ "InvalidValue" SG_ 406 CAM_Obj3_HozlSpdLe "null";
BA_ "GenSigStartValue" SG_ 406 CAM_Obj3_HozlSpdRi 128;
BA_ "GenSigTimeoutTime_ALL" SG_ 406 CAM_Obj3_HozlSpdRi 400;
BA_ "InvalidValue" SG_ 406 CAM_Obj3_HozlSpdRi "null";
BA_ "GenSigTimeoutTime_ALL" SG_ 410 CAM_Obj4_ID 400;
BA_ "InvalidValue" SG_ 410 CAM_Obj4_ID "0";
BA_ "GenSigStartValue" SG_ 410 CAM_Obj4_HozlDst 511;
BA_ "GenSigTimeoutTime_ALL" SG_ 410 CAM_Obj4_HozlDst 400;
BA_ "InvalidValue" SG_ 410 CAM_Obj4_HozlDst "1FFh";
BA_ "GenSigTimeoutTime_ALL" SG_ 410 CAM_Obj4_Valid 400;
BA_ "InvalidValue" SG_ 410 CAM_Obj4_Valid "0";
BA_ "GenSigStartValue" SG_ 410 CAM_Obj4_HozlPosnRi 500;
BA_ "GenSigTimeoutTime_ALL" SG_ 410 CAM_Obj4_HozlPosnRi 400;
BA_ "InvalidValue" SG_ 410 CAM_Obj4_HozlPosnRi "3FFh";
BA_ "GenSigTimeoutTime_ALL" SG_ 410 CAM_Obj4_Typ 400;
BA_ "InvalidValue" SG_ 410 CAM_Obj4_Typ "0";
BA_ "GenSigStartValue" SG_ 410 CAM_Obj4_HozlPosnLe 500;
BA_ "GenSigTimeoutTime_ALL" SG_ 410 CAM_Obj4_HozlPosnLe 400;
BA_ "InvalidValue" SG_ 410 CAM_Obj4_HozlPosnLe "3FFh";
BA_ "GenSigStartValue" SG_ 410 CAM_Obj4_VertPosn 120;
BA_ "GenSigTimeoutTime_ALL" SG_ 410 CAM_Obj4_VertPosn 400;
BA_ "GenSigStartValue" SG_ 410 CAM_Obj4_HozlSpdLe 128;
BA_ "GenSigTimeoutTime_ALL" SG_ 410 CAM_Obj4_HozlSpdLe 400;
BA_ "InvalidValue" SG_ 410 CAM_Obj4_HozlSpdLe "null";
BA_ "GenSigStartValue" SG_ 410 CAM_Obj4_HozlSpdRi 128;
BA_ "GenSigTimeoutTime_ALL" SG_ 410 CAM_Obj4_HozlSpdRi 400;
BA_ "InvalidValue" SG_ 410 CAM_Obj4_HozlSpdRi "null";
BA_ "GenSigTimeoutTime_ALL" SG_ 412 CAM_Obj5_ID 400;
BA_ "InvalidValue" SG_ 412 CAM_Obj5_ID "0";
BA_ "GenSigStartValue" SG_ 412 CAM_Obj5_HozlDst 511;
BA_ "GenSigTimeoutTime_ALL" SG_ 412 CAM_Obj5_HozlDst 400;
BA_ "InvalidValue" SG_ 412 CAM_Obj5_HozlDst "1FFh";
BA_ "GenSigTimeoutTime_ALL" SG_ 412 CAM_Obj5_Valid 400;
BA_ "InvalidValue" SG_ 412 CAM_Obj5_Valid "0";
BA_ "GenSigStartValue" SG_ 412 CAM_Obj5_HozlPosnRi 500;
BA_ "GenSigTimeoutTime_ALL" SG_ 412 CAM_Obj5_HozlPosnRi 400;
BA_ "InvalidValue" SG_ 412 CAM_Obj5_HozlPosnRi "3FFh";
BA_ "GenSigTimeoutTime_ALL" SG_ 412 CAM_Obj5_Typ 400;
BA_ "InvalidValue" SG_ 412 CAM_Obj5_Typ "0";
BA_ "GenSigStartValue" SG_ 412 CAM_Obj5_HozlPosnLe 500;
BA_ "GenSigTimeoutTime_ALL" SG_ 412 CAM_Obj5_HozlPosnLe 400;
BA_ "InvalidValue" SG_ 412 CAM_Obj5_HozlPosnLe "3FFh";
BA_ "GenSigStartValue" SG_ 412 CAM_Obj5_VertPosn 120;
BA_ "GenSigTimeoutTime_ALL" SG_ 412 CAM_Obj5_VertPosn 400;
BA_ "GenSigStartValue" SG_ 412 CAM_Obj5_HozlSpdLe 128;
BA_ "GenSigTimeoutTime_ALL" SG_ 412 CAM_Obj5_HozlSpdLe 400;
BA_ "InvalidValue" SG_ 412 CAM_Obj5_HozlSpdLe "null";
BA_ "GenSigStartValue" SG_ 412 CAM_Obj5_HozlSpdRi 128;
BA_ "GenSigTimeoutTime_ALL" SG_ 412 CAM_Obj5_HozlSpdRi 400;
BA_ "InvalidValue" SG_ 412 CAM_Obj5_HozlSpdRi "null";
BA_ "GenSigTimeoutTime_ALL" SG_ 413 CAM_Obj6_ID 400;
BA_ "InvalidValue" SG_ 413 CAM_Obj6_ID "0";
BA_ "GenSigStartValue" SG_ 413 CAM_Obj6_HozlDst 511;
BA_ "GenSigTimeoutTime_ALL" SG_ 413 CAM_Obj6_HozlDst 400;
BA_ "InvalidValue" SG_ 413 CAM_Obj6_HozlDst "1FFh";
BA_ "GenSigTimeoutTime_ALL" SG_ 413 CAM_Obj6_Valid 400;
BA_ "InvalidValue" SG_ 413 CAM_Obj6_Valid "0";
BA_ "GenSigStartValue" SG_ 413 CAM_Obj6_HozlPosnRi 500;
BA_ "GenSigTimeoutTime_ALL" SG_ 413 CAM_Obj6_HozlPosnRi 400;
BA_ "InvalidValue" SG_ 413 CAM_Obj6_HozlPosnRi "3FFh";
BA_ "GenSigTimeoutTime_ALL" SG_ 413 CAM_Obj6_Typ 400;
BA_ "InvalidValue" SG_ 413 CAM_Obj6_Typ "0";
BA_ "GenSigStartValue" SG_ 413 CAM_Obj6_HozlPosnLe 500;
BA_ "GenSigTimeoutTime_ALL" SG_ 413 CAM_Obj6_HozlPosnLe 400;
BA_ "InvalidValue" SG_ 413 CAM_Obj6_HozlPosnLe "3FFh";
BA_ "GenSigStartValue" SG_ 413 CAM_Obj6_VertPosn 120;
BA_ "GenSigTimeoutTime_ALL" SG_ 413 CAM_Obj6_VertPosn 400;
BA_ "GenSigStartValue" SG_ 413 CAM_Obj6_HozlSpdLe 128;
BA_ "GenSigTimeoutTime_ALL" SG_ 413 CAM_Obj6_HozlSpdLe 400;
BA_ "InvalidValue" SG_ 413 CAM_Obj6_HozlSpdLe "null";
BA_ "GenSigStartValue" SG_ 413 CAM_Obj6_HozlSpdRi 128;
BA_ "GenSigTimeoutTime_ALL" SG_ 413 CAM_Obj6_HozlSpdRi 400;
BA_ "InvalidValue" SG_ 413 CAM_Obj6_HozlSpdRi "null";
BA_ "GenSigTimeoutTime_ALL" SG_ 414 CAM_Obj7_ID 400;
BA_ "InvalidValue" SG_ 414 CAM_Obj7_ID "0";
BA_ "GenSigStartValue" SG_ 414 CAM_Obj7_HozlDst 511;
BA_ "GenSigTimeoutTime_ALL" SG_ 414 CAM_Obj7_HozlDst 400;
BA_ "InvalidValue" SG_ 414 CAM_Obj7_HozlDst "1FFh";
BA_ "GenSigTimeoutTime_ALL" SG_ 414 CAM_Obj7_Valid 400;
BA_ "InvalidValue" SG_ 414 CAM_Obj7_Valid "0";
BA_ "GenSigStartValue" SG_ 414 CAM_Obj7_HozlPosnRi 500;
BA_ "GenSigTimeoutTime_ALL" SG_ 414 CAM_Obj7_HozlPosnRi 400;
BA_ "InvalidValue" SG_ 414 CAM_Obj7_HozlPosnRi "3FFh";
BA_ "GenSigTimeoutTime_ALL" SG_ 414 CAM_Obj7_Typ 400;
BA_ "InvalidValue" SG_ 414 CAM_Obj7_Typ "0";
BA_ "GenSigStartValue" SG_ 414 CAM_Obj7_HozlPosnLe 500;
BA_ "GenSigTimeoutTime_ALL" SG_ 414 CAM_Obj7_HozlPosnLe 400;
BA_ "InvalidValue" SG_ 414 CAM_Obj7_HozlPosnLe "3FFh";
BA_ "GenSigStartValue" SG_ 414 CAM_Obj7_VertPosn 120;
BA_ "GenSigTimeoutTime_ALL" SG_ 414 CAM_Obj7_VertPosn 400;
BA_ "GenSigStartValue" SG_ 414 CAM_Obj7_HozlSpdLe 128;
BA_ "GenSigTimeoutTime_ALL" SG_ 414 CAM_Obj7_HozlSpdLe 400;
BA_ "InvalidValue" SG_ 414 CAM_Obj7_HozlSpdLe "null";
BA_ "GenSigStartValue" SG_ 414 CAM_Obj7_HozlSpdRi 128;
BA_ "GenSigTimeoutTime_ALL" SG_ 414 CAM_Obj7_HozlSpdRi 400;
BA_ "InvalidValue" SG_ 414 CAM_Obj7_HozlSpdRi "null";
BA_ "GenSigTimeoutTime_ALL" SG_ 415 CAM_Obj8_ID 400;
BA_ "InvalidValue" SG_ 415 CAM_Obj8_ID "0";
BA_ "GenSigStartValue" SG_ 415 CAM_Obj8_HozlDst 511;
BA_ "GenSigTimeoutTime_ALL" SG_ 415 CAM_Obj8_HozlDst 400;
BA_ "InvalidValue" SG_ 415 CAM_Obj8_HozlDst "1FFh";
BA_ "GenSigTimeoutTime_ALL" SG_ 415 CAM_Obj8_Valid 400;
BA_ "InvalidValue" SG_ 415 CAM_Obj8_Valid "0";
BA_ "GenSigStartValue" SG_ 415 CAM_Obj8_HozlPosnRi 500;
BA_ "GenSigTimeoutTime_ALL" SG_ 415 CAM_Obj8_HozlPosnRi 400;
BA_ "InvalidValue" SG_ 415 CAM_Obj8_HozlPosnRi "3FFh";
BA_ "GenSigTimeoutTime_ALL" SG_ 415 CAM_Obj8_Typ 400;
BA_ "InvalidValue" SG_ 415 CAM_Obj8_Typ "0";
BA_ "GenSigStartValue" SG_ 415 CAM_Obj8_HozlPosnLe 500;
BA_ "GenSigTimeoutTime_ALL" SG_ 415 CAM_Obj8_HozlPosnLe 400;
BA_ "InvalidValue" SG_ 415 CAM_Obj8_HozlPosnLe "3FFh";
BA_ "GenSigStartValue" SG_ 415 CAM_Obj8_VertPosn 120;
BA_ "GenSigTimeoutTime_ALL" SG_ 415 CAM_Obj8_VertPosn 400;
BA_ "GenSigStartValue" SG_ 415 CAM_Obj8_HozlSpdLe 128;
BA_ "GenSigTimeoutTime_ALL" SG_ 415 CAM_Obj8_HozlSpdLe 400;
BA_ "InvalidValue" SG_ 415 CAM_Obj8_HozlSpdLe "null";
BA_ "GenSigStartValue" SG_ 415 CAM_Obj8_HozlSpdRi 128;
BA_ "GenSigTimeoutTime_ALL" SG_ 415 CAM_Obj8_HozlSpdRi 400;
BA_ "InvalidValue" SG_ 415 CAM_Obj8_HozlSpdRi "null";
BA_ "GenSigTimeoutTime_ALL" SG_ 417 CHSKM_V_VEH 200;
BA_ "InvalidValue" SG_ 417 CHSKM_V_VEH "null";
BA_ "GenSigTimeoutTime_ALL" SG_ 417 ALIV_V_VEH 200;
BA_ "InvalidValue" SG_ 417 ALIV_V_VEH "Fh";
BA_ "GenSigTimeoutTime_ALL" SG_ 417 V_VEH_COG 200;
BA_ "InvalidValue" SG_ 417 V_VEH_COG "FFFFh";
BA_ "GenSigTimeoutTime_ALL" SG_ 417 DVCO_VEH 200;
BA_ "InvalidValue" SG_ 417 DVCO_VEH "7h";
BA_ "GenSigStartValue" SG_ 417 QU_V_VEH_COG 8;
BA_ "GenSigTimeoutTime_ALL" SG_ 417 QU_V_VEH_COG 200;
BA_ "InvalidValue" SG_ 417 QU_V_VEH_COG "Fh";
BA_ "GenSigTimeoutTime_ALL" SG_ 504 CHKSM_EDS_OutPut_FR 400;
BA_ "InvalidValue" SG_ 504 CHKSM_EDS_OutPut_FR "null";
BA_ "GenSigTimeoutTime_ALL" SG_ 504 ALV_EDS_OutPut_FR 400;
BA_ "InvalidValue" SG_ 504 ALV_EDS_OutPut_FR "Fh";
BA_ "GenSigTimeoutTime_ALL" SG_ 504 EDS_Work_STS_FR 200;
BA_ "InvalidValue" SG_ 504 EDS_Work_STS_FR "Fh";
BA_ "GenSigStartValue" SG_ 504 EDS_Spd_FR 20000;
BA_ "GenSigTimeoutTime_ALL" SG_ 504 EDS_Spd_FR 400;
BA_ "InvalidValue" SG_ 504 EDS_Spd_FR "FFFFh";
BA_ "GenSigTimeoutTime_ALL" SG_ 504 EDS_output_trqValid_FR 200;
BA_ "InvalidValue" SG_ 504 EDS_output_trqValid_FR "null";
BA_ "GenSigTimeoutTime_ALL" SG_ 504 EDS_MotorDriveSts_FR 400;
BA_ "InvalidValue" SG_ 504 EDS_MotorDriveSts_FR "3h";
BA_ "GenSigTimeoutTime_ALL" SG_ 504 EDS_powoff_req_FR 200;
BA_ "InvalidValue" SG_ 504 EDS_powoff_req_FR "null";
BA_ "GenSigTimeoutTime_ALL" SG_ 504 EDS_SpdValid_FR 200;
BA_ "InvalidValue" SG_ 504 EDS_SpdValid_FR "null";
BA_ "GenSigStartValue" SG_ 504 EDS_output_trq_FR 2000;
BA_ "GenSigTimeoutTime_ALL" SG_ 504 EDS_output_trq_FR 200;
BA_ "InvalidValue" SG_ 504 EDS_output_trq_FR "FFFFh";
BA_ "GenSigTimeoutTime_ALL" SG_ 504 EDS_VCU_6SO_flag_FWD 400;
BA_ "InvalidValue" SG_ 504 EDS_VCU_6SO_flag_FWD "null";
BA_ "GenSigTimeoutTime_ALL" SG_ 505 CHKSM_EDS_OutPut_RR 400;
BA_ "InvalidValue" SG_ 505 CHKSM_EDS_OutPut_RR "null";
BA_ "GenSigTimeoutTime_ALL" SG_ 505 ALV_EDS_OutPut_RR 400;
BA_ "InvalidValue" SG_ 505 ALV_EDS_OutPut_RR "Fh";
BA_ "GenSigTimeoutTime_ALL" SG_ 505 EDS_Work_STS_RR 400;
BA_ "InvalidValue" SG_ 505 EDS_Work_STS_RR "Fh";
BA_ "GenSigStartValue" SG_ 505 EDS_Spd_RR 20000;
BA_ "GenSigTimeoutTime_ALL" SG_ 505 EDS_Spd_RR 400;
BA_ "InvalidValue" SG_ 505 EDS_Spd_RR "FFFFh";
BA_ "GenSigTimeoutTime_ALL" SG_ 505 EDS_output_trqValid_RR 400;
BA_ "InvalidValue" SG_ 505 EDS_output_trqValid_RR "null";
BA_ "GenSigTimeoutTime_ALL" SG_ 505 EDS_MotorDriveSts_RR 400;
BA_ "InvalidValue" SG_ 505 EDS_MotorDriveSts_RR "3h";
BA_ "GenSigTimeoutTime_ALL" SG_ 505 EDS_powoff_req_RR 400;
BA_ "InvalidValue" SG_ 505 EDS_powoff_req_RR "null";
BA_ "GenSigTimeoutTime_ALL" SG_ 505 EDS_SpdValid_RR 200;
BA_ "InvalidValue" SG_ 505 EDS_SpdValid_RR "null";
BA_ "GenSigStartValue" SG_ 505 EDS_output_trq_RR 2000;
BA_ "GenSigTimeoutTime_ALL" SG_ 505 EDS_output_trq_RR 200;
BA_ "InvalidValue" SG_ 505 EDS_output_trq_RR "FFFFh";
BA_ "GenSigTimeoutTime_ALL" SG_ 505 EDS_VCU_6SO_flag_RWD 400;
BA_ "InvalidValue" SG_ 505 EDS_VCU_6SO_flag_RWD "null";
BA_ "GenSigTimeoutTime_ALL" SG_ 519 SR_Undervoltage_Fault_Sts 500;
BA_ "InvalidValue" SG_ 519 SR_Undervoltage_Fault_Sts "null";
BA_ "GenSigTimeoutTime_ALL" SG_ 519 SR_Overvoltage_Fault_Sts 500;
BA_ "InvalidValue" SG_ 519 SR_Overvoltage_Fault_Sts "null";
BA_ "GenSigTimeoutTime_ALL" SG_ 519 SR_SLEEP_RQ 500;
BA_ "InvalidValue" SG_ 519 SR_SLEEP_RQ "null";
BA_ "GenSigTimeoutTime_ALL" SG_ 519 SR_Position 500;
BA_ "InvalidValue" SG_ 519 SR_Position "null";
BA_ "GenSigTimeoutTime_ALL" SG_ 519 SR_Motor_Running_Sts 500;
BA_ "InvalidValue" SG_ 519 SR_Motor_Running_Sts "null";
BA_ "GenSigTimeoutTime_ALL" SG_ 519 SR_MotorReverse_Fault_Sts 500;
BA_ "InvalidValue" SG_ 519 SR_MotorReverse_Fault_Sts "null";
BA_ "GenSigTimeoutTime_ALL" SG_ 519 SR_Hall_Fault_Sts 500;
BA_ "InvalidValue" SG_ 519 SR_Hall_Fault_Sts "null";
BA_ "GenSigTimeoutTime_ALL" SG_ 519 SR_Normalisation_Sts 500;
BA_ "InvalidValue" SG_ 519 SR_Normalisation_Sts "null";
BA_ "GenSigTimeoutTime_ALL" SG_ 519 SR_Relay_Fault 500;
BA_ "InvalidValue" SG_ 519 SR_Relay_Fault "null";
BA_ "GenSigTimeoutTime_ALL" SG_ 519 SR_Commu_Fault_Sts 500;
BA_ "InvalidValue" SG_ 519 SR_Commu_Fault_Sts "null";
BA_ "GenSigTimeoutTime_ALL" SG_ 519 SR_Initialisation_Status 500;
BA_ "InvalidValue" SG_ 519 SR_Initialisation_Status "null";
BA_ "GenSigTimeoutTime_ALL" SG_ 519 SR_Ctrl_Result 500;
BA_ "InvalidValue" SG_ 519 SR_Ctrl_Result "null";
BA_ "GenSigTimeoutTime_ALL" SG_ 519 SR_ThermalProtection_Fault_Sts 500;
BA_ "InvalidValue" SG_ 519 SR_ThermalProtection_Fault_Sts "null";
BA_ "GenSigTimeoutTime_ALL" SG_ 519 SR_Posit_Percentage 500;
BA_ "InvalidValue" SG_ 519 SR_Posit_Percentage "7Fh";
BA_ "GenSigTimeoutTime_ALL" SG_ 519 SR_Operation_Stat 500;
BA_ "InvalidValue" SG_ 519 SR_Operation_Stat "null";
BA_ "GenSigTimeoutTime_ALL" SG_ 519 SR_Error_RSP 500;
BA_ "InvalidValue" SG_ 519 SR_Error_RSP "null";
BA_ "GenSigTimeoutTime_ALL" SG_ 519 BCM_AutoSunroof_Sts 500;
BA_ "GenSigStartValue" SG_ 519 BCM_AutoSunroof_Sts 2;
BA_ "InvalidValue" SG_ 519 BCM_AutoSunroof_Sts "3h";
BA_ "GenSigTimeoutTime_ALL" SG_ 520 SS_MotorReverse_Fault_Status 500;
BA_ "InvalidValue" SG_ 520 SS_MotorReverse_Fault_Status "null";
BA_ "GenSigTimeoutTime_ALL" SG_ 520 SS_Motor_Running_Status 500;
BA_ "InvalidValue" SG_ 520 SS_Motor_Running_Status "null";
BA_ "GenSigTimeoutTime_ALL" SG_ 520 SS_Position 500;
BA_ "InvalidValue" SG_ 520 SS_Position "null";
BA_ "GenSigTimeoutTime_ALL" SG_ 520 SS_SLEEP_RQ 500;
BA_ "InvalidValue" SG_ 520 SS_SLEEP_RQ "null";
BA_ "GenSigTimeoutTime_ALL" SG_ 520 SS_Undervoltage_Fault_Status 500;
BA_ "InvalidValue" SG_ 520 SS_Undervoltage_Fault_Status "null";
BA_ "GenSigTimeoutTime_ALL" SG_ 520 SS_Ctrl_Result 500;
BA_ "InvalidValue" SG_ 520 SS_Ctrl_Result "null";
BA_ "GenSigTimeoutTime_ALL" SG_ 520 SS_Overvoltage_Fault_Status 500;
BA_ "InvalidValue" SG_ 520 SS_Overvoltage_Fault_Status "null";
BA_ "GenSigTimeoutTime_ALL" SG_ 520 SS_Relay_Fault 500;
BA_ "InvalidValue" SG_ 520 SS_Relay_Fault "null";
BA_ "GenSigTimeoutTime_ALL" SG_ 520 SS_Normalisation_Status 500;
BA_ "InvalidValue" SG_ 520 SS_Normalisation_Status "null";
BA_ "GenSigTimeoutTime_ALL" SG_ 520 SS_Hall_Fault_Status 500;
BA_ "InvalidValue" SG_ 520 SS_Hall_Fault_Status "null";
BA_ "GenSigTimeoutTime_ALL" SG_ 520 SS_Commu_Fault_Status 500;
BA_ "InvalidValue" SG_ 520 SS_Commu_Fault_Status "null";
BA_ "GenSigTimeoutTime_ALL" SG_ 520 SS_Initialisation_Status 500;
BA_ "InvalidValue" SG_ 520 SS_Initialisation_Status "null";
BA_ "GenSigTimeoutTime_ALL" SG_ 520 SS_Posit_Percentage 500;
BA_ "InvalidValue" SG_ 520 SS_Posit_Percentage "7Fh";
BA_ "GenSigTimeoutTime_ALL" SG_ 520 SS_ThermalProtection_Flt_Sts 500;
BA_ "InvalidValue" SG_ 520 SS_ThermalProtection_Flt_Sts "null";
BA_ "GenSigTimeoutTime_ALL" SG_ 520 SS_Operation_State 500;
BA_ "InvalidValue" SG_ 520 SS_Operation_State "null";
BA_ "GenSigTimeoutTime_ALL" SG_ 520 SECCAN_SunshadeSts 500;
BA_ "InvalidValue" SG_ 520 SECCAN_SunshadeSts "null";
BA_ "GenSigTimeoutTime_ALL" SG_ 520 SS_Error_RSP 500;
BA_ "InvalidValue" SG_ 520 SS_Error_RSP "null";
BA_ "GenSigStartValue" SG_ 522 ETG_Lift_Gate_Status 7;
BA_ "GenSigTimeoutTime_ALL" SG_ 522 ETG_Lift_Gate_Status 500;
BA_ "InvalidValue" SG_ 522 ETG_Lift_Gate_Status "7h";
BA_ "GenSigStartValue" SG_ 522 ETG_Power_Latch_Status 7;
BA_ "GenSigTimeoutTime_ALL" SG_ 522 ETG_Power_Latch_Status 500;
BA_ "InvalidValue" SG_ 522 ETG_Power_Latch_Status "7h";
BA_ "GenSigStartValue" SG_ 522 ETG_Latch_Segment 3;
BA_ "GenSigTimeoutTime_ALL" SG_ 522 ETG_Latch_Segment 500;
BA_ "InvalidValue" SG_ 522 ETG_Latch_Segment "3h";
BA_ "GenSigTimeoutTime_ALL" SG_ 522 ETG_Opening_Percentage 500;
BA_ "InvalidValue" SG_ 522 ETG_Opening_Percentage "FFh";
BA_ "GenSigTimeoutTime_ALL" SG_ 522 ETG_DSW_Status 500;
BA_ "InvalidValue" SG_ 522 ETG_DSW_Status "null";
BA_ "GenSigTimeoutTime_ALL" SG_ 522 ETG_GSW_Status 500;
BA_ "InvalidValue" SG_ 522 ETG_GSW_Status "null";
BA_ "GenSigTimeoutTime_ALL" SG_ 522 ETG_LTS_Status 500;
BA_ "InvalidValue" SG_ 522 ETG_LTS_Status "null";
BA_ "GenSigTimeoutTime_ALL" SG_ 522 ETG_RTS_Status 500;
BA_ "InvalidValue" SG_ 522 ETG_RTS_Status "null";
BA_ "GenSigTimeoutTime_ALL" SG_ 522 ETG_HAL_Status 500;
BA_ "InvalidValue" SG_ 522 ETG_HAL_Status "null";
BA_ "GenSigTimeoutTime_ALL" SG_ 522 ETG_FUL_Status 500;
BA_ "InvalidValue" SG_ 522 ETG_FUL_Status "null";
BA_ "GenSigTimeoutTime_ALL" SG_ 522 ETG_AJR_Status 500;
BA_ "InvalidValue" SG_ 522 ETG_AJR_Status "null";
BA_ "GenSigTimeoutTime_ALL" SG_ 522 ETG_NTL_Status 500;
BA_ "InvalidValue" SG_ 522 ETG_NTL_Status "null";
BA_ "GenSigTimeoutTime_ALL" SG_ 522 ETG_ERR_Voltage 500;
BA_ "InvalidValue" SG_ 522 ETG_ERR_Voltage "null";
BA_ "GenSigTimeoutTime_ALL" SG_ 522 ETG_ERR_Left_Motor 500;
BA_ "InvalidValue" SG_ 522 ETG_ERR_Left_Motor "null";
BA_ "GenSigTimeoutTime_ALL" SG_ 522 ETG_ERR_Right_Motor 500;
BA_ "InvalidValue" SG_ 522 ETG_ERR_Right_Motor "null";
BA_ "GenSigTimeoutTime_ALL" SG_ 522 ETG_ERR_Latch 500;
BA_ "InvalidValue" SG_ 522 ETG_ERR_Latch "null";
BA_ "GenSigTimeoutTime_ALL" SG_ 522 ETG_ERR_Hall 500;
BA_ "InvalidValue" SG_ 522 ETG_ERR_Hall "null";
BA_ "GenSigTimeoutTime_ALL" SG_ 522 ETG_Lift_Motor_Stall 500;
BA_ "InvalidValue" SG_ 522 ETG_Lift_Motor_Stall "null";
BA_ "GenSigTimeoutTime_ALL" SG_ 522 ETG_Lift_Motor_AntiPinch 500;
BA_ "InvalidValue" SG_ 522 ETG_Lift_Motor_AntiPinch "null";
BA_ "GenSigTimeoutTime_ALL" SG_ 522 ETG_Lift_Motor_Thermal 500;
BA_ "InvalidValue" SG_ 522 ETG_Lift_Motor_Thermal "null";
BA_ "GenSigTimeoutTime_ALL" SG_ 522 ETG_Power_Latch_Thermal 500;
BA_ "InvalidValue" SG_ 522 ETG_Power_Latch_Thermal "null";
BA_ "GenSigTimeoutTime_ALL" SG_ 522 ETG_Abuse_Protection 500;
BA_ "InvalidValue" SG_ 522 ETG_Abuse_Protection "null";
BA_ "GenSigTimeoutTime_ALL" SG_ 523 FKS_RespError 500;
BA_ "InvalidValue" SG_ 523 FKS_RespError "null";
BA_ "GenSigTimeoutTime_ALL" SG_ 523 FKS_OpenReq 500;
BA_ "InvalidValue" SG_ 523 FKS_OpenReq "null";
BA_ "GenSigTimeoutTime_ALL" SG_ 523 FKS_HWError 500;
BA_ "InvalidValue" SG_ 523 FKS_HWError "null";
BA_ "GenSigTimeoutTime_ALL" SG_ 523 FKS_AntennaError 500;
BA_ "InvalidValue" SG_ 523 FKS_AntennaError "null";
BA_ "GenSigTimeoutTime_ALL" SG_ 523 FKS_OverVolDected 500;
BA_ "InvalidValue" SG_ 523 FKS_OverVolDected "null";
BA_ "GenSigTimeoutTime_ALL" SG_ 523 FKS_UnderVolDected 500;
BA_ "InvalidValue" SG_ 523 FKS_UnderVolDected "null";
BA_ "GenSigTimeoutTime_ALL" SG_ 523 FKS_activate_deactivate 500;
BA_ "InvalidValue" SG_ 523 FKS_activate_deactivate "null";
BA_ "GenSigTimeoutTime_ALL" SG_ 524 CHKSM_IC_ODO 500;
BA_ "InvalidValue" SG_ 524 CHKSM_IC_ODO "null";
BA_ "GenSigTimeoutTime_ALL" SG_ 524 ALIV_IC_ODO 500;
BA_ "InvalidValue" SG_ 524 ALIV_IC_ODO "Fh";
BA_ "GenSigTimeoutTime_ALL" SG_ 524 MHU_Odometer_IC 500;
BA_ "InvalidValue" SG_ 524 MHU_Odometer_IC "FFFFFh";
BA_ "GenSigTimeoutTime_ALL" SG_ 525 CHKSM_IDB_STATUS 200;
BA_ "InvalidValue" SG_ 525 CHKSM_IDB_STATUS "null";
BA_ "GenSigTimeoutTime_ALL" SG_ 525 ALV_IDB_STATUS 200;
BA_ "InvalidValue" SG_ 525 ALV_IDB_STATUS "Fh";
BA_ "GenSigTimeoutTime_ALL" SG_ 525 ESPTransRequestType 200;
BA_ "InvalidValue" SG_ 525 ESPTransRequestType "null";
BA_ "GenSigTimeoutTime_ALL" SG_ 525 ABSFault 200;
BA_ "InvalidValue" SG_ 525 ABSFault "null";
BA_ "GenSigTimeoutTime_ALL" SG_ 525 ABSActive 200;
BA_ "InvalidValue" SG_ 525 ABSActive "null";
BA_ "GenSigTimeoutTime_ALL" SG_ 525 VehicleSpd 200;
BA_ "InvalidValue" SG_ 525 VehicleSpd "null";
BA_ "GenSigTimeoutTime_ALL" SG_ 525 MCPressureSts 200;
BA_ "InvalidValue" SG_ 525 MCPressureSts "null";
BA_ "GenSigTimeoutTime_ALL" SG_ 525 VehicleSpdSts 200;
BA_ "InvalidValue" SG_ 525 VehicleSpdSts "null";
BA_ "GenSigStartValue" SG_ 525 MCPressure 21;
BA_ "GenSigTimeoutTime_ALL" SG_ 525 MCPressure 200;
BA_ "InvalidValue" SG_ 525 MCPressure "FFh";
BA_ "GenSigTimeoutTime_ALL" SG_ 525 BRAKE_LightonRequestEPBi 200;
BA_ "InvalidValue" SG_ 525 BRAKE_LightonRequestEPBi "null";
BA_ "GenSigTimeoutTime_ALL" SG_ 525 VDCActive 200;
BA_ "InvalidValue" SG_ 525 VDCActive "null";
BA_ "GenSigTimeoutTime_ALL" SG_ 525 TCSActive 200;
BA_ "InvalidValue" SG_ 525 TCSActive "null";
BA_ "GenSigTimeoutTime_ALL" SG_ 525 TCSAvailable 200;
BA_ "InvalidValue" SG_ 525 TCSAvailable "null";
BA_ "GenSigTimeoutTime_ALL" SG_ 525 IDBActive 200;
BA_ "InvalidValue" SG_ 525 IDBActive "null";
BA_ "GenSigTimeoutTime_ALL" SG_ 525 IDBFault 200;
BA_ "InvalidValue" SG_ 525 IDBFault "null";
BA_ "GenSigTimeoutTime_ALL" SG_ 525 IDB_Power_Stage 200;
BA_ "InvalidValue" SG_ 525 IDB_Power_Stage "null";
BA_ "GenSigTimeoutTime_ALL" SG_ 527 ADAS_BCM_Status 500;
BA_ "InvalidValue" SG_ 527 ADAS_BCM_Status "null";
BA_ "GenSigTimeoutTime_ALL" SG_ 527 ADAS_BCM_HeadlightReq 500;
BA_ "InvalidValue" SG_ 527 ADAS_BCM_HeadlightReq "null";
BA_ "GenSigTimeoutTime_ALL" SG_ 527 ADAS_BCM_IndicatorlightReq 500;
BA_ "InvalidValue" SG_ 527 ADAS_BCM_IndicatorlightReq "null";
BA_ "GenSigTimeoutTime_ALL" SG_ 527 ADAS_BCM_FoldMirrorReq 500;
BA_ "InvalidValue" SG_ 527 ADAS_BCM_FoldMirrorReq "null";
BA_ "GenSigTimeoutTime_ALL" SG_ 527 SECCAN_ADAS_BCM_Sts 500;
BA_ "GenSigTimeoutTime_ALL" SG_ 528 CHKSM_RCU_Status 400;
BA_ "InvalidValue" SG_ 528 CHKSM_RCU_Status "null";
BA_ "GenSigTimeoutTime_ALL" SG_ 528 ALV_RCU_Status 400;
BA_ "InvalidValue" SG_ 528 ALV_RCU_Status "Fh";
BA_ "GenSigTimeoutTime_ALL" SG_ 528 RCU_DAA_NoOpDoorOpen_1 400;
BA_ "InvalidValue" SG_ 528 RCU_DAA_NoOpDoorOpen_1 "null";
BA_ "GenSigTimeoutTime_ALL" SG_ 528 RCU_EPBParkingStatus 400;
BA_ "InvalidValue" SG_ 528 RCU_EPBParkingStatus "3h";
BA_ "GenSigTimeoutTime_ALL" SG_ 528 EPB_Swch_Mafnc 400;
BA_ "InvalidValue" SG_ 528 EPB_Swch_Mafnc "null";
BA_ "GenSigTimeoutTime_ALL" SG_ 528 RCU_ParkBrkApplied_1 400;
BA_ "InvalidValue" SG_ 528 RCU_ParkBrkApplied_1 "null";
BA_ "GenSigTimeoutTime_ALL" SG_ 528 RCU_ReleaseEPB_Wo_PressBrk_1 400;
BA_ "InvalidValue" SG_ 528 RCU_ReleaseEPB_Wo_PressBrk_1 "null";
BA_ "GenSigTimeoutTime_ALL" SG_ 528 RCU_BrkForceNotEnough_1 400;
BA_ "InvalidValue" SG_ 528 RCU_BrkForceNotEnough_1 "null";
BA_ "GenSigTimeoutTime_ALL" SG_ 528 RCU_ParkOnSteepInclination_1 400;
BA_ "InvalidValue" SG_ 528 RCU_ParkOnSteepInclination_1 "null";
BA_ "GenSigTimeoutTime_ALL" SG_ 528 RCU_ECD_RWU_active_1 400;
BA_ "InvalidValue" SG_ 528 RCU_ECD_RWU_active_1 "null";
BA_ "GenSigTimeoutTime_ALL" SG_ 528 RCU_EHandBrk_fault_1 400;
BA_ "InvalidValue" SG_ 528 RCU_EHandBrk_fault_1 "null";
BA_ "GenSigTimeoutTime_ALL" SG_ 528 RCU_BRAKE_LightonRequestEPBi 400;
BA_ "InvalidValue" SG_ 528 RCU_BRAKE_LightonRequestEPBi "null";
BA_ "GenSigTimeoutTime_ALL" SG_ 533 Checksum_0x215 500;
BA_ "InvalidValue" SG_ 533 Checksum_0x215 "null";
BA_ "GenSigTimeoutTime_ALL" SG_ 533 Rolling_Counter_0x215 500;
BA_ "InvalidValue" SG_ 533 Rolling_Counter_0x215 "Fh";
BA_ "GenSigTimeoutTime_ALL" SG_ 533 BMS_BatBalance_ERR 500;
BA_ "InvalidValue" SG_ 533 BMS_BatBalance_ERR "null";
BA_ "GenSigTimeoutTime_ALL" SG_ 533 BMS_Balance_STS 500;
BA_ "InvalidValue" SG_ 533 BMS_Balance_STS "null";
BA_ "GenSigTimeoutTime_ALL" SG_ 533 BMS_IGN_Sts 500;
BA_ "InvalidValue" SG_ 533 BMS_IGN_Sts "null";
BA_ "GenSigTimeoutTime_ALL" SG_ 533 BMS_HWCrash_Sts 500;
BA_ "InvalidValue" SG_ 533 BMS_HWCrash_Sts "null";
BA_ "GenSigTimeoutTime_ALL" SG_ 533 BMS_HVIL_STS 500;
BA_ "InvalidValue" SG_ 533 BMS_HVIL_STS "3h";
BA_ "GenSigTimeoutTime_ALL" SG_ 533 BMS_HVOnOff_STS 500;
BA_ "InvalidValue" SG_ 533 BMS_HVOnOff_STS "null";
BA_ "GenSigTimeoutTime_ALL" SG_ 533 BMS_ERR_LEV 500;
BA_ "InvalidValue" SG_ 533 BMS_ERR_LEV "null";
BA_ "GenSigTimeoutTime_ALL" SG_ 533 BMS_SocActual_EST 500;
BA_ "InvalidValue" SG_ 533 BMS_SocActual_EST "3FFh";
BA_ "GenSigTimeoutTime_ALL" SG_ 533 BMS_Sys_STS 500;
BA_ "InvalidValue" SG_ 533 BMS_Sys_STS "8h";
BA_ "GenSigTimeoutTime_ALL" SG_ 533 BMS_ISU_Status 500;
BA_ "InvalidValue" SG_ 533 BMS_ISU_Status "null";
BA_ "GenSigStartValue" SG_ 533 BMS_SOH 54;
BA_ "GenSigTimeoutTime_ALL" SG_ 533 BMS_SOH 500;
BA_ "InvalidValue" SG_ 533 BMS_SOH "FFh";
BA_ "GenSigStartValue" SG_ 533 BMS_SOE 54;
BA_ "GenSigTimeoutTime_ALL" SG_ 533 BMS_SOE 500;
BA_ "InvalidValue" SG_ 533 BMS_SOE "FFh";
BA_ "GenSigTimeoutTime_ALL" SG_ 533 BMS_HV_Sts 500;
BA_ "GenSigTimeoutTime_ALL" SG_ 537 CHSKM_VCU_PTControl 200;
BA_ "InvalidValue" SG_ 537 CHSKM_VCU_PTControl "null";
BA_ "GenSigTimeoutTime_ALL" SG_ 537 ALV_VCU_PTControl 200;
BA_ "InvalidValue" SG_ 537 ALV_VCU_PTControl "Fh";
BA_ "GenSigTimeoutTime_ALL" SG_ 537 VCU_ChargeAllow 200;
BA_ "InvalidValue" SG_ 537 VCU_ChargeAllow "null";
BA_ "GenSigSendType" SG_ 544 MHU_SET_CCUR_AirCondition 2;
BA_ "InvalidValue" SG_ 544 MHU_SET_CCUR_AirCondition "3h";
BA_ "GenSigSendType" SG_ 544 MHU_SET_CCUR_AutoAC 2;
BA_ "InvalidValue" SG_ 544 MHU_SET_CCUR_AutoAC "3h";
BA_ "GenSigSendType" SG_ 544 MHU_SET_CCUR_RearLock 2;
BA_ "InvalidValue" SG_ 544 MHU_SET_CCUR_RearLock "3h";
BA_ "GenSigSendType" SG_ 544 MHU_SET_CCUR_MaxAc 2;
BA_ "InvalidValue" SG_ 544 MHU_SET_CCUR_MaxAc "3h";
BA_ "GenSigSendType" SG_ 544 MHU_SET_CCUR_FanSpeed 2;
BA_ "GenSigStartValue" SG_ 544 MHU_SET_CCUR_FanSpeed 3;
BA_ "InvalidValue" SG_ 544 MHU_SET_CCUR_FanSpeed "7h";
BA_ "GenSigSendType" SG_ 544 MHU_SET_CCUR_Recirculation 2;
BA_ "GenSigStartValue" SG_ 544 MHU_SET_CCUR_Recirculation 1;
BA_ "InvalidValue" SG_ 544 MHU_SET_CCUR_Recirculation "3h";
BA_ "GenSigSendType" SG_ 544 MHU_SET_CCUR_Ion 2;
BA_ "InvalidValue" SG_ 544 MHU_SET_CCUR_Ion "3h";
BA_ "GenSigSendType" SG_ 544 MHU_SET_CCUR_FlapPosition 2;
BA_ "InvalidValue" SG_ 544 MHU_SET_CCUR_FlapPosition "4h";
BA_ "GenSigSendType" SG_ 544 MHU_SET_CCUR_SyncClimateZone 2;
BA_ "InvalidValue" SG_ 544 MHU_SET_CCUR_SyncClimateZone "3h";
BA_ "GenSigSendType" SG_ 544 MHU_SET_CCUR_TempRear 2;
BA_ "GenSigStartValue" SG_ 544 MHU_SET_CCUR_TempRear 40;
BA_ "InvalidValue" SG_ 544 MHU_SET_CCUR_TempRear "FFh";
BA_ "GenSigSendType" SG_ 544 MHU_SET_CCUR_FrontDefrost 2;
BA_ "InvalidValue" SG_ 544 MHU_SET_CCUR_FrontDefrost "3h";
BA_ "GenSigTimeoutTime_ALL" SG_ 545 CCUR_Req_AirCondition 1000;
BA_ "InvalidValue" SG_ 545 CCUR_Req_AirCondition "3h";
BA_ "GenSigTimeoutTime_ALL" SG_ 545 CCUR_AirDistribFlapActPos 1000;
BA_ "InvalidValue" SG_ 545 CCUR_AirDistribFlapActPos "null";
BA_ "GenSigTimeoutTime_ALL" SG_ 545 CCUR_TempFlapActPos 1000;
BA_ "InvalidValue" SG_ 545 CCUR_TempFlapActPos "null";
BA_ "GenSigTimeoutTime_ALL" SG_ 545 SECCAN_CCUR 1000;
BA_ "InvalidValue" SG_ 545 SECCAN_CCUR "null";
BA_ "InvalidValue" SG_ 546 FRONT_SET_Rear_AirCondition "3h";
BA_ "InvalidValue" SG_ 546 SECCAN_CCUF "null";
BA_ "GenSigTimeoutTime_ALL" SG_ 547 NDoorFLVehicleLocked 200;
BA_ "InvalidValue" SG_ 547 NDoorFLVehicleLocked "1h";
BA_ "GenSigTimeoutTime_ALL" SG_ 547 NDoorFLVehicleMoving 200;
BA_ "InvalidValue" SG_ 547 NDoorFLVehicleMoving "1h";
BA_ "GenSigTimeoutTime_ALL" SG_ 547 NDoorFLOpenInvRequested 200;
BA_ "InvalidValue" SG_ 547 NDoorFLOpenInvRequested "1h";
BA_ "GenSigStartValue" SG_ 547 NDoorFLOpenRequested 3;
BA_ "GenSigTimeoutTime_ALL" SG_ 547 NDoorFLOpenRequested 200;
BA_ "InvalidValue" SG_ 547 NDoorFLOpenRequested "2h";
BA_ "GenSigStartValue" SG_ 547 NDoorFLChildLocked 3;
BA_ "GenSigTimeoutTime_ALL" SG_ 547 NDoorFLChildLocked 200;
BA_ "InvalidValue" SG_ 547 NDoorFLChildLocked "1h";
BA_ "GenSigStartValue" SG_ 547 NDoorFLVehicleCrash 3;
BA_ "GenSigTimeoutTime_ALL" SG_ 547 NDoorFLVehicleCrash 200;
BA_ "InvalidValue" SG_ 547 NDoorFLVehicleCrash "1h";
BA_ "GenSigTimeoutTime_ALL" SG_ 547 NDoorFLCommandCounter 200;
BA_ "InvalidValue" SG_ 547 NDoorFLCommandCounter "null";
BA_ "GenSigTimeoutTime_ALL" SG_ 547 NDoorFLCloseInvRequested 200;
BA_ "InvalidValue" SG_ 547 NDoorFLCloseInvRequested "null";
BA_ "GenSigTimeoutTime_ALL" SG_ 547 NDoorFLCloseRequested 200;
BA_ "InvalidValue" SG_ 547 NDoorFLCloseRequested "null";
BA_ "GenSigTimeoutTime_ALL" SG_ 548 CHSKM_VCU_BMS_Thermal_FB 500;
BA_ "InvalidValue" SG_ 548 CHSKM_VCU_BMS_Thermal_FB "null";
BA_ "GenSigTimeoutTime_ALL" SG_ 548 ALIV_VCU_BMS_Thermal_FB 500;
BA_ "InvalidValue" SG_ 548 ALIV_VCU_BMS_Thermal_FB "Fh";
BA_ "GenSigTimeoutTime_ALL" SG_ 548 VCU_BMS_PTCOnOff_Sts 500;
BA_ "InvalidValue" SG_ 548 VCU_BMS_PTCOnOff_Sts "null";
BA_ "GenSigTimeoutTime_ALL" SG_ 548 VCU_BMS_ValveOnOff_Sts 500;
BA_ "InvalidValue" SG_ 548 VCU_BMS_ValveOnOff_Sts "null";
BA_ "GenSigTimeoutTime_ALL" SG_ 548 VCU_BMS_PumpFB 500;
BA_ "InvalidValue" SG_ 548 VCU_BMS_PumpFB "null";
BA_ "GenSigStartValue" SG_ 561 NDoorFLHomeSignal 1;
BA_ "GenSigTimeoutTime_ALL" SG_ 561 NDoorFLHomeSignal 200;
BA_ "InvalidValue" SG_ 561 NDoorFLHomeSignal "null";
BA_ "GenSigStartValue" SG_ 561 NDoorFLSecondarySignal 1;
BA_ "GenSigTimeoutTime_ALL" SG_ 561 NDoorFLSecondarySignal 200;
BA_ "InvalidValue" SG_ 561 NDoorFLSecondarySignal "null";
BA_ "GenSigStartValue" SG_ 561 NDoorFLPrimarySignal 1;
BA_ "GenSigTimeoutTime_ALL" SG_ 561 NDoorFLPrimarySignal 200;
BA_ "InvalidValue" SG_ 561 NDoorFLPrimarySignal "null";
BA_ "GenSigStartValue" SG_ 561 NDoorFLClawSignal 1;
BA_ "GenSigTimeoutTime_ALL" SG_ 561 NDoorFLClawSignal 200;
BA_ "InvalidValue" SG_ 561 NDoorFLClawSignal "null";
BA_ "GenSigStartValue" SG_ 561 NDoorFLClawStatus 15;
BA_ "GenSigTimeoutTime_ALL" SG_ 561 NDoorFLClawStatus 200;
BA_ "InvalidValue" SG_ 561 NDoorFLClawStatus "null";
BA_ "GenSigTimeoutTime_ALL" SG_ 561 BDLFLResponseError 200;
BA_ "InvalidValue" SG_ 561 BDLFLResponseError "null";
BA_ "GenSigTimeoutTime_ALL" SG_ 561 NDoorFLCounter 200;
BA_ "InvalidValue" SG_ 561 NDoorFLCounter "null";
BA_ "GenSigTimeoutTime_ALL" SG_ 561 NDoorFLOutsideHandleFailure 200;
BA_ "InvalidValue" SG_ 561 NDoorFLOutsideHandleFailure "null";
BA_ "GenSigStartValue" SG_ 561 NDoorFLOutsideHandleStatus 1;
BA_ "GenSigTimeoutTime_ALL" SG_ 561 NDoorFLOutsideHandleStatus 200;
BA_ "InvalidValue" SG_ 561 NDoorFLOutsideHandleStatus "null";
BA_ "GenSigTimeoutTime_ALL" SG_ 561 NDoorLatchFLFailure 200;
BA_ "InvalidValue" SG_ 561 NDoorLatchFLFailure "null";
BA_ "GenSigTimeoutTime_ALL" SG_ 565 CHKSM_TRM_STATUS 500;
BA_ "InvalidValue" SG_ 565 CHKSM_TRM_STATUS "null";
BA_ "GenSigTimeoutTime_ALL" SG_ 565 ALIVE_TRM_STATUS 500;
BA_ "InvalidValue" SG_ 565 ALIVE_TRM_STATUS "Fh";
BA_ "GenSigTimeoutTime_ALL" SG_ 565 TowingDetected 500;
BA_ "InvalidValue" SG_ 565 TowingDetected "3h";
BA_ "GenSigTimeoutTime_ALL" SG_ 565 TrailerDetected 500;
BA_ "InvalidValue" SG_ 565 TrailerDetected "3h";
BA_ "GenSigStartValue" SG_ 569 NDoorRRHomeSignal 1;
BA_ "GenSigTimeoutTime_ALL" SG_ 569 NDoorRRHomeSignal 200;
BA_ "InvalidValue" SG_ 569 NDoorRRHomeSignal "null";
BA_ "GenSigStartValue" SG_ 569 NDoorRRSecondarySignal 1;
BA_ "GenSigTimeoutTime_ALL" SG_ 569 NDoorRRSecondarySignal 200;
BA_ "InvalidValue" SG_ 569 NDoorRRSecondarySignal "null";
BA_ "GenSigStartValue" SG_ 569 NDoorRRPrimarySignal 1;
BA_ "GenSigTimeoutTime_ALL" SG_ 569 NDoorRRPrimarySignal 200;
BA_ "InvalidValue" SG_ 569 NDoorRRPrimarySignal "null";
BA_ "GenSigStartValue" SG_ 569 NDoorRRClawSignal 1;
BA_ "GenSigTimeoutTime_ALL" SG_ 569 NDoorRRClawSignal 200;
BA_ "InvalidValue" SG_ 569 NDoorRRClawSignal "null";
BA_ "GenSigStartValue" SG_ 569 NDoorRRClawStatus 15;
BA_ "GenSigTimeoutTime_ALL" SG_ 569 NDoorRRClawStatus 200;
BA_ "InvalidValue" SG_ 569 NDoorRRClawStatus "null";
BA_ "GenSigTimeoutTime_ALL" SG_ 569 BDLRRResponseError 200;
BA_ "InvalidValue" SG_ 569 BDLRRResponseError "null";
BA_ "GenSigTimeoutTime_ALL" SG_ 569 NDoorRRCounter 200;
BA_ "InvalidValue" SG_ 569 NDoorRRCounter "null";
BA_ "GenSigStartValue" SG_ 569 NDoorRROutsideHandleFailure 1;
BA_ "GenSigTimeoutTime_ALL" SG_ 569 NDoorRROutsideHandleFailure 200;
BA_ "InvalidValue" SG_ 569 NDoorRROutsideHandleFailure "null";
BA_ "GenSigStartValue" SG_ 569 NDoorRROutsideHandleStatus 1;
BA_ "GenSigTimeoutTime_ALL" SG_ 569 NDoorRROutsideHandleStatus 200;
BA_ "InvalidValue" SG_ 569 NDoorRROutsideHandleStatus "null";
BA_ "GenSigTimeoutTime_ALL" SG_ 569 NDoorLatchRRFailure 200;
BA_ "InvalidValue" SG_ 569 NDoorLatchRRFailure "null";
BA_ "GenSigTimeoutTime_ALL" SG_ 578 NDoorFRVehicleLocked 200;
BA_ "InvalidValue" SG_ 578 NDoorFRVehicleLocked "1h";
BA_ "GenSigTimeoutTime_ALL" SG_ 578 NDoorFRVehicleMoving 200;
BA_ "InvalidValue" SG_ 578 NDoorFRVehicleMoving "1h";
BA_ "GenSigTimeoutTime_ALL" SG_ 578 NDoorFROpenInvRequested 200;
BA_ "InvalidValue" SG_ 578 NDoorFROpenInvRequested "1h";
BA_ "GenSigStartValue" SG_ 578 NDoorFROpenRequested 3;
BA_ "GenSigTimeoutTime_ALL" SG_ 578 NDoorFROpenRequested 200;
BA_ "InvalidValue" SG_ 578 NDoorFROpenRequested "2h";
BA_ "GenSigStartValue" SG_ 578 NDoorFRChildLocked 3;
BA_ "GenSigTimeoutTime_ALL" SG_ 578 NDoorFRChildLocked 200;
BA_ "InvalidValue" SG_ 578 NDoorFRChildLocked "1h";
BA_ "GenSigStartValue" SG_ 578 NDoorFRVehicleCrash 3;
BA_ "GenSigTimeoutTime_ALL" SG_ 578 NDoorFRVehicleCrash 200;
BA_ "InvalidValue" SG_ 578 NDoorFRVehicleCrash "1h";
BA_ "GenSigTimeoutTime_ALL" SG_ 578 NDoorFRCommandCounter 200;
BA_ "InvalidValue" SG_ 578 NDoorFRCommandCounter "null";
BA_ "GenSigTimeoutTime_ALL" SG_ 578 NDoorFRCloseInvRequested 200;
BA_ "InvalidValue" SG_ 578 NDoorFRCloseInvRequested "null";
BA_ "GenSigTimeoutTime_ALL" SG_ 578 NDoorFRCloseRequested 200;
BA_ "InvalidValue" SG_ 578 NDoorFRCloseRequested "null";

VAL_ 133 ACM_Crash_Sts 0 "No_Event" 1 "Crash_Detected" ;
VAL_ 133 ACM_Airbag_Deployment_Status 0 "No_Airbag_Deployment" 1 "Airbag_Deployment" ;
VAL_ 133 ACM_Crash_Intensity 0 "No_Crash" 1 "Crash_Intensity_1" 2 "Crash_Intensity_2" 3 "Crash_Intensity_3" ;
VAL_ 133 ACM_Front_Crash 0 "No_Event" 1 "Front_Crash_Detected" ;
VAL_ 133 ACM_DriverSide_Crash 0 "No_Event" 1 "Driverside_Crash_Detected" ;
VAL_ 133 ACM_PassSide_Crash 0 "No_Event" 1 "PasSide_Crash_Detected" ;
VAL_ 133 ACM_Rear_Crash 0 "No_Event" 1 "Rear_Crash_Detected" ;
VAL_ 133 ACM_Rollover_Crash 0 "No_Event" 1 "Rollover_Crash_Detected" ;
VAL_ 149 STAT_ABS 0 "No error" 1 "Error Full functionality of ABS is not available" 2 "Reserved" 3 "Signal invalid" ;
VAL_ 149 ABS_Active 0 "Inactive" 1 "Active" 2 "Reserved" 3 "Signal invalid" ;
VAL_ 149 AYC_Active 0 "Inactive" 1 "Active" 2 "Reserved" 3 "Signal invalid" ;
VAL_ 149 ASR_Active 0 "Inactive" 1 "Active" 2 "Reserved" 3 "Signal invalid" ;
VAL_ 149 STAT_DSC 0 "IDB normal" 1 "Traction Mode" 2 "IDB-OFF" 3 "Signal invalid" ;
VAL_ 149 DSC_Active 0 "Inactive" 1 "Active" 2 "Reserved" 3 "Signal invalid" ;
VAL_ 149 HBA_ActiveSignal 0 "Inactive" 1 "Active" 2 "Reserved" 3 "Signal invalid" ;
VAL_ 149 ARM_ActiveSignal 0 "Inactive" 1 "Active" 2 "Reserved" 3 "Signal invalid" ;
VAL_ 149 STAT_AutoHazardBlinking 0 "AutoHazardBlinking OFF" 1 "AutoHazardBlinking ON" 2 "Reserved" 3 "Signal invalid" ;
VAL_ 149 MSR_Active 0 "Inactive" 1 "Active" 2 "Reserved" 3 "Signal invalid" ;
VAL_ 149 HSA_ActiveSignal 0 "Inactive" 1 "Active" 2 "Reserved" 3 "Signal invalid" ;
VAL_ 149 EPBi_ECD_ActiveSignal 0 "Function supported by EPBi active signal" 1 "Function supported by EPBi no active" 2 "Reserved" 3 "Signal invalid" ;
VAL_ 149 TSM_Active 0 "Not active" 1 "Active" 2 "No trailer" 3 "Invalid" ;
VAL_ 149 HAS_Available 0 "No error" 1 "Error. Functionality of Hiil Hold is not available" 2 "Reserved" 3 "Signal invalid" ;
VAL_ 149 STAT_EBD 0 "No error" 1 "Error . Functionality of EBD is not available" 2 "Reserved" 3 "Signal invalid" ;
VAL_ 149 EBD_Active 0 "Inactive" 1 "Active" 2 "Reserved" 3 "Signal invalid" ;
VAL_ 149 ST_BRG_MSA 0 "vehicle is not held at speed 0 by the brake" 1 "vehicle is held at speed 0 by the brake" 14 "functions reports error" 15 "signal invalid" ;
VAL_ 217 VCU_HVsystem_status 0 "Not ready" 1 "HV On" 2 "ReadyToDrive" 3 "Charging" 4 "Error" 5 "Reserved" 6 "Reserved" 7 "Reserved" ;
VAL_ 217 VCU_ACPD_Percent_Valid 0 "Valid" 1 "Invalid" ;
VAL_ 217 VCU_ACTGear 0 "P" 1 "R" 2 "N" 3 "D" 4 "Reserved" 5 "Reserved" 6 "Reserved" 7 "Fault" ;
VAL_ 217 VCU_ACTGearValid 0 "Valid" 1 "Invalid" ;
VAL_ 217 VCU_ACT_DriveMode 0 "Normal mode" 1 "ECO mode" 2 "Sport mode" 3 "Reserved" 4 "Reserved" 5 "Reserved" 6 "Reserved" 7 "Invalid" ;
VAL_ 217 VCU_ACT_DriveMode_Valid 0 "Valid" 1 "Invalid" ;
VAL_ 217 VCU_HV_DRVsystem_status 0 "Not available" 1 "Normal" 2 "Degration" 3 "Limphome" 4 "Error" 5 "Reserved" 6 "Reserved" 7 "Reserved" ;
VAL_ 217 VCU_Recu_BrakeLight_ON_Req 0 "Brake light OFF" 1 "Brake light ON" 2 "Reserved" 3 "Signal not available" ;
VAL_ 256 MHU_UserProfileId 0 "User 1 - Guess mode" 1 "User 2 - Valet mode" 2 "User 3" 3 "User 4" 4 "User 5" 5 "User 6" 6 "User 7" 7 "User 8" 8 "User 9" 9 "User 10" 15 "Invalid Value" ;
VAL_ 256 MHU_Connectivity_Status 0 "Init" 1 "No Connection" 2 "LTE Internet Connection" 3 "WIFI Internet Establish" 4 "WIFI + LTE Connection" 5 "Reserved" 6 "Reserved" 7 "Reserved" ;
VAL_ 258 STAT_CL30s_Light_L 0 "OFF" 1 "ON" 2 "Failure" 3 "Signal invalid" ;
VAL_ 258 STAT_CL30s_L 0 "OFF" 1 "ON" 2 "Failure" 3 "Signal invalid" ;
VAL_ 258 STAT_CL15Wup_L 0 "OFF" 1 "ON" 2 "Failure" 3 "Signal invalid" ;
VAL_ 258 STAT_CrankRelayHW_BCM 0 "OFF" 1 "ON" 2 "Reserved" 3 "Signal invalid" ;
VAL_ 259 REQ_ConsumerControlSeatMassage 0 "Reduction not activ" 1 "Reduction activ" 2 "Reserved" 3 "Signal invalid" ;
VAL_ 259 REQ_ConsumerControlWirelessCharg 0 "Reduction not activ" 1 "Reduction activ" 2 "Reserved" 3 "Signal invalid" ;
VAL_ 259 REQ_ConsumerControlAudioVolumeCo 0 "No reduction" 1 "Level 1" 2 "Level 2" 3 "Reserved" 4 "Reserved" 5 "Reserved" 6 "Reserved" 7 "Signal invalid" ;
VAL_ 259 REQ_CCU_PTC_Limitation 0 "Step 0" 1 "Step 1" 2 "Step 2" 3 "Step 3" 4 "Reserved" 5 "Reserved" 6 "Reserved" 7 "Signal invalid" ;
VAL_ 259 REQ_ConsumerControlRearDefrost 0 "Reduction not activ" 1 "Reduction activ" 2 "Reserved" 3 "Signal invalid" ;
VAL_ 260 SOH_SUL 255 "Signal invalid" ;
VAL_ 260 SOH_SUL_STATE 0 "Not learned" 1 "Learned" 2 "Reserved" 3 "Signal invalid" ;
VAL_ 260 SOC_STATE 0 "deviation > 15% " 1 "deviation < 15%" 2 "deviation < 10%" 3 "invalid" ;
VAL_ 260 Resp_Error 0 "No Error" 1 "Error" ;
VAL_ 260 FLAG_INCONSTENCY 0 "No battery inconsistency" 1 "Battery inconsistency" ;
VAL_ 260 EBS_error 0 "No Error" 1 "Error" ;
VAL_ 260 FLAG_DISCONNECT 0 "No battery disconnection" 1 "Battery disconnection" ;
VAL_ 260 BCM_LV_Batt_Charging_Req 0 "Disable " 1 "Enable" ;
VAL_ 260 IBATT_QUIESCENT 253 "Outside quiescent current range" 254 "Reserved" 255 "Invalid" ;
VAL_ 261 BCM_STAT_TrunkAjar 0 "Closed" 1 "Opened" 2 "Reserved" 3 "Signal invalid" ;
VAL_ 261 BCM_STAT_DoorAjarFL 0 "Closed" 1 "Opened" 2 "Reserved" 3 "Signal invalid" ;
VAL_ 261 BCM_STAT_DoorAjarFR 0 "Closed" 1 "Opened" 2 "Reserved" 3 "Signal invalid" ;
VAL_ 261 BCM_STAT_DoorAjarRL 0 "Closed" 1 "Opened" 2 "Reserved" 3 "Signal invalid" ;
VAL_ 261 BCM_STAT_DoorAjarRR 0 "Closed" 1 "Opened" 2 "Reserved" 3 "Signal invalid" ;
VAL_ 261 BCM_STAT_BonnetAjar 0 "Closed" 1 "Opened" 2 "Reserved" 3 "Signal invalid" ;
VAL_ 262 BCM_DayRunningLampSts 0 "OFF" 1 "ON" 2 "Fault (Reserved)" 3 "Signal Invalid" ;
VAL_ 262 BCM_ReverseLightSts 0 "OFF" 1 "ON" 2 "Fault (Reserved)" 3 "Signal Invalid" ;
VAL_ 262 BCM_StopLightSts 0 "OFF" 1 "ON" 2 "Fault (Reserved)" 3 "Signal Invalid" ;
VAL_ 262 BCM_LicensePlateLightSts 0 "OFF" 1 "ON" 2 "Fault (Reserved)" 3 "Signal Invalid" ;
VAL_ 262 BCM_Fr_Dimming_dome_lampSts 0 "OFF" 1 "ON" 2 "Fault (Reserved)" 3 "Signal Invalid" ;
VAL_ 262 BCM_Rr_Dimming_dome_lampSts 0 "OFF" 1 "ON" 2 "Fault (Reserved)" 3 "Signal Invalid" ;
VAL_ 262 BCM_STAT_InteriorLight 0 "OFF" 1 "ON" 2 "Reserved" 3 "Signal invalid" ;
VAL_ 262 BCM_STAT_LightActivation 0 "OFF" 1 "PositionLight" 2 "LowBeam" 3 "AutoLight" 4 "Reserved" 5 "Reserved" 6 "Reserved" 7 "Signal invalid" ;
VAL_ 262 BCM_HighBeamSts 0 "OFF" 1 "ON" 2 "Fault (Reserved)" 3 "Signal Invalid" ;
VAL_ 262 BCM_LowBeamSts 0 "OFF" 1 "ON" 2 "Fault (Reserved)" 3 "Signal Invalid" ;
VAL_ 262 BCM_RearFogLmpSts 0 "OFF" 1 "ON" 2 "Fault (Reserved)" 3 "Signal Invalid" ;
VAL_ 262 BCM_FrntFogLmpSts 0 "OFF" 1 "ON" 2 "Fault (Reserved)" 3 "Signal Invalid" ;
VAL_ 262 BCM_PosLmpSts 0 "OFF" 1 "ON" 2 "Fault (Reserved)" 3 "Signal Invalid" ;
VAL_ 262 BCM_BackGrdCl58Sts 0 "OFF" 1 "ON" 2 "Fault (Reserved)" 3 "Signal Invalid" ;
VAL_ 262 BCM_HornSts 0 "OFF" 1 "ON" 2 "Fault (Reserved)" 3 "Signal Invalid" ;
VAL_ 262 BCM_TurnIndicatorSts 0 "OFF" 1 "Left On" 2 "Right On" 3 "Left and Right On" ;
VAL_ 263 STAT_CDL_LED 0 "OFF" 1 "ON" 2 "blinking" 3 "Signal invalid" ;
VAL_ 263 STAT_DoorUnlockFL 0 "Locked" 1 "Unlocked" 2 "Reserved" 3 "Signal invalid" ;
VAL_ 263 STAT_ATWS 0 "Secured" 1 "Unsecured" 2 "Alarm" 3 "Partly secured" 4 "Reserved" 5 "Reserved" 6 "Reserved" 7 "Signal invalid" ;
VAL_ 263 BCM_CentralLockSwSts 0 "OFF" 1 "ON" ;
VAL_ 263 STAT_DoorLockFL 0 "Unlocked" 1 "Locked" 2 "Reserved" 3 "Signal invalid" ;
VAL_ 265 BCM_STAT_BrakeSwitch 0 "Brake not pressed" 1 "Brake Pressed" 2 "Reserved" 3 "Signal invalid" ;
VAL_ 265 BCM_STAT_HazardWarn 0 "Not active" 1 "Active" 2 "Reserved" 3 "Signal invalid" ;
VAL_ 265 BCM_STAT_FuelPumpCutOFF 0 "Not active" 1 "Active" 2 "Reserved" 3 "Signal invalid" ;
VAL_ 265 BCM_FollowMeHomeActive 0 "Not Active" 1 "Active" 2 "Reserved" 3 "Signal Invalid" ;
VAL_ 265 BCM_STAT_Horn 0 "OFF" 1 "ON" 2 "Reserved" 3 "Signal invalid" ;
VAL_ 265 BCM_STAT_Autowiping 0 "OFF" 1 "ON" 2 "Reserved" 3 "Signal invalid" ;
VAL_ 265 BCM_TurnIndicator 0 "OFF" 1 "Left" 2 "Right" ;
VAL_ 265 BCM_WelcomeActive 0 "Not Active" 1 "Active" 2 "Reserved" 3 "Signal Invalid" ;
VAL_ 265 BCM_HighBeam 0 "OFF" 1 "High Beam" 2 "Flash high Beam" 3 "Fault" ;
VAL_ 265 ACM_Seat_Belt_Status_3rd_Row_Pas 0 "Not_buckled" 1 "Buckled" 2 "Not_Available" 3 "Failure" ;
VAL_ 265 ACM_Seat_Belt_Status_3rd_Row_Dri 0 "Not_buckled" 1 "Buckled" 2 "Not_Available" 3 "Failure" ;
VAL_ 265 BCM_AlcoholockSwitch 0 "Not active" 1 "Active" 2 "Reserved" 3 "Signal invalid" ;
VAL_ 266 LV_BatteryType 0 "Lead Acid Battery" 1 "Lithium Battery" 2 "Reversed" 3 "Invalid";
VAL_ 267 TrailerInput 0 "Trailer synchronous with CAN" 1 "Trailer synchronous with HW input" 2 "Reserved" 3 "Invalid" ;
VAL_ 267 TrailerSystemError 0 "No error" 1 "Error" 2 "Reserved" 3 "Invalid" ;
VAL_ 267 TRM_VoltageStatus 0 "No failure" 1 "Overvoltage" 2 "Undervoltage" 3 "Invalid" ;
VAL_ 267 TRM_STAT_BrakeLight 0 "OFF" 1 "ON" 2 "Reserved" 3 "Signal invalid" ;
VAL_ 267 TRM_STAT_FogLampRear 0 "OFF" 1 "ON" 2 "Failure" 3 "Signal invalid" ;
VAL_ 267 TRM_STAT_PositionLight 0 "PositionLight OFF" 1 "PositionLight ON" 2 "PositionLight failure" 3 "Signal invalid" ;
VAL_ 267 TRM_STAT_TurnIndicators 0 "OFF" 1 "Left turn lamp ON" 2 "Right turn lamp ON" 3 "Both turn lamps ON" 4 "Left turn lamp defect" 5 "Right turn lamp defect" 6 "Both turn lamp defect" 15 "Signal invalid" ;
VAL_ 267 TRM_STAT_ReverseLight 0 "OFF" 1 "ON" 2 "Reserved" 3 "Signal invalid" ;
VAL_ 267 TRM_STAT_HWBrakeLightInput 0 "Brakel Light Input not active TRM" 1 "Brakel Light Input  active TRM" 2 "Reserved" 3 "Signal invalid" ;
VAL_ 267 TRM_STAT_HWIndicatorInput 0 "Indicator Input not active TRM" 1 "Indicator Input active TRM" 2 "Reserved" 3 "Signal invalid" ;
VAL_ 267 TRM_STAT_HWPosLightInput 0 "PosLight nput not active TRM" 1 "PosLight input active TRM" 2 "Reserved" 3 "Signal invalid" ;
VAL_ 268 BCM_TboxAuthStatus 0 "Have not learn. Not allow action" 1 "PASSED" 2 "FALIED: Authentication fail" 3 "Invalid" ;
VAL_ 269 MHU_APM_ReqWindow 0 "No action" 1 "Closed(Top)" 2 "Open Bottom" ;
VAL_ 269 MHU_BCM_RemoteDoorCtrl 0 "Lock" 1 "Unlock" 2 "No action" 3 "Signal invalid" ;
VAL_ 269 MHU_BCM_reqTrunk 0 "Close" 1 "Open" 2 "No action" 3 "Signal invalid" ;
VAL_ 269 MHU_BCM_reqFrunk 0 "No action" 1 "Unlock" 2 "Reserved" 3 "Signal invalid" ;
VAL_ 269 MHU_BCM_ReqSunroof 0 "Closed" 127 "Vent" 150 "Stop" 255 "No Request" ;
VAL_ 270 GlobalWindowReq 0 "Global stop request" 1 "Global closing request via remote control" 2 "Global open request" 3 "Global closing request via CL Switch" 4 "Global closing request via DD Switch" 5 "Global closing request via C-App" 6 "Global Slightly Open request via C-App" 7 "Not Defined" ;
VAL_ 270 RemoteAccessKey 0 "No command" 1 "Lock" 2 "Unlock" 3 "Tailgate unlock long press" 4 "Tailgate unlock" 5 "Long press lock" 6 "Long press unlock" 7 "Panic alarm long press" 8 "Panic alarm press" 9 "Tailgate unlock double press" 15 "Invalid";
VAL_ 270 PassiveAccessTrunk 0 "Not pressed" 1 "Pressed" 2 "Reserved" 3 "Signal invalid" ;
VAL_ 270 ComfortOpen 0 "Not active" 1 "Active" 2 "Reserved" 3 "Signal invalid" ;
VAL_ 270 PassiveAccessDoor 0 "Not pressed" 1 "Pressed" 2 "PE switch long press" 3 "Extended Long Press" ;
VAL_ 270 FksOpen 0 "OFF" 1 "ON" 2 "Reserved" 3 "Signal invalid" ;
VAL_ 271 MHU_SetHornOnOff 0 "OFF" 1 "ON" 2 "No action" 3 "Invalid" ;
VAL_ 271 MHU_SetLowBeam 0 "OFF" 1 "ON" 2 "No action" 3 "Invalid" ;
VAL_ 271 MHU_SetHighBeam 0 "OFF" 1 "ON" 2 "No action" 3 "Invalid" ;
VAL_ 273 BCM_Rear_Wiper_Park_Pos_Status 0 "Rear wiper not in Parking position" 1 "Rear wiper in Parking position" ;
VAL_ 273 BCM_Front_Wiper_Park_Pos_Status 0 "Front wiper not in Parking position" 1 "Front wiper in Parking position" ;
VAL_ 273 BCM_Rear_Wash_Status 0 "RearWash OFF" 1 "Rear Wash ON" ;
VAL_ 273 BCM_Front_Wash_Status 0 "FrontWash OFF" 1 "Front Wash ON" ;
VAL_ 274 RemoteFunctionState 0 "Normal function" 1 "Remote function" 2 "Reserved" 3 "Signal Invalid" ;
VAL_ 274 STAT_BLS 0 "BLS not pressed" 1 "BLS pressed" 2 "Reserved" 3 "Signal invalid" ;
VAL_ 274 STAT_CL_50_L 0 "OFF" 1 "ON" 2 "Failure" 3 "Signal invalid" ;
VAL_ 274 Clamp50AdviceRemoteStart 0 "Engine Start announcement not active" 1 "Engine Start announcement active" 2 "Reserved" 3 "Invalid" ;
VAL_ 274 Clamp50AdviceESS 0 "Engine Start announcement not active" 1 "Engine Start announcement active" 2 "Reserved" 3 "Invalid" ;
VAL_ 274 STAT_TransportMode 0 "OFF" 1 "ON" 2 "Reserved" 3 "Reserved" ;
VAL_ 274 STAT_CL_R_L 0 "OFF" 1 "ON" 2 "Failure" 3 "Signal invalid" ;
VAL_ 274 STAT_CL_15_1_L 0 "OFF" 1 "ON" 2 "Failure" 3 "Signal invalid" ;
VAL_ 274 STAT_CL_15_1_DME_L 0 "OFF" 1 "ON" 2 "Failure" 3 "Signal invalid" ;
VAL_ 274 FobId 0 "Key not available" 1 "FOB_1" 2 "FOB_2" 3 "Signal invalid" ;
VAL_ 274 STAT_Terminal 0 "OFF(Comfort Enable)" 1 "ACC (Park)" 2 "ON (Driver Present)" 3 "Engine start (eMotor running)" 4 "SW Update OTA" 5 "Reserved" 6 "Reserved" 7 "Signal Invalid" ;
VAL_ 274 STAT_CL30_C_BEV 0 "OFF" 1 "ON" 2 "Failure" 3 "Signal invalid" ;
VAL_ 274 BCM_Clamp_Transport 0 "Transport Disabled" 1 "Transport E-Motor Running" 2 "Transport Driver Present" 3 "Ttransport ACC" 4 "Transport OFF" 5 "Init" 6 "Reserved " 7 "Reserved " ;
VAL_ 276 LV_ErrorSts 0 "None" 1 "BMS Warning" 2 "BMS temporarily fault" 3 "BMS permanent fault" 4 "Reserved" 5 "Reserved" 6 "Reserved" 7 "Invalid";
VAL_ 276 LV_Discharger_Err 0 "Normal" 1 "Error";
VAL_ 276 LV_Discharger_Sts 0 "Open" 1 "Close";
VAL_ 276 LV_Charger_Err 0 "Normal" 1 "Error";
VAL_ 276 LV_Charger_Sts 0 "Open" 1 "Close";
VAL_ 276 LV_OverVoltage 0 "No" 1 "Yes";
VAL_ 276 LV_UnderVoltage 0 "No" 1 "Yes";
VAL_ 276 LV_OverCurrent 0 "No" 1 "Yes";
VAL_ 276 LV_UnderTemp 0 "No" 1 "Yes";
VAL_ 276 LV_OverTemp 0 "No" 1 "Yes";
VAL_ 276 LV_OverCharge 0 "No" 1 "Yes";
VAL_ 276 LV_OverDischarge 0 "No" 1 "Yes";
VAL_ 276 LV_CellBalance_Sts 0 "Inactive" 1 "Active";
VAL_ 276 LV_CellBalance_Error 0 "Normal" 1 "Error";
VAL_ 276 LV_ThermalRunaway 0 "No" 1 "Yes";
VAL_ 276 LV_WarmupRequest 0 "Disable" 1 "Enable" 2 "Reserved" 3 "Signal invalid";
VAL_ 277 BCM_ChildLock_Feedback 0 "OFF" 1 "ON" 2 "Reserved" 3 "Signal Invalid" ;
VAL_ 278 LV_WakeupReason 0 "None" 1 "Low SOC Wakeup" 2 "Low Temp Wakeup" 3 "High discharge current wakeup" 4 "High charge current wakeup" 5 "Reserved" 6 "Reserved" 7 "Invalid";
VAL_ 280 BCM_DrvInhibitStsFbk 0 "No effect" 1 "Inhibited" 2 "UnInhibited" 3 "Signal Invalid";
VAL_ 282 MHU_SET_WiperServicePositionMod 0 "OFF" 1 "ON" 2 "Reserved" 3 "Signal Invalid" ;
VAL_ 282 MHU_Read_KeyFobOnCenterConsole 0 "No Request" 1 "Req Read Keyfob on CenterConsol" 2 "Reserved" 3 "Signal Invalid" ;
VAL_ 283 TBOX_STAT_TerminalReq 0 "OFF(Comfort Enable)" 1 "ACC (Park)" 2 "ON (Driver Present)" 3 "ON (eMotor Running)" 4 "OTA" 5 "Reserved" 6 "No action" 7 "Signal invalid" ;
VAL_ 284 TBOX_FOTA_STAT_TerminalReq 0 "OFF(Comfort Enable)" 1 "ACC(Park)" 2 "ON (Driver Present)" 3 "FOTA" 4 "Reserved" 5 "Reserved" 6 "No action" 7 "Signal Invalid" ;
VAL_ 285 CCU_FanSpeed_Rear 0 "Off" 1 "Level 1" 2 "Level 2" 3 "Level 3" 4 "Level 4" 5 "Level 5" 6 "Level 6" 7 "Reserved" 8 "Reserved" 9 "Reserved" 10 "Reserved" 11 "Reserved" 12 "Reserved" 13 "Reserved" 14 "Reserved" 15 "Signal Invalid" ;
VAL_ 287 MHU_DrvInhibitSts 0 "No effect" 1 "Inhibited" 2 "UnInhibited" 3 "Signal Invalid";
VAL_ 290 CCU_REQ_MaxCool 0 "OFF" 1 "ON" 2 "Reserved" 3 "Signal invalid" ;
VAL_ 290 CCU_REQ_MaxHeat 0 "OFF" 1 "ON" 2 "Reserved" 3 "Signal invalid" ;
VAL_ 290 CCU_REQ_ESSMotorControl 0 "No action" 1 "inhibit motor stop" 2 "request motor start" 3 "Reserved" 4 "Reserved" 5 "Reserved" 6 "Reserved" 7 "Signal invalid" ;
VAL_ 303 ST_KL 0 "Init" 1 "Reserved" 2 "KL30" 3 "Reserved" 4 "Reserved" 5 "Reserved" 6 "KL30B-ON" 7 "KL30C-ON (BEV Only)" 8 "KLR-ON" 9 "KL15-change" 10 "KL15-ON" 11 "KL50-delay (ICE only)" 12 "KL50-Change(ICE only)" 13 "KL50-ON (ICE only)" 14 "Reserved" 15 "Signal invalid" ;
VAL_ 303 ST_KL_KEY_VLD 0 "Init" 1 "Key invalid" 2 "Key search activ" 3 "Key valid AR" 4 "Key valid IR" 5 "Key 10sec delay" 6 "Reserved" 7 "Reserved" 8 "Reserved" 9 "Reserved" 10 "Reserved" 11 "Reserved" 12 "Reserved" 13 "Reserved" 14 "Error" 15 "Signal invalid" ;
VAL_ 303 STAT_AlcoholEngineStatus 0 "OFF" 1 "ON" 2 "Reserved" 3 "Signal invalid" ;
VAL_ 303 ST_STCD_PENG 0 "Startcondition traction not fulfilled" 1 "Startcondition traction fulfilled" 2 "Startcondition traction  implausible fulfilled" 3 "Signal invalid" ;
VAL_ 303 ST_SSB 0 "SSB not pressed" 1 "SSB pressed" 2 "Reserve" 3 "Signal invalid" ;
VAL_ 303 RWDT_BLS 0 "BLTS and BLS not applied" 1 "BLS applied" 2 "BLTS  applied" 3 "BLTS and BLS  valid applied" 4 "Reserved" 5 "Reserved" 6 "Reserved" 7 "Error (Invalid signal from BLTS or BLS)" 8 "Init" 15 "Signal invalid" ;
VAL_ 303 RQ_DRVG_RDI 0 "No action" 1 "Engine start advice" 2 "Reserved" 3 "Signal invalid" ;
VAL_ 303 STAT_AlcoholIgnStatus 0 "OFF" 1 "ON" 2 "Reserved" 3 "Signal invalid" ;
VAL_ 303 CTR_ENG_STOP 0 "Init" 1 "Default" 2 "Motor_Off" 3 "Signal invalid" ;
VAL_ 303 ST_VEH_CON 0 "Initial (VSM_STM_STATE_INIT)" 1 "Standby, driver absent (VSM_STM_STATE_STANDBY)" 2 "Basis operation, driver present (VSM_STM_STATE_BASICOP)" 3 "Basis operation, vehicle coasting (VSM_STM_STATE_BASICOP_ROLL)" 4 "Engine postrun (VSM_STM_STATE_15OFF_DRIVE)" 5 "Ignition On (VSM_STM_STATE_IGNITION)" 6 "Ignition On, vehicle coasting (VSM_STM_STATE_IGNITION_ROLL)" 7 "Engine On, vehicle not coasting (VSM_STM_STATE_ENG_IDLE)" 8 "Driving (VSM_STM_STATE_DRIVE)" 9 "Impending start of engine (VSM_STM_STATE_ENG_START_PRE)" 10 "Impending start of engine, vehicle coasting (VSM_STM_STATE_ENG_START_PRE_ROLL)" 11 "Start engine (VSM_STM_STATE_ENG_START)" 12 "Start engine, vehicle coasting (VSM_STM_STATE_ENG_START_ROLL)" 13 "Car wash operation (VSM_STM_STATE_WASH)" 14 "Error (VSM_STM_STATE_ERROR)" 15 "Signal invalid" ;
VAL_ 359 TWV1_St_Feedback 0 "Over Voltage" 1 "Under Voltage" 2 "OverTemp_Warning" 3 "OverTemp_ShutDown" 4 "Over Current" 5 "Stall" 6 "OpenLoad" 7 "Communication_Error" 8 "WTREST" 9 "POR" 10 "SensorOVR" 11 "Reserved" 12 "Reserved" 13 "Reserved" 14 "Reserved" 15 "TrgPosDone" ;
VAL_ 359 TWV1_Frm_Error 0 "Normal" 1 "Error" ;
VAL_ 376 YSS_LONG_ACCUNFILTERED_QUAL 2 "VALID" 4 "SUBSITUTE" 6 "IN VALID" 14 "NOT AVAILABLE" 15 "UNFILLED" ;
VAL_ 376 YSS_LONG_ACC_QUAL 2 "VALID" 4 "SUBSITUTE" 6 "IN VALID" 14 "NOT AVAILABLE" 15 "UNFILLED" ;
VAL_ 381 YSS_YAW_RATEUNFILTERED_QUAL 2 "VALID" 4 "SUBSITUTE" 6 "IN VALID" 14 "NOT AVAILABLE" 15 "UNFILLED" ;
VAL_ 381 YSS_YAW_RATE_QUAL 2 "VALID" 4 "SUBSITUTE" 6 "IN VALID" 14 "NOT AVAILABLE" 15 "UNFILLED" ;
VAL_ 381 YSS_SC_STATUS 0 "No Mistake" 2 "Under Voltage" 3 "Over Voltage" 13 "Function Not Available" 14 "Function Error" 15 "Un-Filled" ;
VAL_ 382 SAS_SASStsSnsr 0 "sensor value  Invalid" 1 "sensor value  valid" ;
VAL_ 382 SAS_SteerWhlRotSpdStatus 0 "Invalid" 1 "Valid" ;
VAL_ 382 SAS_SASFailure 0 "Failure" 1 "No Failure" ;
VAL_ 382 SAS_Calibrated 0 "Not Calibrated" 1 "Calibrated" ;
VAL_ 382 SAS_SteerWheelAngleValid 0 "Valid" 1 "Invalid" ;
VAL_ 385 CAM_CamSts 0 "Not Available for ADB" 1 "Available for ADB" 2 "Camera Fault" 3 "reserved" ;
VAL_ 385 CAM_AmbLi 0 "Not Active for HighBeam (Day)" 1 "Active for Highbeam (Night)" ;
VAL_ 385 CAM_RoadIllmn 0 "Road illumination Not Detected" 1 "Road illumination Detected" ;
VAL_ 385 CAM_Obj_TrfcStyle 0 "Unknown" 1 "Right Hand Traffic" 2 "Left Hand Traffic" 3 "Not Available" ;
VAL_ 401 CAM_Obj1_Valid 0 "Invalid" 1 "Valid" ;
VAL_ 401 CAM_Obj1_Typ 0 "Unknown" 1 "Oncoming Object" 2 "Preceding Object" 3 "Reflective Object " ;
VAL_ 404 CAM_Obj2_Valid 0 "Invalid" 1 "Valid" ;
VAL_ 404 CAM_Obj2_Typ 0 "Unknown" 1 "Oncoming Object" 2 "Preceding Object" 3 "Reflective Object " ;
VAL_ 406 CAM_Obj3_Valid 0 "Invalid" 1 "Valid" ;
VAL_ 406 CAM_Obj3_Typ 0 "Unknown" 1 "Oncoming Object" 2 "Preceding Object" 3 "Reflective Object " ;
VAL_ 410 CAM_Obj4_Valid 0 "Invalid" 1 "Valid" ;
VAL_ 410 CAM_Obj4_Typ 0 "Unknown" 1 "Oncoming Object" 2 "Preceding Object" 3 "Reflective Object " ;
VAL_ 412 CAM_Obj5_Valid 0 "Invalid" 1 "Valid" ;
VAL_ 412 CAM_Obj5_Typ 0 "Unknown" 1 "Oncoming Object" 2 "Preceding Object" 3 "Reflective Object " ;
VAL_ 413 CAM_Obj6_Valid 0 "Invalid" 1 "Valid" ;
VAL_ 413 CAM_Obj6_Typ 0 "Unknown" 1 "Oncoming Object" 2 "Preceding Object" 3 "Reflective Object " ;
VAL_ 414 CAM_Obj7_Valid 0 "Invalid" 1 "Valid" ;
VAL_ 414 CAM_Obj7_Typ 0 "Unknown" 1 "Oncoming Object" 2 "Preceding Object" 3 "Reflective Object " ;
VAL_ 415 CAM_Obj8_Valid 0 "Invalid" 1 "Valid" ;
VAL_ 415 CAM_Obj8_Typ 0 "Unknown" 1 "Oncoming Object" 2 "Preceding Object" 3 "Reflective Object " ;
VAL_ 417 DVCO_VEH 0 "Vehicle is stationary" 1 "Vehicle is moving forward" 2 "Vehicle is reversing" 3 "Vehicle is moving " 4 "Vehicle is stationary rear axle rol" 5 "Vehicle is stationary all axle roll" 6 "Vehicle is stationary Front axle roll" 7 "Signal invalid" ;
VAL_ 417 QU_V_VEH_COG 1 "Signal value is valid and secured and plausible" 2 "Reserved" 3 "Reserved" 4 "Reserved" 6 "Reserved" 7 "Reserved" 8 "Init" 9 "Reserved" 10 "Signal value is valid" 11 "Signal quality or monitoring limited" 12 "Reserved" 14 "Signal value is invalid" 15 "Signal invalid" ;
VAL_ 504 EDS_Work_STS_FR 0 "default" 1 "init" 2 "standby" 3 "precharge" 4 "normal" 5 "HVReady" 6 "6SO" 11 "shut down" 12 "after run" 13 "Failure" 14 "power off" 15 "invaild" ;
VAL_ 504 EDS_output_trqValid_FR 0 "invalid" 1 "valid" ;
VAL_ 504 EDS_MotorDriveSts_FR 0 "Zero control" 1 "Drive control" 2 "regen control" 3 "Invaild" ;
VAL_ 504 EDS_powoff_req_FR 0 "(No request)" 1 "(Request high voltage power down)" ;
VAL_ 504 EDS_SpdValid_FR 0 "invalid" 1 "valid" ;
VAL_ 504 EDS_VCU_6SO_flag_FWD 0 "OFF" 1 "ON" ;
VAL_ 505 EDS_Work_STS_RR 0 "default" 1 "init" 2 "standby" 3 "precharge" 4 "normal" 5 "HVReady" 6 "6SO" 11 "shut down" 12 "after run" 13 "Failure" 14 "power off" 15 "invaild" ;
VAL_ 505 EDS_output_trqValid_RR 0 "invalid" 1 "valid" ;
VAL_ 505 EDS_MotorDriveSts_RR 0 "Zero control" 1 "Drive control" 2 "regen control" 3 "Invaild" ;
VAL_ 505 EDS_powoff_req_RR 0 "(No request)" 1 "(Request high voltage power down)" ;
VAL_ 505 EDS_SpdValid_RR 0 "invalid" 1 "valid" ;
VAL_ 505 EDS_VCU_6SO_flag_RWD 0 "OFF" 1 "ON" ;
VAL_ 519 SR_Undervoltage_Fault_Sts 0 "Normal" 1 "Fault" ;
VAL_ 519 SR_Overvoltage_Fault_Sts 0 "Normal" 1 "Fault" ;
VAL_ 519 SR_SLEEP_RQ 0 "Sleep Not Ready" 1 "Ready to Sleep" ;
VAL_ 519 SR_Position 0 "Unknown -Default" 1 "All Closed" 2 "All Closed To Tilt" 3 "Tilt" 4 "Tilt to Half Open" 5 "Half Open" 6 "Half Open to Open" 7 "ALL Open" ;
VAL_ 519 SR_Motor_Running_Sts 0 "Stop" 1 "Open Direction" 2 "Close Direction" 3 "Not Used" ;
VAL_ 519 SR_MotorReverse_Fault_Sts 0 "Normal" 1 "Fault" ;
VAL_ 519 SR_Hall_Fault_Sts 0 "Normal" 1 "Fault" ;
VAL_ 519 SR_Normalisation_Sts 0 "Normalised" 1 "Not normalised" ;
VAL_ 519 SR_Relay_Fault 0 "Normal" 1 "Fault" ;
VAL_ 519 SR_Commu_Fault_Sts 0 "Normal" 1 "Fault" ;
VAL_ 519 SR_Initialisation_Status 0 "Initialised" 1 "Not initialised" ;
VAL_ 519 SR_Ctrl_Result 0 "No Response" 1 "Running" 2 "Succeed" 3 "Failed" ;
VAL_ 519 SR_ThermalProtection_Fault_Sts 0 "Normal" 1 "Fault" ;
VAL_ 519 SR_Posit_Percentage 127 "Invalid" ;
VAL_ 519 SR_Operation_Stat 0 "Idle/Not pressed" 1 "Manual Slide Open" 2 "Manual Slide Closed" 3 "ManualTilt Open" 4 "Manual Tilt Closed" 5 "Auto Slide Open" 6 "Auto Slide Closed" 7 "Auto Tilt Open" 8 "Auto Tilt Closed" ;
VAL_ 519 SR_Error_RSP 0 "No Error" 1 "Error" ;
VAL_ 519 BCM_AutoSunroof_Sts 0 "OFF" 1 "Glass Only" 2 "Glass & Shade" 3 "Signal invalid";
VAL_ 520 SS_MotorReverse_Fault_Status 0 "Normal" 1 "Fault" ;
VAL_ 520 SS_Motor_Running_Status 0 "Stop" 1 "Open direction" 2 "Close direction" 3 "Not Used" ;
VAL_ 520 SS_Position 0 "Unknown-Default" 1 "All Closed" 2 "All Closed to Ajar" 3 "Ajar" 4 "Ajar to Half Open" 5 "Half Open" 6 "Half Open to Open" 7 "All Open" ;
VAL_ 520 SS_SLEEP_RQ 0 "Sleep Not Ready" 1 "Ready to Sleep" ;
VAL_ 520 SS_Undervoltage_Fault_Status 0 "Normal" 1 "Fault" ;
VAL_ 520 SS_Ctrl_Result 0 "No Response" 1 "Running" 2 "Succeed" 3 "Failed" ;
VAL_ 520 SS_Overvoltage_Fault_Status 0 "Normal" 1 "Fault" ;
VAL_ 520 SS_Relay_Fault 0 "Normal" 1 "Fault" ;
VAL_ 520 SS_Normalisation_Status 0 "Normalised" 1 "Not normalised" ;
VAL_ 520 SS_Hall_Fault_Status 0 "Normal" 1 "Fault" ;
VAL_ 520 SS_Commu_Fault_Status 0 "Normal" 1 "Fault" ;
VAL_ 520 SS_Initialisation_Status 0 "Normal" 1 "Fault" ;
VAL_ 520 SS_Posit_Percentage 127 "Invalid" ;
VAL_ 520 SS_ThermalProtection_Flt_Sts 0 "Normal" 1 "Fault" ;
VAL_ 520 SS_Operation_State 0 "Idle/Not pressed" 1 "Stop" 2 "Tilt Man" 3 "Tilt Auto" 4 "Close Man" 5 "Close Auto" 6 "Open Man" 7 "Open Auto" ;
VAL_ 520 SS_Error_RSP 0 "No Error" 1 "Error" ;
VAL_ 522 ETG_Lift_Gate_Status 0 "Fully closed" 1 "Fully opened" 2 "Stoped halfway" 3 "Ready to open" 4 "Opening" 5 "Ready to close" 6 "Closing" 7 "SNA (Signal not available)" ;
VAL_ 522 ETG_Power_Latch_Status 0 "uninitialized" 1 "Stoped" 2 "Cinching" 3 "Cinching reset" 4 "Releasing" 5 "Releasing reset" 7 "SNA" ;
VAL_ 522 ETG_Latch_Segment 0 "Full latch" 1 "Half latch" 2 "Open latch" 3 "SNA" ;
VAL_ 522 ETG_DSW_Status 0 "Not active" 1 "Active" ;
VAL_ 522 ETG_GSW_Status 0 "Not active" 1 "Active" ;
VAL_ 522 ETG_LTS_Status 0 "Not active" 1 "Active" ;
VAL_ 522 ETG_RTS_Status 0 "Not active" 1 "Active" ;
VAL_ 522 ETG_HAL_Status 0 "Low level" 1 "High level" ;
VAL_ 522 ETG_FUL_Status 0 "Low level" 1 "High level" ;
VAL_ 522 ETG_AJR_Status 0 "Low level" 1 "High level" ;
VAL_ 522 ETG_NTL_Status 0 "Low level" 1 "High level" ;
VAL_ 522 ETG_ERR_Voltage 0 "Normal" 1 "Under voltage" 2 "Over voltage" ;
VAL_ 522 ETG_ERR_Left_Motor 0 "Normal" 1 "Open circuit" 2 "short circuit" ;
VAL_ 522 ETG_ERR_Right_Motor 0 "Normal" 1 "Open circuit" 2 "short circuit" ;
VAL_ 522 ETG_ERR_Latch 0 "Normal" 1 "Open circuit" 2 "short circuit" ;
VAL_ 522 ETG_ERR_Hall 0 "Normal" 1 "Hall power short circuit" 2 "Hall position out of range" 3 "Hall signal out of sync" ;
VAL_ 522 ETG_Lift_Motor_Stall 0 "Not active" 1 "Active" ;
VAL_ 522 ETG_Lift_Motor_AntiPinch 0 "Not active" 1 "Active" ;
VAL_ 522 ETG_Lift_Motor_Thermal 0 "Not active" 1 "Active" ;
VAL_ 522 ETG_Power_Latch_Thermal 0 "Not active" 1 "Active" ;
VAL_ 522 ETG_Abuse_Protection 0 "Not active" 1 "Active" ;
VAL_ 523 FKS_RespError 0 "Ok" 1 "Error active" ;
VAL_ 523 FKS_OpenReq 0 "Idle" 1 "Operation Request" 2 "Invalid" 3 "Invalid" ;
VAL_ 523 FKS_HWError 0 "No Error" 1 "Error" ;
VAL_ 523 FKS_AntennaError 0 "No Error" 1 "Bottom or Top Sensor not connected" 2 "Bottom sensor short to Power or GND" 3 "Top sensor short to Power or GND" ;
VAL_ 523 FKS_OverVolDected 0 "No Error" 1 "Error" ;
VAL_ 523 FKS_UnderVolDected 0 "No Error" 1 "Error" ;
VAL_ 523 FKS_activate_deactivate 0 "Deactivated" 1 "Activated" 2 "Reserved" 3 "Signal invalid" ;
VAL_ 525 ESPTransRequestType 0 "No action" 1 "Inhibit upshift" 2 "Inhibit downshift" 3 "Hold gear" ;
VAL_ 525 ABSFault 0 "No fault" 1 "Fault" ;
VAL_ 525 ABSActive 0 "Inactive" 1 "Active" ;
VAL_ 525 MCPressureSts 0 "Valid" 1 "Invalid" ;
VAL_ 525 VehicleSpdSts 0 "Valid" 1 "Invalid" ;
VAL_ 525 BRAKE_LightonRequestEPBi 0 "Brake light OFF" 1 "Brake light ON" 2 "Reserved" 3 "Signal not available" ;
VAL_ 525 VDCActive 0 "Inactive" 1 "Active" ;
VAL_ 525 TCSActive 0 "Inactive" 1 "Active" ;
VAL_ 525 TCSAvailable 0 "Avialable" 1 "Unavailable" ;
VAL_ 525 IDBActive 0 "Inactive" 1 "Active" ;
VAL_ 525 IDBFault 0 "No fault" 1 "Fault" ;
VAL_ 525 IDB_Power_Stage 0 "Motor Max Power 150Kw" 1 "Motor Max Power 300Kw" 2 "Reserved" 3 "Reserved" 15 "Invalid" ;
VAL_ 527 ADAS_BCM_Status 0 "Off" 1 "Standby" 2 "Enable" 3 "Active" 4 "Finished" 5 "Suspend" 6 "Abort" 7 "Failed" ;
VAL_ 527 ADAS_BCM_HeadlightReq 0 "No request" 1 "Request turn on" ;
VAL_ 527 ADAS_BCM_IndicatorlightReq 0 "No request" 1 "Left" 2 "Right" 3 "Hazard" 4 "Turn Indicator Off" ;
VAL_ 527 ADAS_BCM_FoldMirrorReq 0 "No request" 1 "Fold in" 2 "Fold out" 3 "Reserved" ;
VAL_ 528 RCU_DAA_NoOpDoorOpen_1 0 "No Error" 1 "Error";
VAL_ 528 RCU_EPBParkingStatus 0 "Both brakes released" 1 "both brakes applied" 2 "Both brakes in operation (applying/releasing)" 3 "unknown";
VAL_ 528 EPB_Swch_Mafnc 0 "No Error" 1 "Error";
VAL_ 528 RCU_ParkBrkApplied_1 0 "No Error" 1 "Error";
VAL_ 528 RCU_ReleaseEPB_Wo_PressBrk_1 0 "No Error" 1 "Error";
VAL_ 528 RCU_BrkForceNotEnough_1 0 "No Error" 1 "Error";
VAL_ 528 RCU_ParkOnSteepInclination_1 0 "No Error" 1 "Error";
VAL_ 528 RCU_ECD_RWU_active_1 0 "No Error" 1 "Error";
VAL_ 528 RCU_EHandBrk_fault_1 0 "No Error" 1 "Error";
VAL_ 528 RCU_BRAKE_LightonRequestEPBi 0 "Brake light OFF" 1 "Brake light ON" 2 "Reserved" 3 "Signal not available";
VAL_ 533 BMS_BatBalance_ERR 0 "Error" 1 "normal" ;
VAL_ 533 BMS_Balance_STS 0 "Inactive" 1 "active" ;
VAL_ 533 BMS_IGN_Sts 0 "OFF" 1 "ON" ;
VAL_ 533 BMS_HWCrash_Sts 0 "No Crash" 1 "Crash" ;
VAL_ 533 BMS_HVIL_STS 0 "Closed" 1 "Open & short to battery" 2 "short to ground" 3 "Signal invalid";
VAL_ 533 BMS_HVOnOff_STS 0 "HV Off" 1 "Precharge" 2 "HV On" 3 "Fail to HV on" ;
VAL_ 533 BMS_ERR_LEV 0 "No error" 1 "Warning" 2 "Limp Home" 3 "Power down without FTTI" 4 "Delay power down with FTTI" 5 "Emergency off condition" 6 "Fault, needs to shutdown and wakeup" 7 "Battery locked - reserved" ;
VAL_ 533 BMS_Sys_STS 0 "Initialization of power on, self-checking" 1 "Self-check passes, can be high-voltage" 2 "Successful High Voltage Power Up" 3 "Successful Power Down of HV" 4 "Power Down process" 5 "Successful Power Down" 6 "BCU Sleep mode" 7 "Failure, unable to operate" 8 "Invalid" ;
VAL_ 533 BMS_ISU_Status 0 "Normal (> 250 kOhms)" 1 "Level1 (<250 kOhms ~ >100 kOhms)" 3 "Level3 (<100 kOhms)" ;
VAL_ 533 BMS_HV_Sts 0 "HV Off" 1 "Pre Charge" 2 "HV On" 3 "Super_Fast_Charge" 4 "AC Charge" 5 "Undefined" 6 "Undefined" 7 "Undefined" 8 "Undefined" 9 "Undefined" ;
VAL_ 537 VCU_ChargeAllow 0 "Not allow" 1 "Allow" ;
VAL_ 544 MHU_SET_CCUR_AirCondition 0 "Not pressed" 1 "Pressed" 2 "Reserved" 3 "Signal invalid" ;
VAL_ 544 MHU_SET_CCUR_AutoAC 0 "Not pressed" 1 "Pressed" 2 "Reserved" 3 "Signal invalid" ;
VAL_ 544 MHU_SET_CCUR_RearLock 0 "Not pressed" 1 "Pressed" 2 "Reserved" 3 "Signal invalid" ;
VAL_ 544 MHU_SET_CCUR_MaxAc 0 "Not pressed" 1 "Pressed" 2 "Reserved" 3 "Signal invalid" ;
VAL_ 544 MHU_SET_CCUR_FanSpeed 0 "OFF" 1 "Level1" 2 "Level2" 3 "Level3" 4 "Level4" 5 "Level5" 6 "Level6" 7 "Signal invalid" ;
VAL_ 544 MHU_SET_CCUR_Recirculation 0 "Inside" 1 "Outside" 2 "Auto" 3 "Signal invalid" ;
VAL_ 544 MHU_SET_CCUR_Ion 0 "Not pressed" 1 "Pressed" 2 "Reserved" 3 "Signal invalid" ;
VAL_ 544 MHU_SET_CCUR_FlapPosition 0 "OFF" 1 "Face" 2 "Face and Feet" 3 "Feet" 4 "Feet and Defrost" 5 "Defrost" 6 "Default" 7 "Signal Invalid" ;
VAL_ 544 MHU_SET_CCUR_SyncClimateZone 0 "Not pressed" 1 "Pressed" 2 "Reserved" 3 "Signal invalid" ;
VAL_ 544 MHU_SET_CCUR_TempRear 32 "16" 33 "16.5" 34 "17" 35 "17.5" 36 "18" 37 "18.5" 38 "19" 39 "19.5" 40 "20" 41 "20.5" 42 "21" 43 "21.5" 44 "22" 45 "22.5" 46 "23" 47 "23.5" 48 "24" 49 "24.5" 50 "25" 51 "25.5" 52 "26" 53 "26.5" 54 "27" 55 "27.5" 56 "28" 57 "28.5" 58 "29" 59 "29.5" 60 "30" 61 "30.5" 62 "31" 63 "31.5" 64 "32" 255 "Invalid Value" ;
VAL_ 544 MHU_SET_CCUR_FrontDefrost 0 "Not pressed" 1 "Pressed" 2 "Reserved" 3 "Signal invalid" ;
VAL_ 546 FRONT_SET_Rear_AirCondition 0 "Not pressed" 1 "Pressed" 2 "Reserved" 3 "Signal invalid" ;
VAL_ 547 NDoorFLVehicleLocked 0 "Default (Locked)" 1 "Reserved" 2 "Unlocked (Inactive)" 3 "Locked (Full Decouple)" ;
VAL_ 547 NDoorFLVehicleMoving 0 "default (in motion)" 1 "Reserved" 2 "static (inactive)" 3 "in motion (decouple external)" ;
VAL_ 547 NDoorFLOpenInvRequested 0 "default (release inactive)" 1 "Reserved" 2 "open (active release request)" 3 "close (release inactive)" ;
VAL_ 547 NDoorFLOpenRequested 0 "close (release inactive)" 1 " open (release request active)" 2 "Reserved" 3 "default (release inactive)" ;
VAL_ 547 NDoorFLChildLocked 0 "default (locked)" 2 "unlocked (inactive)" 3 "locked (full decouple)" ;
VAL_ 547 NDoorFLVehicleCrash 0 "default (locked)" 2 "Not trigger (inactive)" 3 "Trigger (full decouple)" ;
VAL_ 547 NDoorFLCloseInvRequested 0 "default (Cinch latching  inactive)" 1 "Reserved" 2 "open (active Cinch latching request)" 3 "close (Cinch latching  inactive" ;
VAL_ 547 NDoorFLCloseRequested 0 "Default (Cinch Latching Inactive)" 1 "Reserved" 2 "Open (Active Cinch Latching Request)" 3 "Close (Cinch Latching Inactive)" ;
VAL_ 548 VCU_BMS_PTCOnOff_Sts 0 "off" 1 "on" ;
VAL_ 548 VCU_BMS_ValveOnOff_Sts 0 "close" 1 "open" ;
VAL_ 548 VCU_BMS_PumpFB 0 "OFF" 1 "ON" 2 "Fault" 3 "Reserve" ;
VAL_ 561 NDoorFLHomeSignal 0 "Home" 1 "not Home" ;
VAL_ 561 NDoorFLSecondarySignal 0 "Secondary" 1 "Not Secondary" ;
VAL_ 561 NDoorFLPrimarySignal 0 "Primary" 1 "not Primary" ;
VAL_ 561 NDoorFLClawSignal 0 "Claw" 1 "Not Claw" ;
VAL_ 561 NDoorFLClawStatus 0 "Closed" 1 "Secondary" 2 "Signal Invalid" 3 "Signal Invalid" 4 "Signal Invalid" 5 "Open" 6 "Signal Invalid" 7 "Signal Invalid" 8 "Signal Invalid" 9 "Signal Invalid" 10 "Signal Invalid" 11 "Signal Invalid" 12 "Signal Invalid" 13 "Signal Invalid" 14 "Signal Invalid" 15 "Default" ;
VAL_ 561 BDLFLResponseError 0 "no error" 1 "error" ;
VAL_ 561 NDoorFLOutsideHandleFailure 0 "Default (No Failure)" 1 "EEPROM, ROM and DSP self-test" 2 "Magnetic field is too low" 3 "Magnetic field is too high" 4 "Overvoltage" 5 "Undervoltage" 6 "A/D converter clipping" 7 "Reserved" ;
VAL_ 561 NDoorFLOutsideHandleStatus 0 "Trigger" 1 "Not trigger" ;
VAL_ 561 NDoorLatchFLFailure 0 "no fault" 1 "fault code" 2 "fault code" 3 "fault code" 4 "fault code" 5 "fault code" 6 "fault code" 63 "fault code" ;
VAL_ 565 TowingDetected 0 "Towing not detected" 1 "Towing detected" 3 "Invalid" ;
VAL_ 565 TrailerDetected 0 "Trailer not detected" 1 "Trailer detected" 3 "Invalid" ;
VAL_ 569 NDoorRRHomeSignal 0 "Home" 1 "not Home" ;
VAL_ 569 NDoorRRSecondarySignal 0 "Secondary" 1 "not Secondary" ;
VAL_ 569 NDoorRRPrimarySignal 0 "Primary" 1 "Not Primary" ;
VAL_ 569 NDoorRRClawSignal 0 "Claw" 1 "not Claw" ;
VAL_ 569 NDoorRRClawStatus 0 "Closed" 1 "Secondary" 2 "Signal Invalid" 3 "Signal Invalid" 4 "Signal Invalid" 5 "Open" 6 "Signal Invalid" 7 "Signal Invalid" 8 "Signal Invalid" 9 "Signal Invalid" 10 "Signal Invalid" 11 "Signal Invalid" 12 "Signal Invalid" 13 "Signal Invalid" 14 "Signal Invalid" 15 "Default" ;
VAL_ 569 BDLRRResponseError 0 "no error" 1 "error" ;
VAL_ 569 NDoorRROutsideHandleFailure 0 "Default (No Failure)" 1 "EEPROM, ROM and DSP self-test" 2 "Magnetic field is too low" 3 "Magnetic field is too high" 4 "Overvoltage" 5 "Undervoltage" 6 "A/D converter clipping" 7 "Reserved" ;
VAL_ 569 NDoorRROutsideHandleStatus 0 "Trigger" 1 "Not trigger" ;
VAL_ 569 NDoorLatchRRFailure 0 "No Fault" 1 "Fault Code" 2 "Fault Code" 3 "Fault Code" 4 "Fault Code" 5 "Fault Code" 6 "Fault Code" 7 "Fault Code" 8 "Fault Code" 9 "Fault Code" 10 "Fault Code" 11 "Fault Code" 12 "Fault Code" 13 "Fault Code" 14 "Fault Code" 127 "Fault Code" ;
VAL_ 578 NDoorFRVehicleLocked 0 "default (locked)" 2 "unlocked (inactive)" 3 "locked (full decouple)" ;
VAL_ 578 NDoorFRVehicleMoving 0 "default (in motion)" 2 "static (inactive)" 3 "in motion (decouple external)" ;
VAL_ 578 NDoorFROpenInvRequested 0 "default (release inactive)" 2 "open (active release request)" 3 "close (release inactive)" ;
VAL_ 578 NDoorFROpenRequested 0 "close (release inactive)" 1 "open (release request active)" 3 "default (release inactive)" ;
VAL_ 578 NDoorFRChildLocked 0 "default (locked)" 2 "unlocked (inactive)" 3 "locked (full decouple)" ;
VAL_ 578 NDoorFRVehicleCrash 0 "default (locked)" 1 "Reserved" 2 "Not trigger (inactive)" 3 "Trigger (full decouple)" ;
VAL_ 578 NDoorFRCloseInvRequested 0 "default (Cinch latching  inactive)" 1 "Reserved" 2 "open (active Cinch latching request)" 3 "close (Cinch latching  inactive" ;
VAL_ 578 NDoorFRCloseRequested 0 "Default (Cinch Latching Inactive)" 1 "Reserved" 2 "Open (Active Cinch Latching Request)" 3 "Close (Cinch Latching Inactive)" ;
